VERSION ""

NS_ :

BS_:

BU_: CH DIPF DIPR ETH FC HVI HVS PARTY SDCV VEH VIRT

BO_ 832 VCFRONT_alertMatrix: 8 VEH
 SG_ VCFRONT_a120_DI_DRIVE_MIA m1 : 63|1@1+ (1,0) [0|1] ""  gtw
 SG_ VCFRONT_a180_12VNotSupported m2 : 63|1@1+ (1,0) [0|1] ""  gtw
 SG_ VCFRONT_a060_engineeringBuild m0 : 63|1@1+ (1,0) [0|1] ""  gtw
 SG_ VCFRONT_a119_SCCM_MIA m1 : 62|1@1+ (1,0) [0|1] ""  gtw
 SG_ VCFRONT_a179_highLVAmpsIntoPCS m2 : 62|1@1+ (1,0) [0|1] ""  gtw
 SG_ VCFRONT_a059_inputResistanceHigh m0 : 62|1@1+ (1,0) [0|1] ""  gtw
 SG_ VCFRONT_a239_thmlFanChipComms m3 : 62|1@1+ (1,0) [0|1] ""  gtw
 SG_ VCFRONT_a238_pumpPtChipComms m3 : 61|1@1+ (1,0) [0|1] ""  gtw
 SG_ VCFRONT_a118_VCFRONT_MIA m1 : 61|1@1+ (1,0) [0|1] ""  gtw
 SG_ VCFRONT_a117_VCLEFT_MIA m1 : 60|1@1+ (1,0) [0|1] ""  gtw
 SG_ VCFRONT_a177_mcuAudioEFuseFault m2 : 60|1@1+ (1,0) [0|1] ""  gtw
 SG_ VCFRONT_a237_pumpBatChipComms m3 : 60|1@1+ (1,0) [0|1] ""  gtw
 SG_ VCFRONT_a176_vehicleInSelfTest m2 : 59|1@1+ (1,0) [0|1] ""  gtw
 SG_ VCFRONT_a236_batTempSnsIrrationa m3 : 59|1@1+ (1,0) [0|1] ""  gtw
 SG_ VCFRONT_a116_VCRIGHT_MIA m1 : 59|1@1+ (1,0) [0|1] ""  gtw
 SG_ VCFRONT_a175_ambientTempSns m2 : 58|1@1+ (1,0) [0|1] ""  gtw
 SG_ VCFRONT_a235_ptTempSnsIrrational m3 : 58|1@1+ (1,0) [0|1] ""  gtw
 SG_ VCFRONT_a115_VCSEC_MIA m1 : 58|1@1+ (1,0) [0|1] ""  gtw
 SG_ VCFRONT_a114_ESP_MIA m1 : 57|1@1+ (1,0) [0|1] ""  gtw
 SG_ VCFRONT_a234_autopilot2EFuseFaul m3 : 57|1@1+ (1,0) [0|1] ""  gtw
 SG_ VCFRONT_a174_driveNotAuthed m2 : 57|1@1+ (1,0) [0|1] ""  gtw
 SG_ VCFRONT_a113_UI_MIA m1 : 56|1@1+ (1,0) [0|1] ""  gtw
 SG_ VCFRONT_a173_HVBlckdByMsmtch m2 : 56|1@1+ (1,0) [0|1] ""  gtw
 SG_ VCFRONT_a233_autopilot1EFuseFaul m3 : 56|1@1+ (1,0) [0|1] ""  gtw
 SG_ VCFRONT_a112_EPBL_MIA m1 : 55|1@1+ (1,0) [0|1] ""  gtw
 SG_ VCFRONT_a172_wsteHtBlckdByMsmtch m2 : 55|1@1+ (1,0) [0|1] ""  gtw
 SG_ VCFRONT_a111_EPBR_MIA m1 : 54|1@1+ (1,0) [0|1] ""  gtw
 SG_ VCFRONT_a171_driveBlckdByMsmtch m2 : 54|1@1+ (1,0) [0|1] ""  gtw
 SG_ VCFRONT_a231_12VTempSensShort m3 : 54|1@1+ (1,0) [0|1] ""  gtw
 SG_ VCFRONT_a170_hcmUnderVoltage m2 : 53|1@1+ (1,0) [0|1] ""  gtw
 SG_ VCFRONT_a110_GTW_MIA m1 : 53|1@1+ (1,0) [0|1] ""  gtw
 SG_ VCFRONT_a230_thmlFanFbkSanity m3 : 53|1@1+ (1,0) [0|1] ""  gtw
 SG_ VCFRONT_a169_hcmPhaseEnableFail m2 : 52|1@1+ (1,0) [0|1] ""  gtw
 SG_ VCFRONT_a349_vbatFusedFastTripSl m5 : 52|1@1+ (1,0) [0|1] ""  gtw
 SG_ VCFRONT_a229_pumpPtFbkSanity m3 : 52|1@1+ (1,0) [0|1] ""  gtw
 SG_ VCFRONT_a109_RCM_MIA m1 : 52|1@1+ (1,0) [0|1] ""  gtw
 SG_ VCFRONT_a108_DIS_MIA m1 : 51|1@1+ (1,0) [0|1] ""  gtw
 SG_ VCFRONT_a228_pumpBatFbkSanity m3 : 51|1@1+ (1,0) [0|1] ""  gtw
 SG_ VCFRONT_a348_espFastTripSlope m5 : 51|1@1+ (1,0) [0|1] ""  gtw
 SG_ VCFRONT_a168_hcmShortToVBAT m2 : 51|1@1+ (1,0) [0|1] ""  gtw
 SG_ VCFRONT_a107_BMS_MIA m1 : 50|1@1+ (1,0) [0|1] ""  gtw
 SG_ VCFRONT_a167_leftHCMMIA m2 : 50|1@1+ (1,0) [0|1] ""  gtw
 SG_ VCFRONT_a347_iboosterFastTripSlo m5 : 50|1@1+ (1,0) [0|1] ""  gtw
 SG_ VCFRONT_a346_epas3sFastTripSlope m5 : 49|1@1+ (1,0) [0|1] ""  gtw
 SG_ VCFRONT_a106_PCS_MIA m1 : 49|1@1+ (1,0) [0|1] ""  gtw
 SG_ VCFRONT_a046_Task1000msError m0 : 49|1@1+ (1,0) [0|1] ""  gtw
 SG_ VCFRONT_a226_railAPoweredForFrun m3 : 49|1@1+ (1,0) [0|1] ""  gtw
 SG_ VCFRONT_a166_rightHCMMIA m2 : 49|1@1+ (1,0) [0|1] ""  gtw
 SG_ VCFRONT_a045_Task100msError m0 : 48|1@1+ (1,0) [0|1] ""  gtw
 SG_ VCFRONT_a165_unxpctdEFuseLckout m2 : 48|1@1+ (1,0) [0|1] ""  gtw
 SG_ VCFRONT_a225_driveBlckdByShowroo m3 : 48|1@1+ (1,0) [0|1] ""  gtw
 SG_ VCFRONT_a345_epas3pFastTripSlope m5 : 48|1@1+ (1,0) [0|1] ""  gtw
 SG_ VCFRONT_a105_TAS_MIA m1 : 48|1@1+ (1,0) [0|1] ""  gtw
 SG_ VCFRONT_a224_revBatChrgPmpFault m3 : 47|1@1+ (1,0) [0|1] ""  gtw
 SG_ VCFRONT_a164_eFuseLckoutMissing m2 : 47|1@1+ (1,0) [0|1] ""  gtw
 SG_ VCFRONT_a344_pcsFastTripSlope m5 : 47|1@1+ (1,0) [0|1] ""  gtw
 SG_ VCFRONT_a044_Task10msError m0 : 47|1@1+ (1,0) [0|1] ""  gtw
 SG_ VCFRONT_a104_DAS_MIA m1 : 47|1@1+ (1,0) [0|1] ""  gtw
 SG_ VCFRONT_a283_thmlFanLimitedByCur m4 : 46|1@1+ (1,0) [0|1] ""  gtw
 SG_ VCFRONT_a103_CP_MIA m1 : 46|1@1+ (1,0) [0|1] ""  gtw
 SG_ VCFRONT_a343_vcrightFastTripSlop m5 : 46|1@1+ (1,0) [0|1] ""  gtw
 SG_ VCFRONT_a043_Task1msError m0 : 46|1@1+ (1,0) [0|1] ""  gtw
 SG_ VCFRONT_a223_12VTempSensDiscnect m3 : 46|1@1+ (1,0) [0|1] ""  gtw
 SG_ VCFRONT_a042_HighStackUsage m0 : 45|1@1+ (1,0) [0|1] ""  gtw
 SG_ VCFRONT_a102_PTC_MIA m1 : 45|1@1+ (1,0) [0|1] ""  gtw
 SG_ VCFRONT_a342_vcleftFastTripSlope m5 : 45|1@1+ (1,0) [0|1] ""  gtw
 SG_ VCFRONT_a222_rightTurnLightFault m3 : 45|1@1+ (1,0) [0|1] ""  gtw
 SG_ VCFRONT_a041_HighCPULoad m0 : 44|1@1+ (1,0) [0|1] ""  gtw
 SG_ VCFRONT_a101_PM_MIA m1 : 44|1@1+ (1,0) [0|1] ""  gtw
 SG_ VCFRONT_a161_compressorSelfFault m2 : 44|1@1+ (1,0) [0|1] ""  gtw
 SG_ VCFRONT_a221_leftTurnLightFault m3 : 44|1@1+ (1,0) [0|1] ""  gtw
 SG_ VCFRONT_a341_vbatFusedFastTripOC m5 : 44|1@1+ (1,0) [0|1] ""  gtw
 SG_ VCFRONT_a160_compressorInhibited m2 : 43|1@1+ (1,0) [0|1] ""  gtw
 SG_ VCFRONT_a100_CANbus_MIA m1 : 43|1@1+ (1,0) [0|1] ""  gtw
 SG_ VCFRONT_a340_espFastTripOCMax m5 : 43|1@1+ (1,0) [0|1] ""  gtw
 SG_ VCFRONT_a220_reverseBatteryFault m3 : 43|1@1+ (1,0) [0|1] ""  gtw
 SG_ VCFRONT_a099_PARK_MIA m1 : 42|1@1+ (1,0) [0|1] ""  gtw
 SG_ VCFRONT_a159_fiveWayValveFault m2 : 42|1@1+ (1,0) [0|1] ""  gtw
 SG_ VCFRONT_a219_12VVoltFloorRchd m3 : 42|1@1+ (1,0) [0|1] ""  gtw
 SG_ VCFRONT_a339_iboosterFastTripOCM m5 : 42|1@1+ (1,0) [0|1] ""  gtw
 SG_ VCFRONT_a338_epas3sFastTripOCMax m5 : 41|1@1+ (1,0) [0|1] ""  gtw
 SG_ VCFRONT_a158_louverDisconnected m2 : 41|1@1+ (1,0) [0|1] ""  gtw
 SG_ VCFRONT_a098_DI_THERMAL_MIA m1 : 41|1@1+ (1,0) [0|1] ""  gtw
 SG_ VCFRONT_a157_louverBreakage m2 : 40|1@1+ (1,0) [0|1] ""  gtw
 SG_ VCFRONT_a337_epas3pFastTripOCMax m5 : 40|1@1+ (1,0) [0|1] ""  gtw
 SG_ VCFRONT_a097_CMP_MIA m1 : 40|1@1+ (1,0) [0|1] ""  gtw
 SG_ VCFRONT_a156_louverBlockage m2 : 39|1@1+ (1,0) [0|1] ""  gtw
 SG_ VCFRONT_a336_pcsFastTripOCMax m5 : 39|1@1+ (1,0) [0|1] ""  gtw
 SG_ VCFRONT_a335_vcrightFastTripOCMa m5 : 38|1@1+ (1,0) [0|1] ""  gtw
 SG_ VCFRONT_a215_airCompDriverFault m3 : 38|1@1+ (1,0) [0|1] ""  gtw
 SG_ VCFRONT_a214_airCompUnderCurrent m3 : 37|1@1+ (1,0) [0|1] ""  gtw
 SG_ VCFRONT_a334_vcleftFastTripOCMax m5 : 37|1@1+ (1,0) [0|1] ""  gtw
 SG_ VCFRONT_a333_vbatFusedSlowTripOC m5 : 36|1@1+ (1,0) [0|1] ""  gtw
 SG_ VCFRONT_a213_12VOvercharge m3 : 36|1@1+ (1,0) [0|1] ""  gtw
 SG_ VCFRONT_a212_IBSOverTemp m3 : 35|1@1+ (1,0) [0|1] ""  gtw
 SG_ VCFRONT_a152_thmlFanLowRPMCBang m2 : 35|1@1+ (1,0) [0|1] ""  gtw
 SG_ VCFRONT_a332_espSlowTripOC m5 : 35|1@1+ (1,0) [0|1] ""  gtw
 SG_ VCFRONT_a151_pumpPtLowRPMCBang m2 : 34|1@1+ (1,0) [0|1] ""  gtw
 SG_ VCFRONT_a211_I2CFault m3 : 34|1@1+ (1,0) [0|1] ""  gtw
 SG_ VCFRONT_a031_UDSActive m0 : 34|1@1+ (1,0) [0|1] ""  gtw
 SG_ VCFRONT_a331_iboosterSlowTripOC m5 : 34|1@1+ (1,0) [0|1] ""  gtw
 SG_ VCFRONT_a330_epas3sSlowTripOC m5 : 33|1@1+ (1,0) [0|1] ""  gtw
 SG_ VCFRONT_a030_ECULogUploadRequest m0 : 33|1@1+ (1,0) [0|1] ""  gtw
 SG_ VCFRONT_a210_fiveWayValveCalib m3 : 33|1@1+ (1,0) [0|1] ""  gtw
 SG_ VCFRONT_a150_pumpBatLowRPMCBang m2 : 33|1@1+ (1,0) [0|1] ""  gtw
 SG_ VCFRONT_a329_epas3pSlowTripOC m5 : 32|1@1+ (1,0) [0|1] ""  gtw
 SG_ VCFRONT_a149_BLEFrontPowerCycled m2 : 32|1@1+ (1,0) [0|1] ""  gtw
 SG_ VCFRONT_a269_partialLoadShed m4 : 32|1@1+ (1,0) [0|1] ""  gtw
 SG_ VCFRONT_a209_brakeFluidSNA m3 : 32|1@1+ (1,0) [0|1] ""  gtw
 SG_ VCFRONT_a208_brakeFluidLow m3 : 31|1@1+ (1,0) [0|1] ""  gtw
 SG_ VCFRONT_a328_pcsSlowTripOC m5 : 31|1@1+ (1,0) [0|1] ""  gtw
 SG_ VCFRONT_a268_vbatFusedVoltageMis m4 : 31|1@1+ (1,0) [0|1] ""  gtw
 SG_ VCFRONT_a148_thmlFanSoftStall m2 : 31|1@1+ (1,0) [0|1] ""  gtw
 SG_ VCFRONT_a267_EPAS3sVoltageMismat m4 : 30|1@1+ (1,0) [0|1] ""  gtw
 SG_ VCFRONT_a147_pumpPtSoftStall m2 : 30|1@1+ (1,0) [0|1] ""  gtw
 SG_ VCFRONT_a207_vbatFusdSelfTestFai m3 : 30|1@1+ (1,0) [0|1] ""  gtw
 SG_ VCFRONT_a327_vcrightSlowTripOC m5 : 30|1@1+ (1,0) [0|1] ""  gtw
 SG_ VCFRONT_a146_pumpBatSoftStall m2 : 29|1@1+ (1,0) [0|1] ""  gtw
 SG_ VCFRONT_a266_EPAS3pVoltageMismat m4 : 29|1@1+ (1,0) [0|1] ""  gtw
 SG_ VCFRONT_a326_vcleftSlowTripOC m5 : 29|1@1+ (1,0) [0|1] ""  gtw
 SG_ VCFRONT_a206_espSelfTestFail m3 : 29|1@1+ (1,0) [0|1] ""  gtw
 SG_ VCFRONT_a265_ESPVoltageMismatch m4 : 28|1@1+ (1,0) [0|1] ""  gtw
 SG_ VCFRONT_a205_iBoosterSelfTestFai m3 : 28|1@1+ (1,0) [0|1] ""  gtw
 SG_ VCFRONT_a145_thmlFanICTransFault m2 : 28|1@1+ (1,0) [0|1] ""  gtw
 SG_ VCFRONT_a325_vbatFusedOvertempMa m5 : 28|1@1+ (1,0) [0|1] ""  gtw
 SG_ VCFRONT_a264_iBoosterVoltageMism m4 : 27|1@1+ (1,0) [0|1] ""  gtw
 SG_ VCFRONT_a144_pumpPtICTransFault m2 : 27|1@1+ (1,0) [0|1] ""  gtw
 SG_ VCFRONT_a324_espOvertempMax m5 : 27|1@1+ (1,0) [0|1] ""  gtw
 SG_ VCFRONT_a204_epas3sSelfTestFail m3 : 27|1@1+ (1,0) [0|1] ""  gtw
 SG_ VCFRONT_a263_pcsVoltageMismatch m4 : 26|1@1+ (1,0) [0|1] ""  gtw
 SG_ VCFRONT_a143_pumpBatICTransFault m2 : 26|1@1+ (1,0) [0|1] ""  gtw
 SG_ VCFRONT_a203_epas3pSelfTestFail m3 : 26|1@1+ (1,0) [0|1] ""  gtw
 SG_ VCFRONT_a323_iboosterOvertempMax m5 : 26|1@1+ (1,0) [0|1] ""  gtw
 SG_ VCFRONT_a262_vcrightVoltageMisma m4 : 25|1@1+ (1,0) [0|1] ""  gtw
 SG_ VCFRONT_a202_pcsSelfTestFail m3 : 25|1@1+ (1,0) [0|1] ""  gtw
 SG_ VCFRONT_a322_epas3sOvertempMax m5 : 25|1@1+ (1,0) [0|1] ""  gtw
 SG_ VCFRONT_a142_exvMotorFault m2 : 25|1@1+ (1,0) [0|1] ""  gtw
 SG_ VCFRONT_a022_TaskInitError m0 : 25|1@1+ (1,0) [0|1] ""  gtw
 SG_ VCFRONT_a141_coolantTempBatSns m2 : 24|1@1+ (1,0) [0|1] ""  gtw
 SG_ VCFRONT_a021_TaskSchedulerError m0 : 24|1@1+ (1,0) [0|1] ""  gtw
 SG_ VCFRONT_a201_vcrightSelfTestFail m3 : 24|1@1+ (1,0) [0|1] ""  gtw
 SG_ VCFRONT_a261_vcleftVoltageMismat m4 : 24|1@1+ (1,0) [0|1] ""  gtw
 SG_ VCFRONT_a321_epas3pOvertempMax m5 : 24|1@1+ (1,0) [0|1] ""  gtw
 SG_ VCFRONT_a200_vcleftSelfTestFail m3 : 23|1@1+ (1,0) [0|1] ""  gtw
 SG_ VCFRONT_a260_dead12VBattery m4 : 23|1@1+ (1,0) [0|1] ""  gtw
 SG_ VCFRONT_a320_pcsOvertempMax m5 : 23|1@1+ (1,0) [0|1] ""  gtw
 SG_ VCFRONT_a140_coolantTempPtSns m2 : 23|1@1+ (1,0) [0|1] ""  gtw
 SG_ VCFRONT_a139_refrigSuctPresSns m2 : 22|1@1+ (1,0) [0|1] ""  gtw
 SG_ VCFRONT_a319_vcrightOvertempMax m5 : 22|1@1+ (1,0) [0|1] ""  gtw
 SG_ VCFRONT_a199_PRVCANUndertrminate m3 : 22|1@1+ (1,0) [0|1] ""  gtw
 SG_ VCFRONT_a259_12vVoltageDropOnHig m4 : 22|1@1+ (1,0) [0|1] ""  gtw
 SG_ VCFRONT_a198_PRVCANOverterminate m3 : 21|1@1+ (1,0) [0|1] ""  gtw
 SG_ VCFRONT_a138_refrigSuctTempSns m2 : 21|1@1+ (1,0) [0|1] ""  gtw
 SG_ VCFRONT_a258_resistanceEstimatio m4 : 21|1@1+ (1,0) [0|1] ""  gtw
 SG_ VCFRONT_a318_vcleftOvertempMax m5 : 21|1@1+ (1,0) [0|1] ""  gtw
 SG_ VCFRONT_a317_vbatFusedOvertempSl m5 : 20|1@1+ (1,0) [0|1] ""  gtw
 SG_ VCFRONT_a257_portExpanderVOR m4 : 20|1@1+ (1,0) [0|1] ""  gtw
 SG_ VCFRONT_a137_refrigDischPresSns m2 : 20|1@1+ (1,0) [0|1] ""  gtw
 SG_ VCFRONT_a196_discnctd12VBattery m3 : 19|1@1+ (1,0) [0|1] ""  gtw
 SG_ VCFRONT_a316_espOvertempSlope m5 : 19|1@1+ (1,0) [0|1] ""  gtw
 SG_ VCFRONT_a256_compTornShaftSeal m4 : 19|1@1+ (1,0) [0|1] ""  gtw
 SG_ VCFRONT_a136_refrigDischTempSns m2 : 19|1@1+ (1,0) [0|1] ""  gtw
 SG_ VCFRONT_a255_pumpPtStopped m4 : 18|1@1+ (1,0) [0|1] ""  gtw
 SG_ VCFRONT_a015_NVMMAlert m0 : 18|1@1+ (1,0) [0|1] ""  gtw
 SG_ VCFRONT_a135_coolantLevelLow m2 : 18|1@1+ (1,0) [0|1] ""  gtw
 SG_ VCFRONT_a315_iboosterOvertempSlo m5 : 18|1@1+ (1,0) [0|1] ""  gtw
 SG_ VCFRONT_a195_drveBlckdVltgeTooHg m3 : 18|1@1+ (1,0) [0|1] ""  gtw
 SG_ VCFRONT_a314_epas3sOvertempSlope m5 : 17|1@1+ (1,0) [0|1] ""  gtw
 SG_ VCFRONT_a134_fusedHighEFuseTrip m2 : 17|1@1+ (1,0) [0|1] ""  gtw
 SG_ VCFRONT_a254_pumpBatStopped m4 : 17|1@1+ (1,0) [0|1] ""  gtw
 SG_ VCFRONT_a194_iBoosterRetry m3 : 17|1@1+ (1,0) [0|1] ""  gtw
 SG_ VCFRONT_a013_AlertManagerFault m0 : 16|1@1+ (1,0) [0|1] ""  gtw
 SG_ VCFRONT_a133_espEFuseTrip m2 : 16|1@1+ (1,0) [0|1] ""  gtw
 SG_ VCFRONT_a193_mcuAudioRetry m3 : 16|1@1+ (1,0) [0|1] ""  gtw
 SG_ VCFRONT_a253_maxChrgeSssionTmeou m4 : 16|1@1+ (1,0) [0|1] ""  gtw
 SG_ VCFRONT_a313_epas3pOvertempSlope m5 : 16|1@1+ (1,0) [0|1] ""  gtw
 SG_ VCFRONT_a132_iBoosterEFuseTrip m2 : 15|1@1+ (1,0) [0|1] ""  gtw
 SG_ VCFRONT_a252_frontControllerWake m4 : 15|1@1+ (1,0) [0|1] ""  gtw
 SG_ VCFRONT_a192_criticalLoadShed m3 : 15|1@1+ (1,0) [0|1] ""  gtw
 SG_ VCFRONT_a012_CPUReset m0 : 15|1@1+ (1,0) [0|1] ""  gtw
 SG_ VCFRONT_a312_pcsOvertempSlope m5 : 15|1@1+ (1,0) [0|1] ""  gtw
 SG_ VCFRONT_a191_exitDriveLow12V m3 : 14|1@1+ (1,0) [0|1] ""  gtw
 SG_ VCFRONT_a251_UIWakeupTrigger m4 : 14|1@1+ (1,0) [0|1] ""  gtw
 SG_ VCFRONT_a311_vcrightOvertempSlop m5 : 14|1@1+ (1,0) [0|1] ""  gtw
 SG_ VCFRONT_a131_epas3sEFuseTrip m2 : 14|1@1+ (1,0) [0|1] ""  gtw
 SG_ VCFRONT_a310_vcleftOvertempSlope m5 : 13|1@1+ (1,0) [0|1] ""  gtw
 SG_ VCFRONT_a250_headlampsNotAimed m4 : 13|1@1+ (1,0) [0|1] ""  gtw
 SG_ VCFRONT_a010_ExtSupplyVoltError m0 : 13|1@1+ (1,0) [0|1] ""  gtw
 SG_ VCFRONT_a130_epas3pEFuseTrip m2 : 13|1@1+ (1,0) [0|1] ""  gtw
 SG_ VCFRONT_a129_pcsEFuseTrip m2 : 12|1@1+ (1,0) [0|1] ""  gtw
 SG_ VCFRONT_a189_IBSMIA m3 : 12|1@1+ (1,0) [0|1] ""  gtw
 SG_ VCFRONT_a249_fiveWayValveBadMode m4 : 12|1@1+ (1,0) [0|1] ""  gtw
 SG_ VCFRONT_a188_sleepFailed m3 : 11|1@1+ (1,0) [0|1] ""  gtw
 SG_ VCFRONT_a128_vcrightEFuseTrip m2 : 11|1@1+ (1,0) [0|1] ""  gtw
 SG_ VCFRONT_a248_voltageOutOfSpec m4 : 11|1@1+ (1,0) [0|1] ""  gtw
 SG_ VCFRONT_a127_vcleftEFuseTrip m2 : 10|1@1+ (1,0) [0|1] ""  gtw
 SG_ VCFRONT_a187_busesNotSleeping m3 : 10|1@1+ (1,0) [0|1] ""  gtw
 SG_ VCFRONT_a247_evapSolenoidFault m4 : 10|1@1+ (1,0) [0|1] ""  gtw
 SG_ VCFRONT_a246_pump2EFuseFault m4 : 9|1@1+ (1,0) [0|1] ""  gtw
 SG_ VCFRONT_a126_thmlFanICWarning m2 : 9|1@1+ (1,0) [0|1] ""  gtw
 SG_ VCFRONT_a186_noDriveChgCableCon m3 : 9|1@1+ (1,0) [0|1] ""  gtw
 SG_ VCFRONT_a125_thmlFanICLatchFault m2 : 8|1@1+ (1,0) [0|1] ""  gtw
 SG_ VCFRONT_a245_pump1EFuseFault m4 : 8|1@1+ (1,0) [0|1] ""  gtw
 SG_ VCFRONT_a185_washerFluidLow m3 : 8|1@1+ (1,0) [0|1] ""  gtw
 SG_ VCFRONT_a244_sleepBypassFault m4 : 7|1@1+ (1,0) [0|1] ""  gtw
 SG_ VCFRONT_a064_busSleepReqTimeout m1 : 7|1@1+ (1,0) [0|1] ""  gtw
 SG_ VCFRONT_a124_pumpPtICWarning m2 : 7|1@1+ (1,0) [0|1] ""  gtw
 SG_ VCFRONT_a123_pumpPtICLatchFault m2 : 6|1@1+ (1,0) [0|1] ""  gtw
 SG_ VCFRONT_a183_low12VCapacity m3 : 6|1@1+ (1,0) [0|1] ""  gtw
 SG_ VCFRONT_a063_SwitchFault m1 : 6|1@1+ (1,0) [0|1] ""  gtw
 SG_ VCFRONT_a003_SWAssertion m0 : 6|1@1+ (1,0) [0|1] ""  gtw
 SG_ VCFRONT_a243_12VOverchargeInstc m4 : 6|1@1+ (1,0) [0|1] ""  gtw
 SG_ VCFRONT_a002_PowerLossReset m0 : 5|1@1+ (1,0) [0|1] ""  gtw
 SG_ VCFRONT_a062_XCPWasConnected m1 : 5|1@1+ (1,0) [0|1] ""  gtw
 SG_ VCFRONT_a182_replace12VBattery m3 : 5|1@1+ (1,0) [0|1] ""  gtw
 SG_ VCFRONT_a302_wiperCommError m5 : 5|1@1+ (1,0) [0|1] ""  gtw
 SG_ VCFRONT_a122_pumpBatICWarning m2 : 5|1@1+ (1,0) [0|1] ""  gtw
 SG_ VCFRONT_a061_XCPConnected m1 : 4|1@1+ (1,0) [0|1] ""  gtw
 SG_ VCFRONT_a121_pumpBatICLatchFault m2 : 4|1@1+ (1,0) [0|1] ""  gtw
 SG_ VCFRONT_a001_WatchdogReset m0 : 4|1@1+ (1,0) [0|1] ""  gtw
 SG_ VCFRONT_a301_wipersFactoryDisabl m5 : 4|1@1+ (1,0) [0|1] ""  gtw
 SG_ VCFRONT_matrixIndex M : 0|4@1+ (1,0) [0|15] ""  gtw

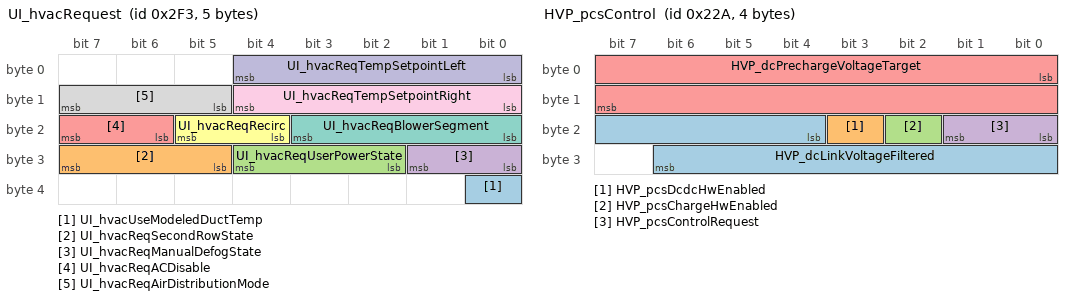
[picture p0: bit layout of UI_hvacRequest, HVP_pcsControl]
BO_ 755 UI_hvacRequest: 5 VEH
 SG_ UI_hvacUseModeledDuctTemp : 32|1@1+ (1,0) [0|1] ""  X
 SG_ UI_hvacReqSecondRowState : 29|3@1+ (1,0) [0|4] ""  vcright
 SG_ UI_hvacReqUserPowerState : 26|3@1+ (1,0) [0|4] ""  vcfront
 SG_ UI_hvacReqManualDefogState : 24|2@1+ (1,0) [0|2] ""  aps
 SG_ UI_hvacReqACDisable : 22|2@1+ (1,0) [0|2] ""  vcright
 SG_ UI_hvacReqRecirc : 20|2@1+ (1,0) [0|2] ""  vcright
 SG_ UI_hvacReqBlowerSegment : 16|4@1+ (1,0) [0|11] ""  vcright
 SG_ UI_hvacReqAirDistributionMode : 13|3@1+ (1,0) [0|7] ""  vcright
 SG_ UI_hvacReqTempSetpointRight : 8|5@1+ (0.5,15) [15|28] "degC"  vcright
 SG_ UI_hvacReqTempSetpointLeft : 0|5@1+ (0.5,15) [15|28] "degC"  vcright

BO_ 554 HVP_pcsControl: 4 VEH
 SG_ HVP_dcLinkVoltageFiltered : 20|11@1- (1,0) [-550|550] "V"  X
 SG_ HVP_pcsDcdcHwEnabled : 19|1@1+ (1,0) [0|1] ""  gtw
 SG_ HVP_pcsChargeHwEnabled : 18|1@1+ (1,0) [0|1] ""  gtw
 SG_ HVP_pcsControlRequest : 16|2@1+ (1,0) [0|3] ""  dbg
 SG_ HVP_dcPrechargeVoltageTarget : 0|16@1- (0.1,0) [-550|550] "V"  gtw

BO_ 815 SCM_alertMatrix1: 8 VEH
 SG_ SCM_a064_vehicleCommandTimeout : 63|1@1+ (1,0) [0|1] ""  gtw
 SG_ SCM_a063_canRationality : 62|1@1+ (1,0) [0|1] ""  gtw
 SG_ SCM_a062_unused : 61|1@1+ (1,0) [0|1] ""  gtw
 SG_ SCM_a061_postOutOfService : 60|1@1+ (1,0) [0|1] ""  gtw
 SG_ SCM_a060_swHVIL : 59|1@1+ (1,0) [0|1] ""  gtw
 SG_ SCM_a059_memoryError : 58|1@1+ (1,0) [0|1] ""  gtw
 SG_ SCM_a058_adcRef : 57|1@1+ (1,0) [0|1] ""  gtw
 SG_ SCM_a057_watchdogReset : 56|1@1+ (1,0) [0|1] ""  gtw
 SG_ SCM_a056_stateTransitionDenied : 55|1@1+ (1,0) [0|1] ""  gtw
 SG_ SCM_a055_coolantLevelLow : 54|1@1+ (1,0) [0|1] ""  gtw
 SG_ SCM_a054_pumpRegulation : 53|1@1+ (1,0) [0|1] ""  gtw
 SG_ SCM_a053_unexpectedThermalBehavi : 52|1@1+ (1,0) [0|1] ""  gtw
 SG_ SCM_a052_ambientTempRationality : 51|1@1+ (1,0) [0|1] ""  gtw
 SG_ SCM_a051_cordTempRationality : 50|1@1+ (1,0) [0|1] ""  gtw
 SG_ SCM_a050_coolantTempRationality : 49|1@1+ (1,0) [0|1] ""  gtw
 SG_ SCM_a049_pcbaTempRationality : 48|1@1+ (1,0) [0|1] ""  gtw
 SG_ SCM_a048_ambientOT : 47|1@1+ (1,0) [0|1] ""  gtw
 SG_ SCM_a047_cordOT : 46|1@1+ (1,0) [0|1] ""  gtw
 SG_ SCM_a046_coolantOT : 45|1@1+ (1,0) [0|1] ""  gtw
 SG_ SCM_a045_pcbaOT : 44|1@1+ (1,0) [0|1] ""  gtw
 SG_ SCM_a044_proximityRationality : 43|1@1+ (1,0) [0|1] ""  gtw
 SG_ SCM_a043_pilotRationality : 42|1@1+ (1,0) [0|1] ""  gtw
 SG_ SCM_a042_pilotOutOfRange : 41|1@1+ (1,0) [0|1] ""  gtw
 SG_ SCM_a041_minus12VOutOfRange : 40|1@1+ (1,0) [0|1] ""  gtw
 SG_ SCM_a040_plus12VOutOfRange : 39|1@1+ (1,0) [0|1] ""  gtw
 SG_ SCM_a039_ibatRegulation : 38|1@1+ (1,0) [0|1] ""  gtw
 SG_ SCM_a038_contactorFailedOpen : 37|1@1+ (1,0) [0|1] ""  gtw
 SG_ SCM_a037_outputContactorWelded : 36|1@1+ (1,0) [0|1] ""  gtw
 SG_ SCM_a036_internalContactorWelded : 35|1@1+ (1,0) [0|1] ""  gtw
 SG_ SCM_a035_unexpectedVbusBehavior : 34|1@1+ (1,0) [0|1] ""  gtw
 SG_ SCM_a034_IBatRationality : 33|1@1+ (1,0) [0|1] ""  gtw
 SG_ SCM_a033_VBusRationality : 32|1@1+ (1,0) [0|1] ""  gtw
 SG_ SCM_a032_VBatRationality : 31|1@1+ (1,0) [0|1] ""  gtw
 SG_ SCM_a031_IbatOC : 30|1@1+ (1,0) [0|1] ""  gtw
 SG_ SCM_a030_VbusOV : 29|1@1+ (1,0) [0|1] ""  gtw
 SG_ SCM_a029_VbatOV : 28|1@1+ (1,0) [0|1] ""  gtw
 SG_ SCM_a028_isolationRationality : 27|1@1+ (1,0) [0|1] ""  gtw
 SG_ SCM_a027_externalIsolationLow : 26|1@1+ (1,0) [0|1] ""  gtw
 SG_ SCM_a026_internalIsolationLow : 25|1@1+ (1,0) [0|1] ""  gtw
 SG_ SCM_a025_internalIsolationFault : 24|1@1+ (1,0) [0|1] ""  gtw
 SG_ SCM_a024_emergencyShutdown : 23|1@1+ (1,0) [0|1] ""  gtw
 SG_ SCM_a021_unusedHW21 : 20|1@1+ (1,0) [0|1] ""  gtw
 SG_ SCM_a020_unusedHW20 : 19|1@1+ (1,0) [0|1] ""  gtw
 SG_ SCM_a019_unusedHW19 : 18|1@1+ (1,0) [0|1] ""  gtw
 SG_ SCM_a018_unusedHW18 : 17|1@1+ (1,0) [0|1] ""  gtw
 SG_ SCM_a017_unusedHW17 : 16|1@1+ (1,0) [0|1] ""  gtw
 SG_ SCM_a016_unusedHW16 : 15|1@1+ (1,0) [0|1] ""  gtw
 SG_ SCM_a015_unusedHW15 : 14|1@1+ (1,0) [0|1] ""  gtw
 SG_ SCM_a014_coolantTempHiFoldBk : 13|1@1+ (1,0) [0|1] ""  gtw
 SG_ SCM_a013_cordTempHiFoldBk : 12|1@1+ (1,0) [0|1] ""  gtw
 SG_ SCM_a012_hwIllegalCntrCmdV2 : 11|1@1+ (1,0) [0|1] ""  gtw
 SG_ SCM_a011_hwIllegalCntrCmdInt : 10|1@1+ (1,0) [0|1] ""  gtw
 SG_ SCM_a010_hwIllegalCntrCmdV1 : 9|1@1+ (1,0) [0|1] ""  gtw
 SG_ SCM_a009_hwOpen_V2 : 8|1@1+ (1,0) [0|1] ""  gtw
 SG_ SCM_a008_hwOpen_V1 : 7|1@1+ (1,0) [0|1] ""  gtw
 SG_ SCM_a007_hwWeld_V2 : 6|1@1+ (1,0) [0|1] ""  gtw
 SG_ SCM_a006_hwWeld_V1 : 5|1@1+ (1,0) [0|1] ""  gtw
 SG_ SCM_a005_hwHVIL : 4|1@1+ (1,0) [0|1] ""  gtw
 SG_ SCM_a004_hwVbusOV : 3|1@1+ (1,0) [0|1] ""  gtw
 SG_ SCM_a003_hwCordOT : 2|1@1+ (1,0) [0|1] ""  gtw
 SG_ SCM_a002_hwIbatOC : 1|1@1+ (1,0) [0|1] ""  gtw
 SG_ SCM_a001_hwDSPfault : 0|1@1+ (1,0) [0|1] ""  gtw

BO_ 805 FC_alertMatrix1: 8 VEH
 SG_ FC_a002_scPowerShared : 1|1@1+ (1,0) [0|1] ""  gtw
 SG_ FC_a001_scPostOutOfService : 0|1@1+ (1,0) [0|1] ""  gtw

BO_ 1354 SCS_alertLog: 8 VEH
 SG_ SCS_a069_vStage4 m69 : 52|12@1+ (0.14652014653,0) [0|600] "V"  gtw
 SG_ SCS_a070_vStage4 m70 : 52|12@1+ (0.14652014653,0) [0|600] "V"  gtw
 SG_ SCS_a058_alertData3 m58 : 48|16@1- (1,0) [-32767|32767] "-"  gtw
 SG_ SCS_a013_Ui m13 : 48|16@1- (0.0009765625,0) [-31|31] "-"  gtw
 SG_ SCS_a065_vBat3 m65 : 40|12@1+ (0.14652014653,0) [0|600] "V"  gtw
 SG_ SCS_a066_vBat6 m66 : 40|12@1+ (0.14652014653,0) [0|600] "V"  gtw
 SG_ SCS_a075_avgDecayTime m75 : 40|16@1+ (1,0) [0|65535] "mS"  gtw
 SG_ SCS_a069_vStage3 m69 : 40|12@1+ (0.14652014653,0) [0|600] "V"  gtw
 SG_ SCS_a070_vStage3 m70 : 40|12@1+ (0.14652014653,0) [0|600] "V"  gtw
 SG_ SCS_a068_vBat12 m68 : 40|12@1+ (0.14652014653,0) [0|600] "V"  gtw
 SG_ SCS_a067_vBat9 m67 : 40|12@1+ (0.14652014653,0) [0|600] "V"  gtw
 SG_ SCS_a060_rawHvilStatus m60 : 34|30@1+ (1,0) [0|1073741823] ""  gtw
 SG_ SCS_a060_rawHvilChainNum m60 : 32|2@1+ (1,0) [0|3] ""  gtw
 SG_ SCS_a013_Up m13 : 32|16@1- (0.0009765625,0) [-31|31] "-"  gtw
 SG_ SCS_a075_chargerConfig m75 : 32|8@1+ (1,0) [0|255] ""  gtw
 SG_ SCS_a058_refVoltageLowAvg m58 : 32|16@1+ (4.574e-05,-0.006861) [-0.00686|2.99071] "V"  gtw
 SG_ SCS_a066_vBat5 m66 : 28|12@1+ (0.14652014653,0) [0|600] "V"  gtw
 SG_ SCS_a070_vStage2 m70 : 28|12@1+ (0.14652014653,0) [0|600] "V"  gtw
 SG_ SCS_a069_vStage2 m69 : 28|12@1+ (0.14652014653,0) [0|600] "V"  gtw
 SG_ SCS_a060_hvil2faultCode m60 : 28|4@1+ (1,0) [0|15] ""  gtw
 SG_ SCS_a065_vBat2 m65 : 28|12@1+ (0.14652014653,0) [0|600] "V"  gtw
 SG_ SCS_a074_voltageWithoutRo m74 : 28|12@1+ (0.14652014653,0) [0|600] "V"  gtw
 SG_ SCS_a068_vBat11 m68 : 28|12@1+ (0.14652014653,0) [0|600] "V"  gtw
 SG_ SCS_a067_vBat8 m67 : 28|12@1+ (0.14652014653,0) [0|600] "V"  gtw
 SG_ SCS_a060_hvil2chargerNum m60 : 24|4@1+ (1,0) [0|15] ""  gtw
 SG_ SCS_a060_hvil1faultCode m60 : 20|4@1+ (1,0) [0|15] ""  gtw
 SG_ SCS_a083_currentLimit m83 : 20|16@1+ (0.02,0) [0|1310.7] "A"  gtw
 SG_ SCS_a069_vStage1 m69 : 16|12@1+ (0.14652014653,0) [0|600] "V"  gtw
 SG_ SCS_a070_vStage1 m70 : 16|12@1+ (0.14652014653,0) [0|600] "V"  gtw
 SG_ SCS_a035_vBus m35 : 16|12@1+ (0.14652014653,0) [0|600] "V"  gtw
 SG_ SCS_a081_vLine m81 : 16|12@1+ (0.14652014653,0) [0|600] "V"  gtw
 SG_ SCS_a077_vBat m77 : 16|12@1+ (0.14652014653,0) [0|600] "V"  gtw
 SG_ SCS_a071_chargerMiaMask m71 : 16|16@1+ (1,0) [0|65535] ""  gtw
 SG_ SCS_a067_vBat7 m67 : 16|12@1+ (0.14652014653,0) [0|600] "V"  gtw
 SG_ SCS_a075_decayTime m75 : 16|16@1+ (1,0) [0|65535] "mS"  gtw
 SG_ SCS_a083_chargerNum m83 : 16|4@1+ (1,0) [0|15] ""  gtw
 SG_ SCS_a044_proximityV m44 : 16|16@1+ (0.0001,0) [0|6.5535] "V"  gtw
 SG_ SCS_a065_vBat1 m65 : 16|12@1+ (0.14652014653,0) [0|600] "V"  gtw
 SG_ SCS_a082_vBat m82 : 16|12@1+ (0.14652014653,0) [0|600] "V"  gtw
 SG_ SCS_a013_chgIreq m13 : 16|16@1- (0.02,0) [-655|655] "A"  gtw
 SG_ SCS_a060_hvil1chargerNum m60 : 16|4@1+ (1,0) [0|15] ""  gtw
 SG_ SCS_a079_vBat m79 : 16|12@1+ (0.14652014653,0) [0|600] "V"  gtw
 SG_ SCS_a061_ServiceCode m61 : 16|3@1+ (1,0) [0|7] ""  gtw
 SG_ SCS_a058_refVoltageHighAvg m58 : 16|16@1+ (4.574e-05,-0.006861) [-0.00686|2.99071] "V"  gtw
 SG_ SCS_a066_vBat4 m66 : 16|12@1+ (0.14652014653,0) [0|600] "V"  gtw
 SG_ SCS_a068_vBat10 m68 : 16|12@1+ (0.14652014653,0) [0|600] "V"  gtw
 SG_ SCS_a074_voltageWithRo m74 : 16|12@1+ (0.14652014653,0) [0|600] "V"  gtw
 SG_ SCS_alertType : 15|1@1+ (1,0) [0|1] ""  gtw
 SG_ SCS_alertID M : 0|15@1+ (1,0) [0|128] ""  gtw

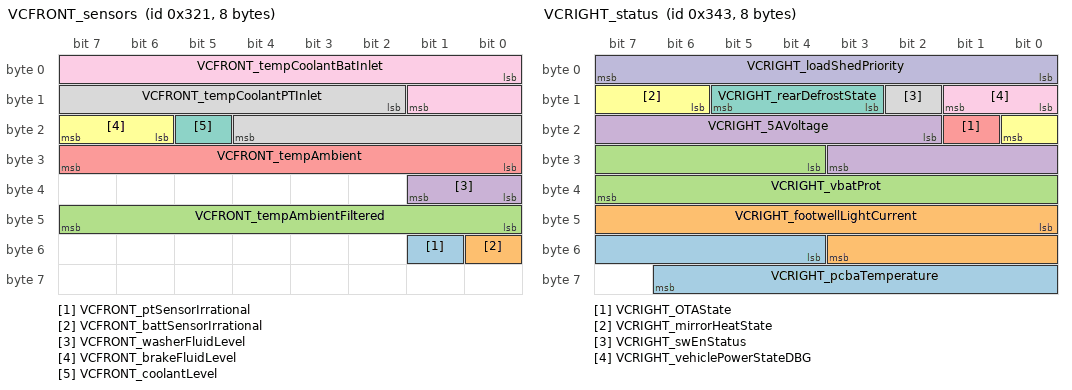
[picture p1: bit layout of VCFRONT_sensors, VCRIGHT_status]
BO_ 801 VCFRONT_sensors: 8 VEH
 SG_ VCFRONT_ptSensorIrrational : 49|1@1+ (1,0) [0|1] ""  X
 SG_ VCFRONT_battSensorIrrational : 48|1@1+ (1,0) [0|1] ""  X
 SG_ VCFRONT_tempAmbientFiltered : 40|8@1+ (0.5,-40) [-40|80] "degC"  bms
 SG_ VCFRONT_washerFluidLevel : 32|2@1+ (1,0) [0|2] ""  X
 SG_ VCFRONT_tempAmbient : 24|8@1+ (0.5,-40) [-40|80] "degC"  das
 SG_ VCFRONT_brakeFluidLevel : 22|2@1+ (1,0) [0|2] ""  gtw
 SG_ VCFRONT_coolantLevel : 21|1@1+ (1,0) [0|1] ""  aps
 SG_ VCFRONT_tempCoolantPTInlet : 10|11@1+ (0.125,-40) [-40|200] "degC"  bms
 SG_ VCFRONT_tempCoolantBatInlet : 0|10@1+ (0.125,-40) [-40|85] "degC"  bms

BO_ 835 VCRIGHT_status: 8 VEH
 SG_ VCRIGHT_pcbaTemperature : 52|11@1+ (0.125,-40) [-40|150] "degC"  gtw
 SG_ VCRIGHT_footwellLightCurrent : 40|12@1- (0.1,0) [-204.8|204.7] "mA"  X
 SG_ VCRIGHT_vbatProt : 28|12@1+ (0.005443676098,0) [0|22.29185] "V"  gtw
 SG_ VCRIGHT_5AVoltage : 18|10@1+ (0.005443676098,0) [0|5.56888] "V"  gtw
 SG_ VCRIGHT_OTAState : 17|1@1+ (1,0) [0|1] ""  gtw
 SG_ VCRIGHT_mirrorHeatState : 14|3@1+ (1,0) [0|4] ""  X
 SG_ VCRIGHT_rearDefrostState : 11|3@1+ (1,0) [0|4] ""  gtw
 SG_ VCRIGHT_swEnStatus : 10|1@1+ (1,0) [0|1] ""  gtw
 SG_ VCRIGHT_vehiclePowerStateDBG : 8|2@1+ (1,0) [0|3] ""  gtw
 SG_ VCRIGHT_loadShedPriority : 0|8@1+ (1,0) [0|255] ""  X

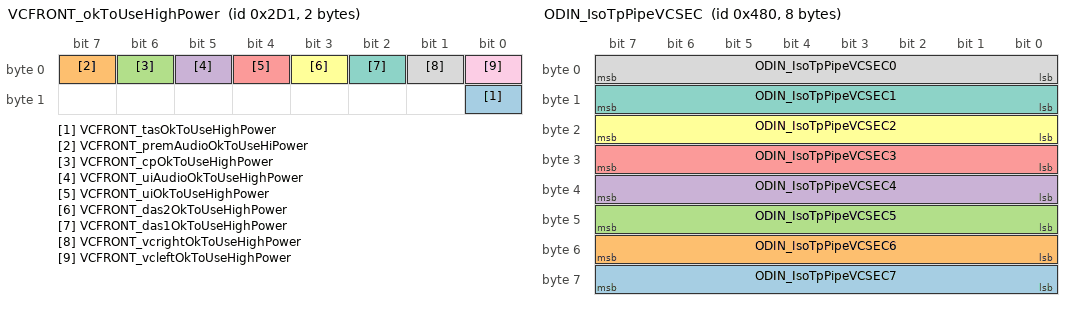
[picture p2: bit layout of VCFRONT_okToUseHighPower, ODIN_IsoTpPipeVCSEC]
BO_ 721 VCFRONT_okToUseHighPower: 2 VEH
 SG_ VCFRONT_tasOkToUseHighPower : 8|1@1+ (1,0) [0|1] ""  gtw
 SG_ VCFRONT_premAudioOkToUseHiPower : 7|1@1+ (1,0) [0|1] ""  gtw
 SG_ VCFRONT_cpOkToUseHighPower : 6|1@1+ (1,0) [0|1] ""  bms
 SG_ VCFRONT_uiAudioOkToUseHighPower : 5|1@1+ (1,0) [0|1] ""  gtw
 SG_ VCFRONT_uiOkToUseHighPower : 4|1@1+ (1,0) [0|1] ""  gtw
 SG_ VCFRONT_das2OkToUseHighPower : 3|1@1+ (1,0) [0|1] ""  aps
 SG_ VCFRONT_das1OkToUseHighPower : 2|1@1+ (1,0) [0|1] ""  aps
 SG_ VCFRONT_vcrightOkToUseHighPower : 1|1@1+ (1,0) [0|1] ""  epbl
 SG_ VCFRONT_vcleftOkToUseHighPower : 0|1@1+ (1,0) [0|1] ""  epbl

BO_ 1152 ODIN_IsoTpPipeVCSEC: 8 VEH
 SG_ ODIN_IsoTpPipeVCSEC7 : 63|8@0+ (1,0) [0|255] ""  vcsec
 SG_ ODIN_IsoTpPipeVCSEC6 : 55|8@0+ (1,0) [0|255] ""  vcsec
 SG_ ODIN_IsoTpPipeVCSEC5 : 47|8@0+ (1,0) [0|255] ""  vcsec
 SG_ ODIN_IsoTpPipeVCSEC4 : 39|8@0+ (1,0) [0|255] ""  vcsec
 SG_ ODIN_IsoTpPipeVCSEC3 : 31|8@0+ (1,0) [0|255] ""  vcsec
 SG_ ODIN_IsoTpPipeVCSEC2 : 23|8@0+ (1,0) [0|255] ""  vcsec
 SG_ ODIN_IsoTpPipeVCSEC1 : 15|8@0+ (1,0) [0|255] ""  vcsec
 SG_ ODIN_IsoTpPipeVCSEC0 : 7|8@0+ (1,0) [0|255] ""  vcsec

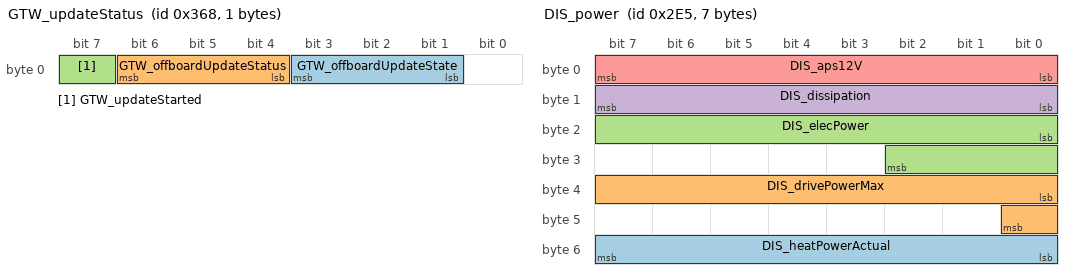
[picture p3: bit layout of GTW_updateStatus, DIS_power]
BO_ 872 GTW_updateStatus: 1 VEH
 SG_ GTW_offboardUpdateState : 3|3@0+ (1,0) [0|5] ""  X
 SG_ GTW_offboardUpdateStatus : 6|3@0+ (1,0) [0|7] ""  X
 SG_ GTW_updateStarted : 7|1@0+ (1,0) [0|1] ""  di

BO_ 1294 CP_alertLog: 8 VEH
 SG_ CP_a071_inductiveErrorUnderRange m71 : 62|1@1+ (1,0) [0|1] ""  gtw
 SG_ CP_a071_inductiveErrorOverRange m71 : 61|1@1+ (1,0) [0|1] ""  gtw
 SG_ CP_a065_pilotState m65 : 61|3@1+ (1,0) [0|7] ""  gtw
 SG_ CP_a071_inductiveErrorWatchdog m71 : 60|1@1+ (1,0) [0|1] ""  gtw
 SG_ CP_a068_doorPresentInductive m68 : 60|1@1+ (1,0) [0|1] ""  gtw
 SG_ CP_a071_inductiveErrorAmplitude m71 : 59|1@1+ (1,0) [0|1] ""  gtw
 SG_ CP_a071_inductiveDoorState m71 : 56|3@1+ (1,0) [0|7] ""  gtw
 SG_ CP_a008_stackUsed m8 : 56|7@1+ (1,0) [0|127] "%"  gtw
 SG_ CP_a065_proximityV m65 : 53|8@1+ (0.023529411764705882,0) [0|6] "V"  gtw
 SG_ CP_a008_StackAlert m8 : 52|1@1+ (1,0) [0|1] ""  gtw
 SG_ CP_a065_uhfReceiverMIA m65 : 52|1@1+ (1,0) [0|1] ""  gtw
 SG_ CP_a008_AllMemory_warnings m8 : 51|1@1+ (1,0) [0|1] ""  gtw
 SG_ CP_a008_RAMconst_Fault m8 : 50|1@1+ (1,0) [0|1] ""  gtw
 SG_ CP_a054_inletID m54 : 50|2@1+ (1,0) [0|3] ""  gtw
 SG_ CP_a008_RAMconst_Warning m8 : 49|1@1+ (1,0) [0|1] ""  gtw
 SG_ CP_a037_inletID m37 : 48|2@1+ (1,0) [0|3] ""  gtw
 SG_ CP_a038_inletID m38 : 48|2@1+ (1,0) [0|3] ""  gtw
 SG_ CP_a036_inletID m36 : 48|2@1+ (1,0) [0|3] ""  gtw
 SG_ CP_a054_CP_proximity m54 : 48|2@1+ (1,0) [0|3] ""  gtw
 SG_ CP_a000_alertDataW2 m0 : 48|16@1+ (1,0) [0|65535] ""  X
 SG_ CP_a003_canErrorWord2 m3 : 48|16@1+ (1,0) [0|65535] ""  gtw
 SG_ CP_a008_FlashWarning m8 : 48|1@1+ (1,0) [0|1] ""  gtw
 SG_ CP_a069_inductiveErrorUnderRange m69 : 47|1@1+ (1,0) [0|1] ""  gtw
 SG_ CP_a069_inductiveErrorOverRange m69 : 46|1@1+ (1,0) [0|1] ""  gtw
 SG_ CP_a010_pilotPWMdetected m10 : 45|1@1+ (1,0) [0|1] ""  gtw
 SG_ CP_a069_inductiveErrorWatchdog m69 : 45|1@1+ (1,0) [0|1] ""  gtw
 SG_ CP_a010_evseAccept m10 : 44|1@1+ (1,0) [0|1] ""  gtw
 SG_ CP_a071_doorCountsFiltered m71 : 44|12@1+ (0.025,0) [0|100] "%"  gtw
 SG_ CP_a065_pinTemperature2 m65 : 44|8@1+ (0.8039215686,-55) [-55|150] "C"  gtw
 SG_ CP_a069_inductiveErrorAmplitude m69 : 44|1@1+ (1,0) [0|1] ""  gtw
 SG_ CP_a043_idleDoorPot m43 : 44|12@1+ (0.025,0) [0|100] "%"  gtw
 SG_ CP_a036_CP_apsVoltage m36 : 40|8@1+ (0.071568627,0) [0|18.249999885] "V"  gtw
 SG_ CP_a037_CP_apsVoltage m37 : 40|8@1+ (0.071568627,0) [0|18.249999885] "V"  gtw
 SG_ CP_a066_proximity m66 : 40|2@1+ (1,0) [0|3] ""  gtw
 SG_ CP_a035_inletID m35 : 40|2@1+ (1,0) [0|3] ""  gtw
 SG_ CP_a038_CP_apsVoltage m38 : 40|8@1+ (0.071568627,0) [0|18.249999885] "V"  gtw
 SG_ CP_a054_CP_apsVoltage m54 : 40|8@1+ (0.071568627,0) [0|18.249999885] "V"  gtw
 SG_ CP_a032_inductiveSensorFiltered m32 : 36|28@1+ (0.08083879947662354,0) [0|21700000] "Hz"  gtw
 SG_ CP_a065_pinTemperature1 m65 : 36|8@1+ (0.8039215686,-55) [-55|150] "C"  gtw
 SG_ CP_a031_inductiveSensorFiltered m31 : 36|28@1+ (0.08083879947662354,0) [0|21700000] "Hz"  gtw
 SG_ CP_a065_leds_failedBlue m65 : 35|1@1+ (1,0) [0|1] ""  gtw
 SG_ CP_a038_CP_latchEnableCmd m38 : 35|1@1+ (1,0) [0|1] ""  gtw
 SG_ CP_a054_CP_latchEnableCmd m54 : 35|1@1+ (1,0) [0|1] ""  gtw
 SG_ CP_a037_CP_latchEnableCmd m37 : 35|1@1+ (1,0) [0|1] ""  gtw
 SG_ CP_a036_CP_latchEnableCmd m36 : 35|1@1+ (1,0) [0|1] ""  gtw
 SG_ CP_a054_CHG_InsertEnable m54 : 34|1@1+ (1,0) [0|1] ""  gtw
 SG_ CP_a065_leds_failedGreen m65 : 34|1@1+ (1,0) [0|1] ""  gtw
 SG_ CP_a036_CHG_InsertEnable m36 : 34|1@1+ (1,0) [0|1] ""  gtw
 SG_ CP_a037_CHG_InsertEnable m37 : 34|1@1+ (1,0) [0|1] ""  gtw
 SG_ CP_a038_CHG_InsertEnable m38 : 34|1@1+ (1,0) [0|1] ""  gtw
 SG_ CP_a065_leds_failedRed m65 : 33|1@1+ (1,0) [0|1] ""  gtw
 SG_ CP_a072_pinTemperature2 m72 : 32|8@1+ (0.8039215686,-55) [-55|150] "C"  gtw
 SG_ CP_a054_latchState m54 : 32|2@1+ (1,0) [0|3] ""  gtw
 SG_ CP_a041_inductiveSensorFiltered m41 : 32|28@1+ (0.08083879947662354,0) [0|21700000] "Hz"  gtw
 SG_ CP_a067_cc2Voltage m67 : 32|14@1+ (0.001,0) [0|13.3] "V"  gtw
 SG_ CP_a068_inductiveSensorFiltered m68 : 32|28@1+ (0.08083879947662354,0) [0|21700000] "Hz"  gtw
 SG_ CP_a008_data2 m8 : 32|16@1+ (1,0) [0|65535] ""  gtw
 SG_ CP_a036_latchState m36 : 32|2@1+ (1,0) [0|3] ""  gtw
 SG_ CP_a000_alertDataW1 m0 : 32|16@1+ (1,0) [0|65535] ""  X
 SG_ CP_a003_canErrorWord1 m3 : 32|16@1+ (1,0) [0|65535] ""  gtw
 SG_ CP_a010_pilotLow m10 : 32|12@1- (0.008,0.0) [-16.384|16.376] "V"  gtw
 SG_ CP_a037_latchState m37 : 32|2@1+ (1,0) [0|3] ""  gtw
 SG_ CP_a042_inductiveSensorFiltered m42 : 32|28@1+ (0.08083879947662354,0) [0|21700000] "Hz"  gtw
 SG_ CP_a065_latch_failedEngage m65 : 32|1@1+ (1,0) [0|1] ""  gtw
 SG_ CP_a073_pinTemperature2 m73 : 32|8@1+ (0.8039215686,-55) [-55|150] "C"  gtw
 SG_ CP_a005_cc2Voltage m5 : 32|14@1+ (0.001,0) [0|13.3] "V"  gtw
 SG_ CP_a043_doorVelocity m43 : 32|12@1- (0.5,0.0) [-1024|1023.5] "%/s"  gtw
 SG_ CP_a038_latchState m38 : 32|2@1+ (1,0) [0|3] ""  gtw
 SG_ CP_a065_latch_failedDisengage m65 : 31|1@1+ (1,0) [0|1] ""  gtw
 SG_ CP_a057_CP_proximity m57 : 30|2@1+ (1,0) [0|3] ""  gtw
 SG_ CP_a058_CP_proximity m58 : 30|2@1+ (1,0) [0|3] ""  gtw
 SG_ CP_a003_canErrorType m3 : 28|4@1+ (1,0) [0|9] ""  gtw
 SG_ CP_a068_doorPresent m68 : 28|1@1+ (1,0) [0|1] ""  gtw
 SG_ CP_a066_pilotLow m66 : 28|12@1- (0.008,0.0) [-16.384|16.376] "V"  gtw
 SG_ CP_a057_latchState m57 : 28|2@1+ (1,0) [0|3] ""  gtw
 SG_ CP_a058_latchState m58 : 28|2@1+ (1,0) [0|3] ""  gtw
 SG_ CP_a058_FC_status m58 : 24|4@1+ (1,0) [0|15] ""  gtw
 SG_ CP_a057_FC_status m57 : 24|4@1+ (1,0) [0|15] ""  gtw
 SG_ CP_a007_SRR0 m7 : 24|32@1+ (1,0) [0|4294967295] ""  gtw
 SG_ CP_a035_latchOffset m35 : 24|16@1- (0.00305185095,0.0) [-100.0030519296|100.00000007865] "%"  gtw
 SG_ CP_a072_pinTemperature1 m72 : 24|8@1+ (0.8039215686,-55) [-55|150] "C"  gtw
 SG_ CP_a070_i2cIBSR m70 : 24|8@1+ (1,0) [0|255] ""  gtw
 SG_ CP_a073_pinTemperature1 m73 : 24|8@1+ (0.8039215686,-55) [-55|150] "C"  gtw
 SG_ CP_a031_doorCountsFiltered m31 : 24|12@1+ (0.025,0) [0|100] "%"  gtw
 SG_ CP_a032_doorCountsFiltered m32 : 24|12@1+ (0.025,0) [0|100] "%"  gtw
 SG_ CP_a065_doorPotFiltered m65 : 23|8@1+ (0.39215686274509803,0) [0|100] "%"  gtw
 SG_ CP_a065_door_inductiveFailClose m65 : 22|1@1+ (1,0) [0|1] ""  gtw
 SG_ CP_a006_BMS_kwhCounter_flag m6 : 21|1@1+ (1,0) [0|1] ""  gtw
 SG_ CP_a029_CP_chargeDoorOpen m29 : 21|1@1+ (1,0) [0|1] ""  gtw
 SG_ CP_a065_door_inductiveFailOpen m65 : 21|1@1+ (1,0) [0|1] ""  gtw
 SG_ CP_a065_door_failedClose m65 : 20|1@1+ (1,0) [0|1] ""  gtw
 SG_ CP_a007_task1000HzStarved m7 : 20|1@1+ (1,0) [0|1] ""  gtw
 SG_ CP_a056_CP_proximity m56 : 20|2@1+ (1,0) [0|3] ""  gtw
 SG_ CP_a006_BMS_hvPackStatus_flag m6 : 20|1@1+ (1,0) [0|1] ""  gtw
 SG_ CP_a057_CC_pilot m57 : 19|2@1+ (1,0) [0|3] ""  gtw
 SG_ CP_a043_doorPotFiltered m43 : 19|12@1+ (0.025,0) [0|100] "%"  gtw
 SG_ CP_a010_pilotHigh m10 : 19|12@1- (0.008,0.0) [-16.384|16.376] "V"  gtw
 SG_ CP_a007_task100HzStarved m7 : 19|1@1+ (1,0) [0|1] ""  gtw
 SG_ CP_a058_CC_pilot m58 : 19|2@1+ (1,0) [0|3] ""  gtw
 SG_ CP_a029_CP_proximity m29 : 19|2@1+ (1,0) [0|3] ""  gtw
 SG_ CP_a006_BMS_chargerRequest_flag m6 : 19|1@1+ (1,0) [0|1] ""  gtw
 SG_ CP_a065_door_failedOpen m65 : 19|1@1+ (1,0) [0|1] ""  gtw
 SG_ CP_a056_CP_latchEnableCmd m56 : 19|1@1+ (1,0) [0|1] ""  gtw
 SG_ CP_a043_outOfRangeFlag m43 : 18|1@1+ (1,0) [0|1] ""  gtw
 SG_ CP_a035_stateLeverMovedFrom m35 : 18|2@1+ (1,0) [0|3] ""  gtw
 SG_ CP_a006_BMS_chargeStatus_flag m6 : 18|1@1+ (1,0) [0|1] ""  gtw
 SG_ CP_a047_sensors m47 : 18|1@1+ (1,0) [0|1] ""  gtw
 SG_ CP_a065_door_failedCinch m65 : 18|1@1+ (1,0) [0|1] ""  gtw
 SG_ CP_a056_CHG_InsertEnable m56 : 18|1@1+ (1,0) [0|1] ""  gtw
 SG_ CP_a014_CHG_FCStatus_flag m14 : 18|1@1+ (1,0) [0|1] ""  gtw
 SG_ CP_a007_task10HzStarved m7 : 18|1@1+ (1,0) [0|1] ""  gtw
 SG_ CP_a013_GTW_carConfig_flag m13 : 18|1@1+ (1,0) [0|1] ""  gtw
 SG_ CP_a010_voltageValid m10 : 18|1@1+ (1,0) [0|1] ""  gtw
 SG_ CP_a046_CC_chgStatus_flag m46 : 18|1@1+ (1,0) [0|1] ""  gtw
 SG_ CP_a013_GTW_vin_flag m13 : 17|1@1+ (1,0) [0|1] ""  gtw
 SG_ CP_a047_vehiclePowerState m47 : 17|1@1+ (1,0) [0|1] ""  gtw
 SG_ CP_a045_VCSEC_requests m45 : 17|1@1+ (1,0) [0|1] ""  gtw
 SG_ CP_a007_task1HzStarved m7 : 17|1@1+ (1,0) [0|1] ""  gtw
 SG_ CP_a028_hardlineEnable m28 : 17|1@1+ (1,0) [0|1] ""  gtw
 SG_ CP_a006_BMS_FC_request_flag m6 : 17|1@1+ (1,0) [0|1] ""  gtw
 SG_ CP_a043_wrongDirectionFlag m43 : 17|1@1+ (1,0) [0|1] ""  gtw
 SG_ CP_a010_widthValid m10 : 17|1@1+ (1,0) [0|1] ""  gtw
 SG_ CP_a014_CHG_lineStatus_flag m14 : 17|1@1+ (1,0) [0|1] ""  gtw
 SG_ CP_a065_proxOut_failedDisable m65 : 17|1@1+ (1,0) [0|1] ""  gtw
 SG_ CP_a048_UI_status_flag m48 : 17|1@1+ (1,0) [0|1] ""  gtw
 SG_ CP_a046_FC_limits_flag m46 : 17|1@1+ (1,0) [0|1] ""  gtw
 SG_ CP_a063_FC_status m63 : 16|4@1+ (1,0) [0|15] ""  gtw
 SG_ CP_a035_latchState m35 : 16|2@1+ (1,0) [0|3] ""  gtw
 SG_ CP_a064_GTW_superchargingAccess m64 : 16|2@1+ (1,0) [0|2] ""  gtw
 SG_ CP_a072_VCFRONT_tempAmbientFilte m72 : 16|8@1+ (0.5,-40) [-40|80] "degC"  gtw
 SG_ CP_a000_alertDataW0 m0 : 16|16@1+ (1,0) [0|65535] ""  X
 SG_ CP_a017_5V_VoltageOV m17 : 16|8@1+ (0.02352539,0) [0|5.99897] "V"  gtw
 SG_ CP_a068_doorCountsFiltered m68 : 16|12@1+ (0.025,0) [0|100] "%"  gtw
 SG_ CP_a014_CHG_status_flag m14 : 16|1@1+ (1,0) [0|1] ""  gtw
 SG_ CP_a003_canAddress m3 : 16|12@1+ (1,0) [0|4095] ""  gtw
 SG_ CP_a029_CP_pilot m29 : 16|3@1+ (1,0) [0|7] ""  gtw
 SG_ CP_a032_apsVoltage m32 : 16|8@1+ (0.071568627,0) [0|18.249999885] "V"  gtw
 SG_ CP_a069_inductiveSensor_raw m69 : 16|28@1+ (1,0) [0|268435455] ""  gtw
 SG_ CP_a052_fcType m52 : 16|3@1+ (1,0) [0|7] ""  gtw
 SG_ CP_a054_latchCountsFiltered m54 : 16|16@1+ (0.00152590219,0) [0|100.00000002165] "%"  gtw
 SG_ CP_a006_BMS_FC_limits_flag m6 : 16|1@1+ (1,0) [0|1] ""  gtw
 SG_ CP_a010_periodValid m10 : 16|1@1+ (1,0) [0|1] ""  gtw
 SG_ CP_a073_VCFRONT_tempAmbientFilte m73 : 16|8@1+ (0.5,-40) [-40|80] "degC"  gtw
 SG_ CP_a060_PCS_chgStatus_flag m60 : 16|1@1+ (1,0) [0|1] ""  gtw
 SG_ CP_a062_FC_status m62 : 16|4@1+ (1,0) [0|15] ""  gtw
 SG_ CP_a067_cc1Voltage m67 : 16|14@1+ (0.001,0) [0|13.3] "V"  gtw
 SG_ CP_a031_apsVoltage m31 : 16|8@1+ (0.071568627,0) [0|18.249999885] "V"  gtw
 SG_ CP_a050_inletID m50 : 16|2@1+ (1,0) [0|3] ""  gtw
 SG_ CP_a040_CP_doorCountsFiltered m40 : 16|16@1+ (0.00152590219,0) [0|100.00000002165] "%"  gtw
 SG_ CP_a007_sentOnReset m7 : 16|1@1+ (1,0) [0|1] ""  gtw
 SG_ CP_a046_FC_status_flag m46 : 16|1@1+ (1,0) [0|1] ""  gtw
 SG_ CP_a004_proximityV m4 : 16|16@1+ (0.0001,0) [0|6] "V"  gtw
 SG_ CP_a011_eepromErrorType m11 : 16|16@1+ (1,0) [0|65535] ""  gtw
 SG_ CP_a030_busOffData m30 : 16|1@1+ (1,0) [0|1] ""  gtw
 SG_ CP_a049_proximity m49 : 16|1@1+ (1,0) [0|1] ""  gtw
 SG_ CP_a071_inductiveSensor_raw m71 : 16|28@1+ (1,0) [0|268435455] ""  gtw
 SG_ CP_a038_latchCountsFiltered m38 : 16|16@1+ (0.00152590219,0) [0|100.00000002165] "%"  gtw
 SG_ CP_a019_3_3V_VoltageOV m19 : 16|8@1+ (0.02352539,0) [0|5.99897] "V"  gtw
 SG_ CP_a015_apsVoltageOV m15 : 16|8@1+ (0.071285156,0) [0|18.17771] "V"  gtw
 SG_ CP_a070_i2cIBCR m70 : 16|8@1+ (1,0) [0|255] ""  gtw
 SG_ CP_a065_proxOut_failedEnable m65 : 16|1@1+ (1,0) [0|1] ""  gtw
 SG_ CP_a056_latchState m56 : 16|2@1+ (1,0) [0|3] ""  gtw
 SG_ CP_a045_VCSEC_authentication m45 : 16|1@1+ (1,0) [0|1] ""  gtw
 SG_ CP_a047_okToUseHighPower m47 : 16|1@1+ (1,0) [0|1] ""  gtw
 SG_ CP_a041_doorCounts m41 : 16|16@1+ (0.002,0) [0|100] "%"  gtw
 SG_ CP_a051_doorCountsFiltered m51 : 16|12@1+ (0.025,0) [0|100] "%"  gtw
 SG_ CP_a018_5V_VoltageUV m18 : 16|8@1+ (0.02352539,0) [0|5.99897] "V"  gtw
 SG_ CP_a016_apsVoltageUV m16 : 16|8@1+ (0.071285156,0) [0|18.17771] "V"  gtw
 SG_ CP_a008_data1 m8 : 16|16@1+ (1,0) [0|65535] ""  gtw
 SG_ CP_a021_0V_VoltageOV m21 : 16|8@1+ (0.012890625,0) [0|3.28711] "V"  gtw
 SG_ CP_a028_canEnable m28 : 16|1@1+ (1,0) [0|1] ""  gtw
 SG_ CP_a058_CP_pilot m58 : 16|3@1+ (1,0) [0|7] ""  gtw
 SG_ CP_a037_latchCountsFiltered m37 : 16|16@1+ (0.00152590219,0) [0|100.00000002165] "%"  gtw
 SG_ CP_a048_UI_chargeRequest_flag m48 : 16|1@1+ (1,0) [0|1] ""  gtw
 SG_ CP_a057_CP_pilot m57 : 16|3@1+ (1,0) [0|7] ""  gtw
 SG_ CP_a042_doorCounts m42 : 16|16@1+ (0.002,0) [0|100] "%"  gtw
 SG_ CP_a066_pilotHigh m66 : 16|12@1- (0.008,0.0) [-16.384|16.376] "V"  gtw
 SG_ CP_a022_0V_VoltageUV m22 : 16|8@1+ (0.012890625,0) [0|3.28711] "V"  gtw
 SG_ CP_a020_3_3V_VoltageUV m20 : 16|8@1+ (0.02352539,0) [0|5.99897] "V"  gtw
 SG_ CP_a013_GTW_bodyStatus_flag m13 : 16|1@1+ (1,0) [0|1] ""  gtw
 SG_ CP_a036_latchCountsFiltered m36 : 16|16@1+ (0.00152590219,0) [0|100.00000002165] "%"  gtw
 SG_ CP_a005_cc1Voltage m5 : 16|14@1+ (0.001,0) [0|13.3] "V"  gtw
 SG_ CP_a043_driftFlag m43 : 16|1@1+ (1,0) [0|1] ""  gtw
 SG_ CP_a044_HVP_cpControl_flag m44 : 16|1@1+ (1,0) [0|1] ""  gtw
 SG_ CP_alertType : 15|1@1+ (1,0) [0|1] ""  gtw
 SG_ CP_alertID M : 0|9@1+ (1,0) [0|256] ""  dbg

BO_ 294 DI_motorControl: 8 VEH
 SG_ DI_limitObstacleDetection : 62|1@1+ (1,0) [0|1] ""  gtw
 SG_ DI_limitClutch : 61|1@1+ (1,0) [0|1] ""  gtw
 SG_ DI_limitStatorFrequency : 60|1@1+ (1,0) [0|1] ""  gtw
 SG_ DI_limitOilPumpFluidTemp : 59|1@1+ (1,0) [0|1] ""  gtw
 SG_ DI_limitShockTorque : 57|1@1+ (1,0) [0|1] ""  gtw
 SG_ DI_limitIGBTJunctTemp : 56|1@1+ (1,0) [0|1] ""  gtw
 SG_ DI_limitGracefulPowerOff : 55|1@1+ (1,0) [0|1] ""  gtw
 SG_ DI_limitDiff : 54|1@1+ (1,0) [0|1] ""  gtw
 SG_ DI_limitVehicleSpeed : 53|1@1+ (1,0) [0|1] ""  gtw
 SG_ DI_limitMotorSpeed : 52|1@1+ (1,0) [0|1] ""  gtw
 SG_ DI_limitVBatHigh : 51|1@1+ (1,0) [0|1] ""  gtw
 SG_ DI_limitVBatLow : 50|1@1+ (1,0) [0|1] ""  gtw
 SG_ DI_limitDcCapTemp : 49|1@1+ (1,0) [0|1] ""  gtw
 SG_ DI_limitIBat : 48|1@1+ (1,0) [0|1] ""  gtw
 SG_ DI_limitBaseSpeed : 47|1@1+ (1,0) [0|1] ""  X
 SG_ DI_limitShift : 46|1@1+ (1,0) [0|1] ""  gtw
 SG_ DI_limitTCRegen : 45|1@1+ (1,0) [0|1] ""  gtw
 SG_ DI_limitTCDrive : 44|1@1+ (1,0) [0|1] ""  gtw
 SG_ DI_limitRegenTorque : 43|1@1+ (1,0) [0|1] ""  gtw
 SG_ DI_limitDriveTorque : 42|1@1+ (1,0) [0|1] ""  gtw
 SG_ DI_limitMotorVoltage : 41|1@1+ (1,0) [0|1] ""  gtw
 SG_ DI_limitMotorCurrent : 40|1@1+ (1,0) [0|1] ""  gtw
 SG_ DI_limitRegenPower : 39|1@1+ (1,0) [0|1] ""  gtw
 SG_ DI_limitDischargePower : 38|1@1+ (1,0) [0|1] ""  gtw
 SG_ DI_limitDeltaFluidTemp : 37|1@1+ (1,0) [0|1] ""  X
 SG_ DI_limitLimpMode : 36|1@1+ (1,0) [0|1] ""  gtw
 SG_ DI_limitPoleTemp : 35|1@1+ (1,0) [0|1] ""  gtw
 SG_ DI_limitStatorTemp : 34|1@1+ (1,0) [0|1] ""  gtw
 SG_ DI_limitInverterTemp : 33|1@1+ (1,0) [0|1] ""  gtw
 SG_ DI_limitPCBTemp : 32|1@1+ (1,0) [0|1] ""  gtw
 SG_ DI_motorCurrent : 16|11@1+ (1,0) [0|2047] "A"  gtw
 SG_ DI_vBat : 0|10@1+ (0.5,0) [0|500] "V"  gtw

BO_ 1547 VCSEC_udsResponse: 8 VEH
 SG_ VCSEC_udsResponseData : 7|64@0+ (1,0) [0|18446744073709551615] ""  gtw

BO_ 1250 VCLEFT_seatStatus: 8 VEH
 SG_ VCLEFT_lumbarDevMaxPumpPressB m4 : 55|1@1+ (1,0) [0|1] ""  gtw
 SG_ VCLEFT_lumbarDevMaxPumpPressA m4 : 54|1@1+ (1,0) [0|1] ""  gtw
 SG_ VCLEFT_lumbarGeneralErr m4 : 53|1@1+ (1,0) [0|1] ""  gtw
 SG_ VCLEFT_lumbarMinPErr m4 : 52|1@1+ (1,0) [0|1] ""  gtw
 SG_ VCLEFT_frontSeatTrackLog m0 : 52|1@1+ (1,0) [0|1] ""  gtw
 SG_ VCLEFT_frontSeatTiltLog m3 : 52|1@1+ (1,0) [0|1] ""  gtw
 SG_ VCLEFT_frontSeatBackLog m1 : 52|1@1+ (1,0) [0|1] ""  gtw
 SG_ VCLEFT_frontSeatLiftLog m2 : 52|1@1+ (1,0) [0|1] ""  gtw
 SG_ VCLEFT_frontSeatBackCalibrated m1 : 51|1@1+ (1,0) [0|1] ""  gtw
 SG_ VCLEFT_frontSeatTiltCalibrated m3 : 51|1@1+ (1,0) [0|1] ""  gtw
 SG_ VCLEFT_frontSeatTrackCalibrated m0 : 51|1@1+ (1,0) [0|1] ""  gtw
 SG_ VCLEFT_lumbarMaxOperatingPErr m4 : 51|1@1+ (1,0) [0|1] ""  gtw
 SG_ VCLEFT_frontSeatLiftCalibrated m2 : 51|1@1+ (1,0) [0|1] ""  gtw
 SG_ VCLEFT_lumbarOvercurrentErr m4 : 50|1@1+ (1,0) [0|1] ""  gtw
 SG_ VCLEFT_lumbarMaxPErr m4 : 49|1@1+ (1,0) [0|1] ""  gtw
 SG_ VCLEFT_frontSeatTiltState m3 : 48|3@1+ (1,0) [0|5] ""  gtw
 SG_ VCLEFT_lumbarActiveTooLongErr m4 : 48|1@1+ (1,0) [0|1] ""  gtw
 SG_ VCLEFT_frontSeatTrackState m0 : 48|3@1+ (1,0) [0|5] ""  gtw
 SG_ VCLEFT_frontSeatBackState m1 : 48|3@1+ (1,0) [0|5] ""  gtw
 SG_ VCLEFT_frontSeatLiftState m2 : 48|3@1+ (1,0) [0|5] ""  gtw
 SG_ VCLEFT_frontSeatTiltPosReal m5 : 40|12@1- (0.1,0) [-204.8|204.7] "deg"  gtw
 SG_ VCLEFT_frontSeatTrackDuty m0 : 36|12@1- (0.1,0) [-204.8|204.7] "%"  gtw
 SG_ VCLEFT_frontSeatTiltDuty m3 : 36|12@1- (0.1,0) [-204.8|204.7] "%"  gtw
 SG_ VCLEFT_frontSeatBackDuty m1 : 36|12@1- (0.1,0) [-204.8|204.7] "%"  gtw
 SG_ VCLEFT_frontSeatLiftDuty m2 : 36|12@1- (0.1,0) [-204.8|204.7] "%"  gtw
 SG_ VCLEFT_lumbarBPressureHpa m4 : 32|16@1+ (1,0) [0|65535] ""  gtw
 SG_ VCLEFT_frontSeatLiftPosReal m5 : 28|12@1- (1,0) [-2048|2047] "mm"  gtw
 SG_ VCLEFT_frontSeatBackCurrent m1 : 24|12@1- (0.01,0) [-20.48|20.47] "A"  gtw
 SG_ VCLEFT_frontSeatTrackCurrent m0 : 24|12@1- (0.01,0) [-20.48|20.47] "A"  gtw
 SG_ VCLEFT_frontSeatTiltCurrent m3 : 24|12@1- (0.01,0) [-20.48|20.47] "A"  gtw
 SG_ VCLEFT_frontSeatLiftCurrent m2 : 24|12@1- (0.01,0) [-20.48|20.47] "A"  gtw
 SG_ VCLEFT_lumbarAPressureHpa m4 : 16|16@1+ (1,0) [0|65535] ""  gtw
 SG_ VCLEFT_frontSeatBackPosReal m5 : 16|12@1- (0.1,0) [-204.8|204.7] "deg"  gtw
 SG_ VCLEFT_frontSeatLiftPos m2 : 8|16@1- (1,0) [-32768|32767] ""  gtw
 SG_ VCLEFT_lumbarBState m4 : 8|3@1+ (1,0) [0|5] ""  gtw
 SG_ VCLEFT_frontSeatTrackPos m0 : 8|16@1- (1,0) [-32768|32767] ""  gtw
 SG_ VCLEFT_frontSeatTiltPos m3 : 8|16@1- (1,0) [-32768|32767] ""  gtw
 SG_ VCLEFT_frontSeatBackPos m1 : 8|16@1- (1,0) [-32768|32767] ""  gtw
 SG_ VCLEFT_frontSeatTrackPosReal m5 : 3|12@1- (1,0) [-2048|2047] "mm"  gtw
 SG_ VCLEFT_lumbarAState m4 : 3|3@1+ (1,0) [0|5] ""  gtw
 SG_ VCLEFT_seatStatusIndex M : 0|3@1+ (1,0) [0|5] ""  X

BO_ 741 DIS_power: 7 VEH
 SG_ DIS_heatPowerActual : 48|8@1+ (0.08,0) [0|20] "kW"  di
 SG_ DIS_drivePowerMax : 32|9@1+ (1,0) [0|400] "kW"  di
 SG_ DIS_elecPower : 16|11@1- (0.5,0.0) [-500|500] "kW"  bms
 SG_ DIS_dissipation : 8|8@1+ (125,0) [0|31000] "W"  X
 SG_ DIS_aps12V : 0|8@1+ (0.1,0) [0|25.5] "V"  X

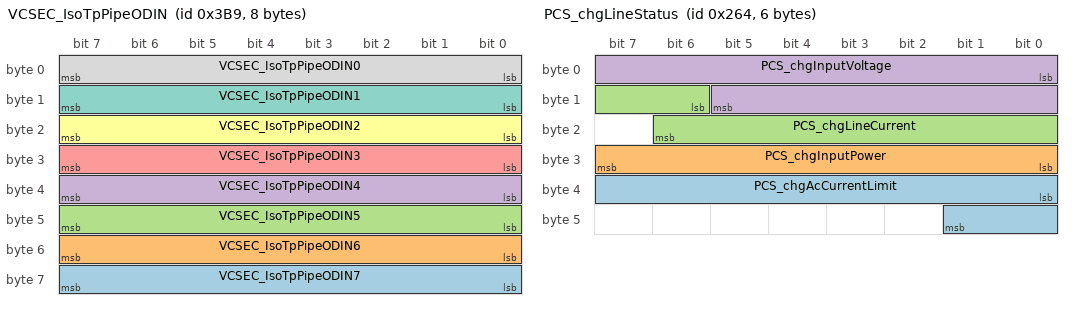
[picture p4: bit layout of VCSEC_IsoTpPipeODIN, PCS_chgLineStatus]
BO_ 953 VCSEC_IsoTpPipeODIN: 8 VEH
 SG_ VCSEC_IsoTpPipeODIN7 : 56|8@1+ (1,0) [0|255] ""  gtw
 SG_ VCSEC_IsoTpPipeODIN6 : 48|8@1+ (1,0) [0|255] ""  gtw
 SG_ VCSEC_IsoTpPipeODIN5 : 40|8@1+ (1,0) [0|255] ""  gtw
 SG_ VCSEC_IsoTpPipeODIN4 : 32|8@1+ (1,0) [0|255] ""  gtw
 SG_ VCSEC_IsoTpPipeODIN3 : 24|8@1+ (1,0) [0|255] ""  gtw
 SG_ VCSEC_IsoTpPipeODIN2 : 16|8@1+ (1,0) [0|255] ""  gtw
 SG_ VCSEC_IsoTpPipeODIN1 : 8|8@1+ (1,0) [0|255] ""  gtw
 SG_ VCSEC_IsoTpPipeODIN0 : 0|8@1+ (1,0) [0|255] ""  gtw

BO_ 612 PCS_chgLineStatus: 6 VEH
 SG_ PCS_chgAcCurrentLimit : 32|10@1+ (0.1,0) [0|102.3] "A"  gtw
 SG_ PCS_chgInputPower : 24|8@1+ (0.1,0) [0|20] "kW"  dbg
 SG_ PCS_chgLineCurrent : 14|9@1+ (0.1,0) [0|50] "A"  dbg
 SG_ PCS_chgInputVoltage : 0|14@1+ (0.033,0) [0|540.639] "V"  gtw

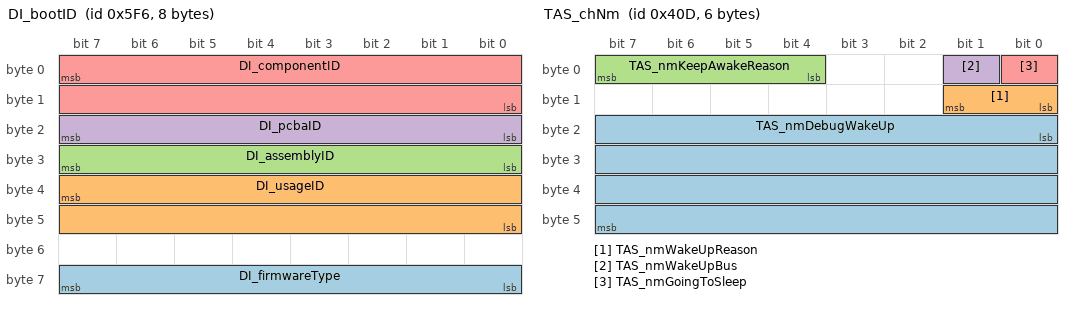
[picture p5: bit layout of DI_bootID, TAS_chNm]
BO_ 1526 DI_bootID: 8 VEH
 SG_ DI_firmwareType : 63|8@0+ (1,0) [0|255] ""  gtwu
 SG_ DI_usageID : 39|16@0+ (1,0) [0|65535] ""  gtwu
 SG_ DI_assemblyID : 31|8@0+ (1,0) [0|255] ""  gtwu
 SG_ DI_pcbaID : 23|8@0+ (1,0) [0|255] ""  gtwu
 SG_ DI_componentID : 7|16@0+ (1,0) [0|65535] ""  gtwu

BO_ 1037 TAS_chNm: 6 VEH
 SG_ TAS_nmDebugWakeUp : 16|32@1+ (1,0) [0|4294967295] ""  X
 SG_ TAS_nmWakeUpReason : 8|2@1+ (1,0) [0|3] ""  X
 SG_ TAS_nmKeepAwakeReason : 4|4@1+ (1,0) [0|15] ""  vcfront
 SG_ TAS_nmWakeUpBus : 1|1@1+ (1,0) [0|1] ""  X
 SG_ TAS_nmGoingToSleep : 0|1@1+ (1,0) [0|1] ""  X

BO_ 968 EPBL_alertMatrix: 8 VEH
 SG_ EPBL_a060_engineeringBuild m0 : 63|1@1+ (1,0) [0|1] ""  gtw
 SG_ EPBL_a300_leftRightConfusion m4 : 63|1@1+ (1,0) [0|1] ""  gtw
 SG_ EPBL_a120_DI_DRIVE_MIA m1 : 63|1@1+ (1,0) [0|1] ""  gtw
 SG_ EPBL_a180_dynamicActive m2 : 63|1@1+ (1,0) [0|1] ""  gtw
 SG_ EPBL_a179_epbProblem m2 : 62|1@1+ (1,0) [0|1] ""  gtw
 SG_ EPBL_a059_inputResistanceHigh m0 : 62|1@1+ (1,0) [0|1] ""  gtw
 SG_ EPBL_a119_SCCM_MIA m1 : 62|1@1+ (1,0) [0|1] ""  gtw
 SG_ EPBL_a178_caliperStateUnknown m2 : 61|1@1+ (1,0) [0|1] ""  gtw
 SG_ EPBL_a118_VCFRONT_MIA m1 : 61|1@1+ (1,0) [0|1] ""  gtw
 SG_ EPBL_a117_VCLEFT_MIA m1 : 60|1@1+ (1,0) [0|1] ""  gtw
 SG_ EPBL_a177_csmApplyRetry m2 : 60|1@1+ (1,0) [0|1] ""  gtw
 SG_ EPBL_a176_csmApplyFailed m2 : 59|1@1+ (1,0) [0|1] ""  gtw
 SG_ EPBL_a116_VCRIGHT_MIA m1 : 59|1@1+ (1,0) [0|1] ""  gtw
 SG_ EPBL_a175_csmReleaseRetry m2 : 58|1@1+ (1,0) [0|1] ""  gtw
 SG_ EPBL_a115_VCSEC_MIA m1 : 58|1@1+ (1,0) [0|1] ""  gtw
 SG_ EPBL_a114_ESP_MIA m1 : 57|1@1+ (1,0) [0|1] ""  gtw
 SG_ EPBL_a174_csmReleaseFailed m2 : 57|1@1+ (1,0) [0|1] ""  gtw
 SG_ EPBL_a173_hiCurrentMissing m2 : 56|1@1+ (1,0) [0|1] ""  gtw
 SG_ EPBL_a113_UI_MIA m1 : 56|1@1+ (1,0) [0|1] ""  gtw
 SG_ EPBL_a112_EPBL_MIA m1 : 55|1@1+ (1,0) [0|1] ""  gtw
 SG_ EPBL_a172_SPI_MIA m2 : 55|1@1+ (1,0) [0|1] ""  gtw
 SG_ EPBL_a171_12vUv m2 : 54|1@1+ (1,0) [0|1] ""  gtw
 SG_ EPBL_a111_EPBR_MIA m1 : 54|1@1+ (1,0) [0|1] ""  gtw
 SG_ EPBL_a170_12vOv m2 : 53|1@1+ (1,0) [0|1] ""  gtw
 SG_ EPBL_a110_GTW_MIA m1 : 53|1@1+ (1,0) [0|1] ""  gtw
 SG_ EPBL_a109_RCM_MIA m1 : 52|1@1+ (1,0) [0|1] ""  gtw
 SG_ EPBL_a108_DIS_MIA m1 : 51|1@1+ (1,0) [0|1] ""  gtw
 SG_ EPBL_a107_BMS_MIA m1 : 50|1@1+ (1,0) [0|1] ""  gtw
 SG_ EPBL_a046_Task1000msError m0 : 49|1@1+ (1,0) [0|1] ""  gtw
 SG_ EPBL_a106_PCS_MIA m1 : 49|1@1+ (1,0) [0|1] ""  gtw
 SG_ EPBL_a045_Task100msError m0 : 48|1@1+ (1,0) [0|1] ""  gtw
 SG_ EPBL_a105_TAS_MIA m1 : 48|1@1+ (1,0) [0|1] ""  gtw
 SG_ EPBL_a104_DAS_MIA m1 : 47|1@1+ (1,0) [0|1] ""  gtw
 SG_ EPBL_a044_Task10msError m0 : 47|1@1+ (1,0) [0|1] ""  gtw
 SG_ EPBL_a103_CP_MIA m1 : 46|1@1+ (1,0) [0|1] ""  gtw
 SG_ EPBL_a043_Task1msError m0 : 46|1@1+ (1,0) [0|1] ""  gtw
 SG_ EPBL_a042_HighStackUsage m0 : 45|1@1+ (1,0) [0|1] ""  gtw
 SG_ EPBL_a102_PTC_MIA m1 : 45|1@1+ (1,0) [0|1] ""  gtw
 SG_ EPBL_a041_HighCPULoad m0 : 44|1@1+ (1,0) [0|1] ""  gtw
 SG_ EPBL_a101_PM_MIA m1 : 44|1@1+ (1,0) [0|1] ""  gtw
 SG_ EPBL_a100_CANbus_MIA m1 : 43|1@1+ (1,0) [0|1] ""  gtw
 SG_ EPBL_a099_PARK_MIA m1 : 42|1@1+ (1,0) [0|1] ""  gtw
 SG_ EPBL_a098_DI_THERMAL_MIA m1 : 41|1@1+ (1,0) [0|1] ""  gtw
 SG_ EPBL_a217_SPI_MIA_debugData2 m3 : 40|1@1+ (1,0) [0|1] ""  gtw
 SG_ EPBL_a097_CMP_MIA m1 : 40|1@1+ (1,0) [0|1] ""  gtw
 SG_ EPBL_a216_SPI_MIA_debugData1 m3 : 39|1@1+ (1,0) [0|1] ""  gtw
 SG_ EPBL_a031_UDSActive m0 : 34|1@1+ (1,0) [0|1] ""  gtw
 SG_ EPBL_a030_ECULogUploadRequest m0 : 33|1@1+ (1,0) [0|1] ""  gtw
 SG_ EPBL_a022_TaskInitError m0 : 25|1@1+ (1,0) [0|1] ""  gtw
 SG_ EPBL_a201_hwBrakeTypeMismatch m3 : 24|1@1+ (1,0) [0|1] ""  gtw
 SG_ EPBL_a021_TaskSchedulerError m0 : 24|1@1+ (1,0) [0|1] ""  gtw
 SG_ EPBL_a141_invalidState m2 : 24|1@1+ (1,0) [0|1] ""  gtw
 SG_ EPBL_a200_PmUnparkNotAllowed m3 : 23|1@1+ (1,0) [0|1] ""  gtw
 SG_ EPBL_a138_NVMWriteTime m2 : 21|1@1+ (1,0) [0|1] ""  gtw
 SG_ EPBL_a137_PvUv m2 : 20|1@1+ (1,0) [0|1] ""  gtw
 SG_ EPBL_a136_PvOv m2 : 19|1@1+ (1,0) [0|1] ""  gtw
 SG_ EPBL_a015_NVMMAlert m0 : 18|1@1+ (1,0) [0|1] ""  gtw
 SG_ EPBL_a195_parkForDriverIsLeaving m3 : 18|1@1+ (1,0) [0|1] ""  gtw
 SG_ EPBL_a135_NvUv m2 : 18|1@1+ (1,0) [0|1] ""  gtw
 SG_ EPBL_a134_NvOv m2 : 17|1@1+ (1,0) [0|1] ""  gtw
 SG_ EPBL_a013_AlertManagerFault m0 : 16|1@1+ (1,0) [0|1] ""  gtw
 SG_ EPBL_a012_CPUReset m0 : 15|1@1+ (1,0) [0|1] ""  gtw
 SG_ EPBL_a251_currentVarianceHigh m4 : 14|1@1+ (1,0) [0|1] ""  gtw
 SG_ EPBL_a191_csmReleaseDegraded m3 : 14|1@1+ (1,0) [0|1] ""  gtw
 SG_ EPBL_a190_csmApplyDegraded m3 : 13|1@1+ (1,0) [0|1] ""  gtw
 SG_ EPBL_a010_ExtSupplyVoltError m0 : 13|1@1+ (1,0) [0|1] ""  gtw
 SG_ EPBL_a250_WinchModeCanceled m4 : 13|1@1+ (1,0) [0|1] ""  gtw
 SG_ EPBL_a249_idleFaultRelease m4 : 12|1@1+ (1,0) [0|1] ""  gtw
 SG_ EPBL_a189_epbDynamicParkCanceled m3 : 12|1@1+ (1,0) [0|1] ""  gtw
 SG_ EPBL_a248_csmDynamicApplyFailed m4 : 11|1@1+ (1,0) [0|1] ""  gtw
 SG_ EPBL_a188_epbDynamic m3 : 11|1@1+ (1,0) [0|1] ""  gtw
 SG_ EPBL_a128_MotorPVoltHigh m2 : 11|1@1+ (1,0) [0|1] ""  gtw
 SG_ EPBL_a187_cdpDynamic m3 : 10|1@1+ (1,0) [0|1] ""  gtw
 SG_ EPBL_a127_MotorNVoltHigh m2 : 10|1@1+ (1,0) [0|1] ""  gtw
 SG_ EPBL_a247_csmDynamicApplyRetry m4 : 10|1@1+ (1,0) [0|1] ""  gtw
 SG_ EPBL_a186_externalParkAbort m3 : 9|1@1+ (1,0) [0|1] ""  gtw
 SG_ EPBL_a126_MotorNVoltLow m2 : 9|1@1+ (1,0) [0|1] ""  gtw
 SG_ EPBL_a246_idleFaultApply m4 : 9|1@1+ (1,0) [0|1] ""  gtw
 SG_ EPBL_a125_IdleVMismatch m2 : 8|1@1+ (1,0) [0|1] ""  gtw
 SG_ EPBL_a185_summonAborted m3 : 8|1@1+ (1,0) [0|1] ""  gtw
 SG_ EPBL_a245_serviceModeActive m4 : 8|1@1+ (1,0) [0|1] ""  gtw
 SG_ EPBL_a184_dynamicParkAbort m3 : 7|1@1+ (1,0) [0|1] ""  gtw
 SG_ EPBL_a064_busSleepReqTimeout m1 : 7|1@1+ (1,0) [0|1] ""  gtw
 SG_ EPBL_a124_calOutOfBounds m2 : 7|1@1+ (1,0) [0|1] ""  gtw
 SG_ EPBL_a244_WinchModeActive m4 : 7|1@1+ (1,0) [0|1] ""  gtw
 SG_ EPBL_a123_Uc m2 : 6|1@1+ (1,0) [0|1] ""  gtw
 SG_ EPBL_a183_cdpNotAvailable m3 : 6|1@1+ (1,0) [0|1] ""  gtw
 SG_ EPBL_a003_SWAssertion m0 : 6|1@1+ (1,0) [0|1] ""  gtw
 SG_ EPBL_a063_SwitchFault m1 : 6|1@1+ (1,0) [0|1] ""  gtw
 SG_ EPBL_a243_bdwUnavailable m4 : 6|1@1+ (1,0) [0|1] ""  gtw
 SG_ EPBL_a002_PowerLossReset m0 : 5|1@1+ (1,0) [0|1] ""  gtw
 SG_ EPBL_a242_hvOutputLocked m4 : 5|1@1+ (1,0) [0|1] ""  gtw
 SG_ EPBL_a062_XCPWasConnected m1 : 5|1@1+ (1,0) [0|1] ""  gtw
 SG_ EPBL_a122_Oc m2 : 5|1@1+ (1,0) [0|1] ""  gtw
 SG_ EPBL_a182_OneEPBAppliedUnsecEnv m3 : 5|1@1+ (1,0) [0|1] ""  gtw
 SG_ EPBL_a061_XCPConnected m1 : 4|1@1+ (1,0) [0|1] ""  gtw
 SG_ EPBL_a001_WatchdogReset m0 : 4|1@1+ (1,0) [0|1] ""  gtw
 SG_ EPBL_a121_nDriveFault m2 : 4|1@1+ (1,0) [0|1] ""  gtw
 SG_ EPBL_a181_TooSteepGradeToPark m3 : 4|1@1+ (1,0) [0|1] ""  gtw
 SG_ EPBL_a241_diOutputLocked m4 : 4|1@1+ (1,0) [0|1] ""  gtw
 SG_ EPBL_matrixIndex M : 0|4@1+ (1,0) [0|15] ""  gtw

BO_ 964 PCS_info: 8 VEH
 SG_ PCS_serialNumChar14 m30 : 56|8@1+ (1,0) [0|255] ""  gtw
 SG_ PCS_partNumChar07 m25 : 56|8@1+ (1,0) [0|255] ""  gtw
 SG_ PCS_serialNumChar07 m29 : 56|8@1+ (1,0) [0|255] ""  gtw
 SG_ PCS_partNumChar14 m26 : 56|8@1+ (1,0) [0|255] ""  gtw
 SG_ PCS_serialNumChar13 m30 : 48|8@1+ (1,0) [0|255] ""  gtw
 SG_ PCS_serialNumChar06 m29 : 48|8@1+ (1,0) [0|255] ""  gtw
 SG_ PCS_partNumChar20 m27 : 48|8@1+ (1,0) [0|255] ""  gtw
 SG_ PCS_subUsageId m11 : 48|16@1+ (1,0) [0|65535] ""  gtw
 SG_ PCS_partNumChar06 m25 : 48|8@1+ (1,0) [0|255] ""  gtw
 SG_ PCS_componentId m10 : 48|16@1+ (1,0) [0|65535] ""  gtw
 SG_ PCS_partNumChar13 m26 : 48|8@1+ (1,0) [0|255] ""  gtw
 SG_ PCS_partNumChar19 m27 : 40|8@1+ (1,0) [0|255] ""  gtw
 SG_ PCS_partNumChar05 m25 : 40|8@1+ (1,0) [0|255] ""  gtw
 SG_ PCS_serialNumChar12 m30 : 40|8@1+ (1,0) [0|255] ""  gtw
 SG_ PCS_partNumChar12 m26 : 40|8@1+ (1,0) [0|255] ""  gtw
 SG_ PCS_serialNumChar05 m29 : 40|8@1+ (1,0) [0|255] ""  gtw
 SG_ PCS_bootCrc m20 : 32|32@1+ (1,0) [0|4294967295] ""  gtw
 SG_ PCS_cpu2AppCrc m16 : 32|32@1+ (1,0) [0|4294967295] ""  dbg
 SG_ PCS_partNumChar04 m25 : 32|8@1+ (1,0) [0|255] ""  gtw
 SG_ PCS_usageId m11 : 32|16@1+ (1,0) [0|65535] ""  gtw
 SG_ PCS_hardwareId m10 : 32|16@1+ (1,0) [0|65535] ""  X
 SG_ PCS_serialNumChar11 m30 : 32|8@1+ (1,0) [0|255] ""  gtw
 SG_ PCS_partNumChar11 m26 : 32|8@1+ (1,0) [0|255] ""  gtw
 SG_ PCS_serialNumChar04 m29 : 32|8@1+ (1,0) [0|255] ""  gtw
 SG_ PCS_partNumChar18 m27 : 32|8@1+ (1,0) [0|255] ""  gtw
 SG_ PCS_appCrc m13 : 32|32@1+ (1,0) [0|4294967295] ""  gtw
 SG_ PCS_partNumChar17 m27 : 24|8@1+ (1,0) [0|255] ""  gtw
 SG_ PCS_partNumChar03 m25 : 24|8@1+ (1,0) [0|255] ""  gtw
 SG_ PCS_partNumChar10 m26 : 24|8@1+ (1,0) [0|255] ""  gtw
 SG_ PCS_assemblyId m11 : 24|8@1+ (1,0) [0|255] ""  gtw
 SG_ PCS_serialNumChar10 m30 : 24|8@1+ (1,0) [0|255] ""  gtw
 SG_ PCS_serialNumChar03 m29 : 24|8@1+ (1,0) [0|255] ""  gtw
 SG_ PCS_partNumChar16 m27 : 16|8@1+ (1,0) [0|255] ""  gtw
 SG_ PCS_pcbaId m11 : 16|8@1+ (1,0) [0|255] ""  gtw
 SG_ PCS_partNumChar09 m26 : 16|8@1+ (1,0) [0|255] ""  gtw
 SG_ PCS_partNumChar02 m25 : 16|8@1+ (1,0) [0|255] ""  gtw
 SG_ PCS_buildConfigId m10 : 16|16@1+ (1,0) [0|65535] ""  gtw
 SG_ PCS_serialNumChar02 m29 : 16|8@1+ (1,0) [0|255] ""  gtw
 SG_ PCS_serialNumChar09 m30 : 16|8@1+ (1,0) [0|255] ""  gtw
 SG_ PCS_buildType m10 : 8|8@1+ (1,0) [0|4] ""  gtw
 SG_ PCS_bootGitHash m18 : 8|56@1+ (1,0) [0|72057594037927935] ""  gtw
 SG_ PCS_appGitHash m17 : 8|56@1+ (1,0) [0|72057594037927935] ""  gtw
 SG_ PCS_platformType m13 : 8|8@1+ (1,0) [0|255] ""  gtw
 SG_ PCS_serialNumChar01 m29 : 8|8@1+ (1,0) [0|255] ""  gtw
 SG_ PCS_serialNumChar08 m30 : 8|8@1+ (1,0) [0|255] ""  gtw
 SG_ PCS_partNumChar08 m26 : 8|8@1+ (1,0) [0|255] ""  gtw
 SG_ PCS_partNumChar15 m27 : 8|8@1+ (1,0) [0|255] ""  gtw
 SG_ PCS_partNumChar01 m25 : 8|8@1+ (1,0) [0|255] ""  gtw
 SG_ PCS_bootUdsProtoVersion m20 : 8|8@1+ (1,0) [0|255] ""  gtw
 SG_ PCS_infoIndex M : 0|8@1+ (1,0) [0|255] ""  gtw

BO_ 889 VCSEC_BLERadioStatus: 8 VEH
 SG_ VCSEC_BLEAdvCounterRi m1 : 48|16@1+ (1,0) [0|65535] ""  gtw
 SG_ VCSEC_BLEAdvCounterC m3 : 48|16@1+ (1,0) [0|65535] ""  gtw
 SG_ VCSEC_BLEAdvCounterRe m2 : 48|16@1+ (1,0) [0|65535] ""  gtw
 SG_ VCSEC_BLEAdvCounterL m0 : 48|16@1+ (1,0) [0|65535] ""  gtw
 SG_ VCSEC_BLEHeapMaxUsageRe m2 : 40|7@1+ (1,0) [0|127] ""  gtw
 SG_ VCSEC_BLEHeapMaxUsageL m0 : 40|7@1+ (1,0) [0|127] ""  gtw
 SG_ VCSEC_BLEHeapMaxUsageRi m1 : 40|7@1+ (1,0) [0|127] ""  gtw
 SG_ VCSEC_BLEHeapMaxUsageC m3 : 40|7@1+ (1,0) [0|127] ""  gtw
 SG_ VCSEC_BLEHeapUsageL m0 : 32|7@1+ (1,0) [0|127] ""  gtw
 SG_ VCSEC_BLEHeapUsageRi m1 : 32|7@1+ (1,0) [0|127] ""  gtw
 SG_ VCSEC_BLEHeapUsageC m3 : 32|7@1+ (1,0) [0|127] ""  gtw
 SG_ VCSEC_BLEHeapUsageRe m2 : 32|7@1+ (1,0) [0|127] ""  gtw
 SG_ VCSEC_BLEHeapSizeRe m2 : 16|14@1+ (1,0) [0|16383] ""  gtw
 SG_ VCSEC_BLEHeapSizeL m0 : 16|14@1+ (1,0) [0|16383] ""  gtw
 SG_ VCSEC_BLEHeapSizeRi m1 : 16|14@1+ (1,0) [0|16383] ""  gtw
 SG_ VCSEC_BLEHeapSizeC m3 : 16|14@1+ (1,0) [0|16383] ""  gtw
 SG_ VCSEC_BLECPULoadRe m2 : 8|7@1+ (1,0) [0|127] ""  gtw
 SG_ VCSEC_BLECPULoadL m0 : 8|7@1+ (1,0) [0|127] ""  gtw
 SG_ VCSEC_BLECPULoadRi m1 : 8|7@1+ (1,0) [0|127] ""  gtw
 SG_ VCSEC_BLECPULoadC m3 : 8|7@1+ (1,0) [0|127] ""  gtw
 SG_ VCSEC_BLEAdvStatusRi m1 : 5|3@1+ (1,0) [0|6] ""  gtw
 SG_ VCSEC_BLEAdvStatusC m3 : 5|3@1+ (1,0) [0|6] ""  gtw
 SG_ VCSEC_BLEAdvStatusRe m2 : 5|3@1+ (1,0) [0|6] ""  gtw
 SG_ VCSEC_BLEAdvStatusL m0 : 5|3@1+ (1,0) [0|6] ""  gtw
 SG_ VCSEC_BLEConnectionCounterC m3 : 2|3@1+ (1,0) [0|7] ""  gtw
 SG_ VCSEC_BLEConnectionCounterRe m2 : 2|3@1+ (1,0) [0|7] ""  gtw
 SG_ VCSEC_BLEConnectionCounterRi m1 : 2|3@1+ (1,0) [0|7] ""  gtw
 SG_ VCSEC_BLEConnectionCounterL m0 : 2|3@1+ (1,0) [0|7] ""  gtw
 SG_ VCSEC_BLEDeviceIndex M : 0|2@1+ (1,0) [0|3] ""  X

BO_ 1876 XCP_vcfrontRequest: 8 VEH
 SG_ XCP_vcfrontRequestData : 7|64@0+ (1,0) [0|18446744073709551615] ""  vcfront

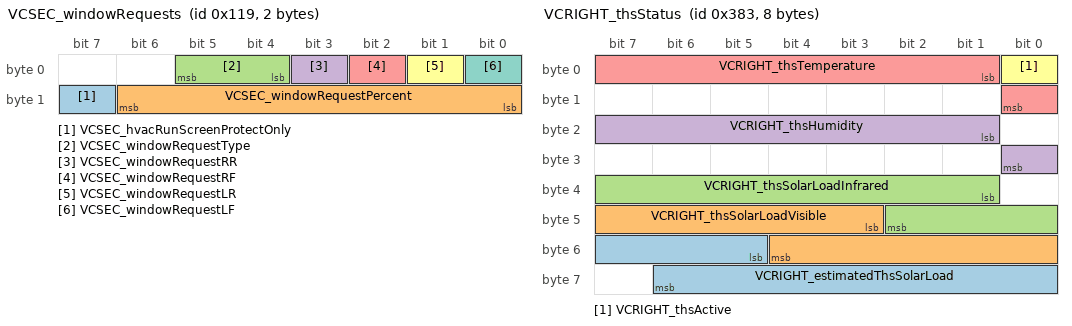
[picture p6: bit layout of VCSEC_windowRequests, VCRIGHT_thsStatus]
BO_ 281 VCSEC_windowRequests: 2 VEH
 SG_ VCSEC_hvacRunScreenProtectOnly : 15|1@1+ (1,0) [0|1] ""  gtw
 SG_ VCSEC_windowRequestPercent : 8|7@1+ (1,0) [0|127] ""  vcleft
 SG_ VCSEC_windowRequestType : 4|2@1+ (1,0) [0|3] ""  gtw
 SG_ VCSEC_windowRequestRR : 3|1@1+ (1,0) [0|1] ""  gtw
 SG_ VCSEC_windowRequestRF : 2|1@1+ (1,0) [0|1] ""  gtw
 SG_ VCSEC_windowRequestLR : 1|1@1+ (1,0) [0|1] ""  gtw
 SG_ VCSEC_windowRequestLF : 0|1@1+ (1,0) [0|1] ""  gtw

BO_ 899 VCRIGHT_thsStatus: 8 VEH
 SG_ VCRIGHT_estimatedThsSolarLoad : 53|10@1+ (1,0) [0|1022] "W/m2"  gtw
 SG_ VCRIGHT_thsSolarLoadVisible : 43|10@1+ (1,0) [0|1022] "W/m2"  gtw
 SG_ VCRIGHT_thsSolarLoadInfrared : 33|10@1+ (1,0) [0|1022] "W/m2"  gtw
 SG_ VCRIGHT_thsHumidity : 17|8@1+ (1,0) [0|100] "%"  das
 SG_ VCRIGHT_thsTemperature : 1|8@1- (1,-40) [-40|150] "degC"  das
 SG_ VCRIGHT_thsActive : 0|1@1+ (1,0) [0|1] ""  das

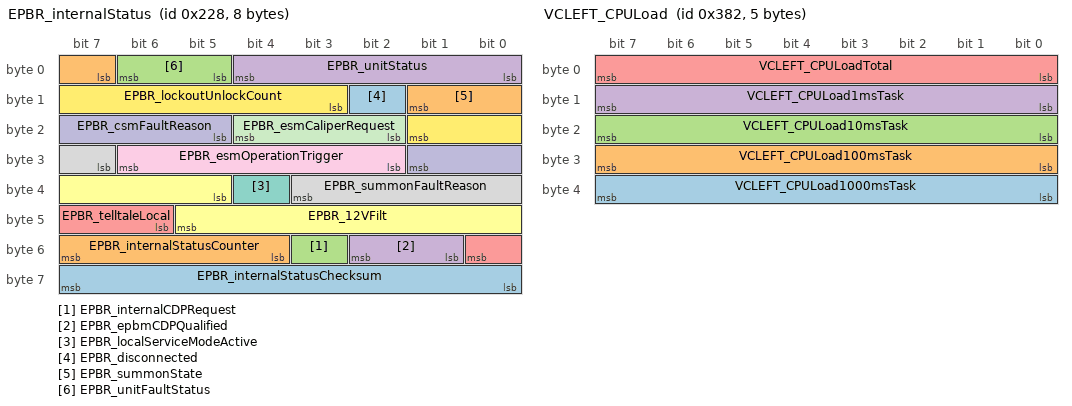
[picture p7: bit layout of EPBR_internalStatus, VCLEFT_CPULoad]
BO_ 552 EPBR_internalStatus: 8 VEH
 SG_ EPBR_internalStatusChecksum : 56|8@1+ (1,0) [0|255] ""  X
 SG_ EPBR_internalStatusCounter : 52|4@1+ (1,0) [0|15] ""  X
 SG_ EPBR_internalCDPRequest : 51|1@1+ (1,0) [0|1] ""  epbl
 SG_ EPBR_epbmCDPQualified : 49|2@1+ (1,0) [0|2] ""  X
 SG_ EPBR_telltaleLocal : 46|3@1+ (1,0) [0|7] ""  epbl
 SG_ EPBR_12VFilt : 37|9@1+ (0.043549408784,0) [0|22.25375] "V"  gtw
 SG_ EPBR_localServiceModeActive : 36|1@1+ (1,0) [0|1] ""  epbl
 SG_ EPBR_summonFaultReason : 31|5@1+ (1,0) [0|28] ""  gtw
 SG_ EPBR_esmOperationTrigger : 26|5@1+ (1,0) [0|30] ""  gtw
 SG_ EPBR_csmFaultReason : 21|5@1+ (1,0) [0|21] ""  gtw
 SG_ EPBR_esmCaliperRequest : 18|3@1+ (1,0) [0|4] ""  gtw
 SG_ EPBR_lockoutUnlockCount : 11|7@1+ (1,0) [0|127] ""  gtw
 SG_ EPBR_disconnected : 10|1@1+ (1,0) [0|1] ""  epbl
 SG_ EPBR_summonState : 7|3@1+ (1,0) [0|6] ""  epbl
 SG_ EPBR_unitFaultStatus : 5|2@1+ (1,0) [0|3] ""  epbl
 SG_ EPBR_unitStatus : 0|5@1+ (1,0) [0|21] ""  epbl

BO_ 915 VCRIGHT_epbmDebug: 8 VEH
 SG_ VCRIGHT_epbFaultStatus m0 : 61|2@1+ (1,0) [0|3] ""  gtw
 SG_ VCRIGHT_epbmFaultStatus m0 : 59|2@1+ (1,0) [0|3] ""  gtw
 SG_ VCRIGHT_epbUnitStatus m0 : 54|5@1+ (1,0) [0|21] ""  gtw
 SG_ VCRIGHT_epbmUnitStatus m0 : 49|5@1+ (1,0) [0|21] ""  gtw
 SG_ VCRIGHT_epbmSummonState m0 : 46|3@1+ (1,0) [0|6] ""  gtw
 SG_ VCRIGHT_epbSummonState m0 : 43|3@1+ (1,0) [0|6] ""  gtw
 SG_ VCRIGHT_summonFaultReason m0 : 38|5@1+ (1,0) [0|28] ""  gtw
 SG_ VCRIGHT_epbmReleaseVoltage m0 : 27|11@1+ (0.01,0) [0|20.47] "A"  X
 SG_ VCRIGHT_cdpEnumDummy m1 : 24|2@1+ (1,0) [0|2] ""  X
 SG_ VCRIGHT_summonUnavailableAllowed m1 : 22|1@1+ (1,0) [0|1] ""  X
 SG_ VCRIGHT_summonFaultAllowed m1 : 21|1@1+ (1,0) [0|1] ""  X
 SG_ VCRIGHT_summonCompleteAllowed m1 : 20|1@1+ (1,0) [0|1] ""  X
 SG_ VCRIGHT_summonActiveAllowed m1 : 19|1@1+ (1,0) [0|1] ""  X
 SG_ VCRIGHT_summonArmedAllowed m1 : 18|1@1+ (1,0) [0|1] ""  X
 SG_ VCRIGHT_summonIdleAllowed m1 : 17|1@1+ (1,0) [0|1] ""  X
 SG_ VCRIGHT_epbmApplyVoltage m0 : 16|11@1+ (0.01,0) [0|20.47] "A"  X
 SG_ VCRIGHT_epbmUnknownAllowed m1 : 16|1@1+ (1,0) [0|1] ""  X
 SG_ VCRIGHT_summonInitAllowed m1 : 15|1@1+ (1,0) [0|1] ""  X
 SG_ VCRIGHT_epbmSummonReleaseAllowed m1 : 14|1@1+ (1,0) [0|1] ""  X
 SG_ VCRIGHT_epbmSummonParkAllowed m1 : 13|1@1+ (1,0) [0|1] ""  X
 SG_ VCRIGHT_epbmSummonAllowed m1 : 12|1@1+ (1,0) [0|1] ""  X
 SG_ VCRIGHT_epbmFaultAllowed m1 : 11|1@1+ (1,0) [0|1] ""  X
 SG_ VCRIGHT_epbmReleasingAllowed m1 : 10|1@1+ (1,0) [0|1] ""  X
 SG_ VCRIGHT_epbmDynApplyingAllowed m1 : 9|1@1+ (1,0) [0|1] ""  X
 SG_ VCRIGHT_epbmParkingAllowed m1 : 8|1@1+ (1,0) [0|1] ""  X
 SG_ VCRIGHT_epbmWinchReleaseAllowed m1 : 7|1@1+ (1,0) [0|1] ""  X
 SG_ VCRIGHT_epbmWinchAllowed m1 : 6|1@1+ (1,0) [0|1] ""  X
 SG_ VCRIGHT_epbmServiceAllowed m1 : 5|1@1+ (1,0) [0|1] ""  X
 SG_ VCRIGHT_epbMotorCurrent m0 : 5|11@1+ (0.01,0) [0|20.47] "A"  X
 SG_ VCRIGHT_epbmStartAllowed m1 : 4|1@1+ (1,0) [0|1] ""  X
 SG_ VCRIGHT_epbmMotorEnabled m0 : 4|1@1+ (1,0) [0|1] ""  X
 SG_ VCRIGHT_epbmParkAllowed m1 : 3|1@1+ (1,0) [0|1] ""  X
 SG_ VCRIGHT_epbmDynamicAllowed m1 : 2|1@1+ (1,0) [0|1] ""  X
 SG_ VCRIGHT_epbmCaliperState m0 : 1|3@1+ (1,0) [0|5] ""  X
 SG_ VCRIGHT_epbmOpenAllowed m1 : 1|1@1+ (1,0) [0|1] ""  X
 SG_ VCRIGHT_epbmDebugIndex M : 0|1@1+ (1,0) [0|1] ""  X

BO_ 1890 VCLEFT_xcpResponse: 8 VEH
 SG_ VCLEFT_xcpResponseData : 0|64@1+ (1,0) [0|18446744073709551615] ""  X

BO_ 898 VCLEFT_CPULoad: 5 VEH
 SG_ VCLEFT_CPULoad1000msTask : 32|8@1+ (1,0) [0|255] ""  X
 SG_ VCLEFT_CPULoad100msTask : 24|8@1+ (1,0) [0|255] ""  X
 SG_ VCLEFT_CPULoad10msTask : 16|8@1+ (1,0) [0|255] ""  X
 SG_ VCLEFT_CPULoad1msTask : 8|8@1+ (1,0) [0|255] ""  X
 SG_ VCLEFT_CPULoadTotal : 0|8@1+ (1,0) [0|255] ""  X

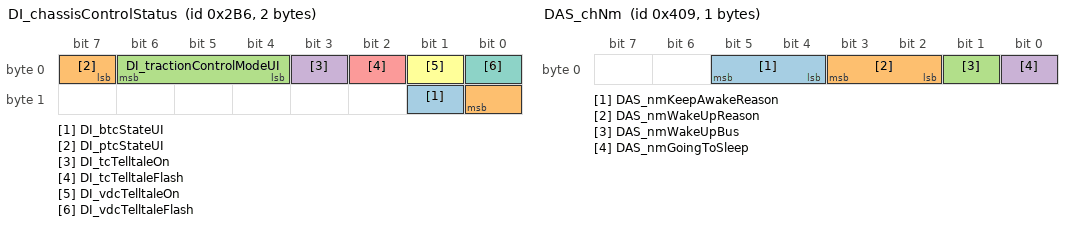
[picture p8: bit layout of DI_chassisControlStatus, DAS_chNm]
BO_ 694 DI_chassisControlStatus: 2 VEH
 SG_ DI_btcStateUI : 9|1@1+ (1,0) [0|1] ""  gtw
 SG_ DI_ptcStateUI : 7|2@1+ (1,0) [0|3] ""  X
 SG_ DI_tractionControlModeUI : 4|3@1+ (1,0) [0|5] ""  gtw
 SG_ DI_tcTelltaleOn : 3|1@1+ (1,0) [0|1] ""  gtw
 SG_ DI_tcTelltaleFlash : 2|1@1+ (1,0) [0|1] ""  gtw
 SG_ DI_vdcTelltaleOn : 1|1@1+ (1,0) [0|1] ""  gtw
 SG_ DI_vdcTelltaleFlash : 0|1@1+ (1,0) [0|1] ""  gtw

BO_ 1033 DAS_chNm: 1 VEH
 SG_ DAS_nmKeepAwakeReason : 4|2@1+ (1,0) [0|2] ""  vcfront
 SG_ DAS_nmWakeUpReason : 2|2@1+ (1,0) [0|3] ""  X
 SG_ DAS_nmWakeUpBus : 1|1@1+ (1,0) [0|1] ""  X
 SG_ DAS_nmGoingToSleep : 0|1@1+ (1,0) [0|1] ""  X

BO_ 706 VCLEFT_windowStatus: 8 VEH
 SG_ VCLEFT_windowCalibratedLR m0 : 62|1@1+ (1,0) [0|1] ""  gtw
 SG_ VCLEFT_positionLR m0 : 54|8@1+ (10,0) [0|2550] "ticks"  gtw
 SG_ VCLEFT_windowStopReqReasonLR m1 : 48|4@1+ (1,0) [0|8] ""  gtw
 SG_ VCLEFT_motorCurrentLR m0 : 48|6@1- (0.5,0.0) [-15|15] "A"  X
 SG_ VCLEFT_windowStopReasonLR m1 : 42|3@1+ (1,0) [0|6] ""  gtw
 SG_ VCLEFT_windowThermalModeLR m1 : 40|2@1+ (1,0) [0|3] ""  X
 SG_ VCLEFT_motorDutyLR m0 : 40|6@1- (5,0) [-100|100] "%"  X
 SG_ VCLEFT_windowStateLR m0 : 33|4@1+ (1,0) [0|8] ""  gtw
 SG_ VCLEFT_ThermalTCLR m1 : 32|8@1+ (1,0) [0|255] "s"  X
 SG_ VCLEFT_windowCalibratedLF m0 : 32|1@1+ (1,0) [0|1] ""  gtw
 SG_ VCLEFT_positionLF m0 : 24|8@1+ (10,0) [0|2550] "ticks"  gtw
 SG_ VCLEFT_windowStopReqReasonLF m1 : 24|4@1+ (1,0) [0|8] ""  gtw
 SG_ VCLEFT_windowStopReasonLF m1 : 18|3@1+ (1,0) [0|6] ""  gtw
 SG_ VCLEFT_motorCurrentLF m0 : 16|6@1- (0.5,0.0) [-15|15] "A"  X
 SG_ VCLEFT_windowThermalModeLF m1 : 16|2@1+ (1,0) [0|3] ""  X
 SG_ VCLEFT_motorDutyLF m0 : 8|6@1- (5,0) [-100|100] "%"  X
 SG_ VCLEFT_ThermalTCLF m1 : 8|8@1+ (1,0) [0|255] "s"  X
 SG_ VCLEFT_windowStateLF m0 : 1|4@1+ (1,0) [0|8] ""  gtw
 SG_ VCLEFT_windowStatusIndex M : 0|1@1+ (1,0) [0|1] ""  X

BO_ 1330 EPBR_bootID: 8 VEH
 SG_ EPBR_bootIdData : 0|64@1+ (1,0) [0|18446744073709551615] ""  gtwu

BO_ 1332 VCFRONT_alertLog: 8 VEH
 SG_ VCFRONT_a188_VCRIGHTKeepAwake m188 : 63|1@1+ (1,0) [0|1] ""  gtw
 SG_ VCFRONT_a188_VCLEFTKeepAwake m188 : 62|1@1+ (1,0) [0|1] ""  gtw
 SG_ VCFRONT_a188_VCSECKeepAwake m188 : 61|1@1+ (1,0) [0|1] ""  gtw
 SG_ VCFRONT_a258_completed m258 : 61|1@1+ (1,0) [0|1] ""  gtw
 SG_ VCFRONT_a188_DASKeepAwake m188 : 60|1@1+ (1,0) [0|1] ""  gtw
 SG_ VCFRONT_a258_lowCapacity m258 : 60|1@1+ (1,0) [0|1] ""  gtw
 SG_ VCFRONT_a188_UIKeepAwake m188 : 59|1@1+ (1,0) [0|1] ""  gtw
 SG_ VCFRONT_a188_CANAfterQuiet m188 : 58|1@1+ (1,0) [0|1] ""  gtw
 SG_ VCFRONT_a188_accessoryRequest m188 : 57|1@1+ (1,0) [0|1] ""  gtw
 SG_ VCFRONT_a041_CPULoadNVMMTask m41 : 56|8@1+ (1,0) [0|255] ""  gtw
 SG_ VCFRONT_a022_TaskInitError4 m22 : 56|8@1+ (1,0) [0|255] ""  gtw
 SG_ VCFRONT_a042_UsageNVMMTask m42 : 56|8@1+ (1,0) [0|255] ""  gtw
 SG_ VCFRONT_a188_ThermalSupport m188 : 56|1@1+ (1,0) [0|1] ""  gtw
 SG_ VCFRONT_a188_12VSupport m188 : 55|1@1+ (1,0) [0|1] ""  gtw
 SG_ VCFRONT_a260_notEnoughPowerForSu m260 : 54|1@1+ (1,0) [0|1] ""  gtw
 SG_ VCFRONT_a188_chargeRequest m188 : 54|1@1+ (1,0) [0|1] ""  gtw
 SG_ VCFRONT_a334_vehicleState m334 : 52|2@1+ (1,0) [0|3] ""  gtw
 SG_ VCFRONT_a346_vehicleState m346 : 52|2@1+ (1,0) [0|3] ""  gtw
 SG_ VCFRONT_a339_vehicleState m339 : 52|2@1+ (1,0) [0|3] ""  gtw
 SG_ VCFRONT_a345_vehicleState m345 : 52|2@1+ (1,0) [0|3] ""  gtw
 SG_ VCFRONT_a340_vehicleState m340 : 52|2@1+ (1,0) [0|3] ""  gtw
 SG_ VCFRONT_a187_chBusRetryCount m187 : 52|9@1+ (1,0) [0|511] ""  gtw
 SG_ VCFRONT_a335_vehicleState m335 : 52|2@1+ (1,0) [0|3] ""  gtw
 SG_ VCFRONT_a336_vehicleState m336 : 52|2@1+ (1,0) [0|3] ""  gtw
 SG_ VCFRONT_a349_vehicleState m349 : 52|2@1+ (1,0) [0|3] ""  gtw
 SG_ VCFRONT_a344_vehicleState m344 : 52|2@1+ (1,0) [0|3] ""  gtw
 SG_ VCFRONT_a343_vehicleState m343 : 52|2@1+ (1,0) [0|3] ""  gtw
 SG_ VCFRONT_a348_vehicleState m348 : 52|2@1+ (1,0) [0|3] ""  gtw
 SG_ VCFRONT_a337_vehicleState m337 : 52|2@1+ (1,0) [0|3] ""  gtw
 SG_ VCFRONT_a338_vehicleState m338 : 52|2@1+ (1,0) [0|3] ""  gtw
 SG_ VCFRONT_a347_vehicleState m347 : 52|2@1+ (1,0) [0|3] ""  gtw
 SG_ VCFRONT_a342_vehicleState m342 : 52|2@1+ (1,0) [0|3] ""  gtw
 SG_ VCFRONT_a341_vehicleState m341 : 52|2@1+ (1,0) [0|3] ""  gtw
 SG_ VCFRONT_a311_vehicleState m311 : 51|2@1+ (1,0) [0|3] ""  gtw
 SG_ VCFRONT_a316_vehicleState m316 : 51|2@1+ (1,0) [0|3] ""  gtw
 SG_ VCFRONT_a320_vehicleState m320 : 51|2@1+ (1,0) [0|3] ""  gtw
 SG_ VCFRONT_a323_vehicleState m323 : 51|2@1+ (1,0) [0|3] ""  gtw
 SG_ VCFRONT_a318_vehicleState m318 : 51|2@1+ (1,0) [0|3] ""  gtw
 SG_ VCFRONT_a312_vehicleState m312 : 51|2@1+ (1,0) [0|3] ""  gtw
 SG_ VCFRONT_a317_vehicleState m317 : 51|2@1+ (1,0) [0|3] ""  gtw
 SG_ VCFRONT_a314_vehicleState m314 : 51|2@1+ (1,0) [0|3] ""  gtw
 SG_ VCFRONT_a322_vehicleState m322 : 51|2@1+ (1,0) [0|3] ""  gtw
 SG_ VCFRONT_a319_vehicleState m319 : 51|2@1+ (1,0) [0|3] ""  gtw
 SG_ VCFRONT_a325_vehicleState m325 : 51|2@1+ (1,0) [0|3] ""  gtw
 SG_ VCFRONT_a313_vehicleState m313 : 51|2@1+ (1,0) [0|3] ""  gtw
 SG_ VCFRONT_a310_vehicleState m310 : 51|2@1+ (1,0) [0|3] ""  gtw
 SG_ VCFRONT_a260_hvState m260 : 51|3@1+ (1,0) [0|6] ""  gtw
 SG_ VCFRONT_a315_vehicleState m315 : 51|2@1+ (1,0) [0|3] ""  gtw
 SG_ VCFRONT_a321_vehicleState m321 : 51|2@1+ (1,0) [0|3] ""  gtw
 SG_ VCFRONT_a324_vehicleState m324 : 51|2@1+ (1,0) [0|3] ""  gtw
 SG_ VCFRONT_a252_IBSCurrent m252 : 48|16@1- (0.005,0) [-163.84|163.835] "A"  gtw
 SG_ VCFRONT_a333_vehicleState m333 : 48|2@1+ (1,0) [0|3] ""  gtw
 SG_ VCFRONT_a022_TaskInitError3 m22 : 48|8@1+ (1,0) [0|255] ""  gtw
 SG_ VCFRONT_a213_IBSTemp m213 : 48|16@1- (0.01,0) [-327.68|327.67] "degC"  gtw
 SG_ VCFRONT_a042_UsageUDSTask m42 : 48|8@1+ (1,0) [0|255] ""  gtw
 SG_ VCFRONT_a133_espEFuseTemp m133 : 48|11@1+ (0.125,-40) [-40|150] "degC"  gtw
 SG_ VCFRONT_a183_maxCurrentReached m183 : 48|16@1- (0.005,0) [-163.84|163.835] "A"  gtw
 SG_ VCFRONT_a326_vehicleState m326 : 48|2@1+ (1,0) [0|3] ""  gtw
 SG_ VCFRONT_a329_vehicleState m329 : 48|2@1+ (1,0) [0|3] ""  gtw
 SG_ VCFRONT_a330_vehicleState m330 : 48|2@1+ (1,0) [0|3] ""  gtw
 SG_ VCFRONT_a243_IBSTemp m243 : 48|16@1- (0.01,0) [-327.68|327.67] "degC"  gtw
 SG_ VCFRONT_a003_Data m3 : 48|16@1+ (1,0) [0|65535] ""  gtw
 SG_ VCFRONT_a000_alertDataW2 m0 : 48|16@1+ (1,0) [0|65535] ""  X
 SG_ VCFRONT_a219_IBSCurrent m219 : 48|16@1- (0.005,0) [-163.84|163.835] "A"  gtw
 SG_ VCFRONT_a328_vehicleState m328 : 48|2@1+ (1,0) [0|3] ""  gtw
 SG_ VCFRONT_a331_vehicleState m331 : 48|2@1+ (1,0) [0|3] ""  gtw
 SG_ VCFRONT_a129_pcsEFuseTemp m129 : 48|11@1+ (0.125,-40) [-40|150] "degC"  gtw
 SG_ VCFRONT_a127_vcleftEFuseTemp m127 : 48|11@1+ (0.125,-40) [-40|150] "degC"  gtw
 SG_ VCFRONT_a134_fusedHighTemp m134 : 48|11@1+ (0.125,-40) [-40|150] "degC"  gtw
 SG_ VCFRONT_a332_vehicleState m332 : 48|2@1+ (1,0) [0|3] ""  gtw
 SG_ VCFRONT_a131_epas3sEFuseTemp m131 : 48|11@1+ (0.125,-40) [-40|150] "degC"  gtw
 SG_ VCFRONT_a260_batterySMState m260 : 48|3@1+ (1,0) [0|7] ""  gtw
 SG_ VCFRONT_a253_IBSTemp m253 : 48|16@1- (0.01,0) [-327.68|327.67] "degC"  gtw
 SG_ VCFRONT_a041_CPULoad1000msTask m41 : 48|8@1+ (1,0) [0|255] ""  gtw
 SG_ VCFRONT_a132_iBoosterEFuseTemp m132 : 48|11@1+ (0.125,-40) [-40|150] "degC"  gtw
 SG_ VCFRONT_a259_maxCurrentReached m259 : 48|16@1- (0.005,0) [-163.84|163.835] "A"  gtw
 SG_ VCFRONT_a128_vcrightEFuseTemp m128 : 48|11@1+ (0.125,-40) [-40|150] "degC"  gtw
 SG_ VCFRONT_a130_epas3pEFuseTemp m130 : 48|11@1+ (0.125,-40) [-40|150] "degC"  gtw
 SG_ VCFRONT_a327_vehicleState m327 : 48|2@1+ (1,0) [0|3] ""  gtw
 SG_ VCFRONT_a260_vehiclePowerState m260 : 46|2@1+ (1,0) [0|3] ""  gtw
 SG_ VCFRONT_a188_timeNotSleeping m188 : 45|9@1+ (1,0) [0|511] "sec"  gtw
 SG_ VCFRONT_a258_maxCurrentReached m258 : 44|16@1- (0.005,0) [-163.84|163.835] "A"  gtw
 SG_ VCFRONT_a063_faulted m63 : 43|1@1+ (1,0) [0|1] ""  gtw
 SG_ VCFRONT_a257_vehicleState m257 : 43|5@1+ (1,0) [0|17] ""  gtw
 SG_ VCFRONT_a187_ethBusRetryCount m187 : 43|9@1+ (1,0) [0|511] ""  gtw
 SG_ VCFRONT_a257_revBattFault m257 : 42|1@1+ (1,0) [0|1] ""  gtw
 SG_ VCFRONT_a063_stuckActive m63 : 42|1@1+ (1,0) [0|1] ""  gtw
 SG_ VCFRONT_a063_indeterminate m63 : 41|1@1+ (1,0) [0|1] ""  gtw
 SG_ VCFRONT_a257_epas3sFault m257 : 41|1@1+ (1,0) [0|1] ""  gtw
 SG_ VCFRONT_a321_avgTemp m321 : 40|11@1+ (0.125,-40) [-40|150] "degC"  gtw
 SG_ VCFRONT_a063_disconnected m63 : 40|1@1+ (1,0) [0|1] ""  gtw
 SG_ VCFRONT_a315_avgTemp m315 : 40|11@1+ (0.125,-40) [-40|150] "degC"  gtw
 SG_ VCFRONT_a349_maxCurrent m349 : 40|12@1+ (0.1,0) [0|409.5] "A"  gtw
 SG_ VCFRONT_a336_maxCurrent m336 : 40|12@1+ (0.1,0) [0|409.5] "A"  gtw
 SG_ VCFRONT_a045_CallTrace1 m45 : 40|24@1+ (1,0) [0|16777215] ""  gtw
 SG_ VCFRONT_a310_avgTemp m310 : 40|11@1+ (0.125,-40) [-40|150] "degC"  gtw
 SG_ VCFRONT_a188_vehicleState m188 : 40|5@1+ (1,0) [0|17] ""  gtw
 SG_ VCFRONT_a344_maxCurrent m344 : 40|12@1+ (0.1,0) [0|409.5] "A"  gtw
 SG_ VCFRONT_a022_TaskInitError2 m22 : 40|8@1+ (1,0) [0|255] ""  gtw
 SG_ VCFRONT_a347_maxCurrent m347 : 40|12@1+ (0.1,0) [0|409.5] "A"  gtw
 SG_ VCFRONT_a338_maxCurrent m338 : 40|12@1+ (0.1,0) [0|409.5] "A"  gtw
 SG_ VCFRONT_a182_12VFloorCount m182 : 40|4@1+ (1,0) [0|15] ""  gtw
 SG_ VCFRONT_a059_current m59 : 40|12@1+ (0.05,0) [0|204.75] "A"  gtw
 SG_ VCFRONT_a320_avgTemp m320 : 40|11@1+ (0.125,-40) [-40|150] "degC"  gtw
 SG_ VCFRONT_a316_avgTemp m316 : 40|11@1+ (0.125,-40) [-40|150] "degC"  gtw
 SG_ VCFRONT_a342_maxCurrent m342 : 40|12@1+ (0.1,0) [0|409.5] "A"  gtw
 SG_ VCFRONT_a311_avgTemp m311 : 40|11@1+ (0.125,-40) [-40|150] "degC"  gtw
 SG_ VCFRONT_a041_CPULoad100msTask m41 : 40|8@1+ (1,0) [0|255] ""  gtw
 SG_ VCFRONT_a348_maxCurrent m348 : 40|12@1+ (0.1,0) [0|409.5] "A"  gtw
 SG_ VCFRONT_a337_maxCurrent m337 : 40|12@1+ (0.1,0) [0|409.5] "A"  gtw
 SG_ VCFRONT_a044_CallTrace1 m44 : 40|24@1+ (1,0) [0|16777215] ""  gtw
 SG_ VCFRONT_a334_maxCurrent m334 : 40|12@1+ (0.1,0) [0|409.5] "A"  gtw
 SG_ VCFRONT_a042_Usage1000msTask m42 : 40|8@1+ (1,0) [0|255] ""  gtw
 SG_ VCFRONT_a317_avgTemp m317 : 40|11@1+ (0.125,-40) [-40|150] "degC"  gtw
 SG_ VCFRONT_a346_maxCurrent m346 : 40|12@1+ (0.1,0) [0|409.5] "A"  gtw
 SG_ VCFRONT_a339_maxCurrent m339 : 40|12@1+ (0.1,0) [0|409.5] "A"  gtw
 SG_ VCFRONT_a312_avgTemp m312 : 40|11@1+ (0.125,-40) [-40|150] "degC"  gtw
 SG_ VCFRONT_a341_maxCurrent m341 : 40|12@1+ (0.1,0) [0|409.5] "A"  gtw
 SG_ VCFRONT_a318_avgTemp m318 : 40|11@1+ (0.125,-40) [-40|150] "degC"  gtw
 SG_ VCFRONT_a323_avgTemp m323 : 40|11@1+ (0.125,-40) [-40|150] "degC"  gtw
 SG_ VCFRONT_a283_thmlFanPhaseILimit m283 : 40|7@1+ (0.25,0) [5|35] "A"  gtw
 SG_ VCFRONT_a257_epas3pFault m257 : 40|1@1+ (1,0) [0|1] ""  gtw
 SG_ VCFRONT_a043_CallTrace1 m43 : 40|24@1+ (1,0) [0|16777215] ""  gtw
 SG_ VCFRONT_a313_avgTemp m313 : 40|11@1+ (0.125,-40) [-40|150] "degC"  gtw
 SG_ VCFRONT_a335_maxCurrent m335 : 40|12@1+ (0.1,0) [0|409.5] "A"  gtw
 SG_ VCFRONT_a046_CallTrace1 m46 : 40|24@1+ (1,0) [0|16777215] ""  gtw
 SG_ VCFRONT_a325_avgTemp m325 : 40|11@1+ (0.125,-40) [-40|150] "degC"  gtw
 SG_ VCFRONT_a319_avgTemp m319 : 40|11@1+ (0.125,-40) [-40|150] "degC"  gtw
 SG_ VCFRONT_a345_maxCurrent m345 : 40|12@1+ (0.1,0) [0|409.5] "A"  gtw
 SG_ VCFRONT_a322_avgTemp m322 : 40|11@1+ (0.125,-40) [-40|150] "degC"  gtw
 SG_ VCFRONT_a314_avgTemp m314 : 40|11@1+ (0.125,-40) [-40|150] "degC"  gtw
 SG_ VCFRONT_a340_maxCurrent m340 : 40|12@1+ (0.1,0) [0|409.5] "A"  gtw
 SG_ VCFRONT_a343_maxCurrent m343 : 40|12@1+ (0.1,0) [0|409.5] "A"  gtw
 SG_ VCFRONT_a324_avgTemp m324 : 40|11@1+ (0.125,-40) [-40|150] "degC"  gtw
 SG_ VCFRONT_a257_espFault m257 : 39|1@1+ (1,0) [0|1] ""  gtw
 SG_ VCFRONT_a257_iBoosterFault m257 : 38|1@1+ (1,0) [0|1] ""  gtw
 SG_ VCFRONT_a257_vbatFusedFault m257 : 37|1@1+ (1,0) [0|1] ""  gtw
 SG_ VCFRONT_a182_lowCapacityCount m182 : 36|4@1+ (1,0) [0|15] ""  gtw
 SG_ VCFRONT_a257_pcsFault m257 : 36|1@1+ (1,0) [0|1] ""  gtw
 SG_ VCFRONT_a257_vcrightFault m257 : 35|1@1+ (1,0) [0|1] ""  gtw
 SG_ VCFRONT_a257_vcleftFault m257 : 34|1@1+ (1,0) [0|1] ""  gtw
 SG_ VCFRONT_a187_hvsBusRetryCount m187 : 34|9@1+ (1,0) [0|511] ""  gtw
 SG_ VCFRONT_a328_maxCurrent m328 : 32|16@1+ (0.1,0) [0|6553.5] "A"  gtw
 SG_ VCFRONT_a331_maxCurrent m331 : 32|16@1+ (0.1,0) [0|6553.5] "A"  gtw
 SG_ VCFRONT_a130_epas3pEFuseVoltage m130 : 32|16@1+ (0.1,0) [0|6553.5] "V"  gtw
 SG_ VCFRONT_a128_vcrightEFuseVoltage m128 : 32|16@1+ (0.1,0) [0|6553.5] "V"  gtw
 SG_ VCFRONT_a265_vbatProtVoltage m265 : 32|16@1+ (0.1,0) [0|6553.5] "V"  gtw
 SG_ VCFRONT_a253_IBSAmpHours m253 : 32|14@1- (0.01,0) [-81.92|81.91] "Ah"  gtw
 SG_ VCFRONT_a219_IBSAh m219 : 32|14@1- (0.01,0) [-81.92|81.91] "Ah"  gtw
 SG_ VCFRONT_a134_fusedHighVoltage m134 : 32|16@1+ (0.1,0) [0|6553.5] "V"  gtw
 SG_ VCFRONT_a003_LineNumber m3 : 32|16@1+ (1,0) [0|65535] ""  gtw
 SG_ VCFRONT_a131_epas3sEFuseVoltage m131 : 32|16@1+ (0.1,0) [0|6553.5] "V"  gtw
 SG_ VCFRONT_a129_pcsEFuseVoltage m129 : 32|16@1+ (0.1,0) [0|6553.5] "V"  gtw
 SG_ VCFRONT_a266_vbatProtVoltage m266 : 32|16@1+ (0.1,0) [0|6553.5] "V"  gtw
 SG_ VCFRONT_a214_airCompDriverPWM m214 : 32|16@1+ (0.005,0) [0|327.675] "%"  gtw
 SG_ VCFRONT_a127_vcleftEFuseVoltage m127 : 32|16@1+ (0.1,0) [0|6553.5] "V"  gtw
 SG_ VCFRONT_a261_vbatProtVoltage m261 : 32|16@1+ (0.1,0) [0|6553.5] "V"  gtw
 SG_ VCFRONT_a332_maxCurrent m332 : 32|16@1+ (0.1,0) [0|6553.5] "A"  gtw
 SG_ VCFRONT_a246_voltage m246 : 32|16@1+ (0.1,0) [0|6553.5] "V"  gtw
 SG_ VCFRONT_a267_vbatProtVoltage m267 : 32|16@1+ (0.1,0) [0|6553.5] "V"  gtw
 SG_ VCFRONT_a132_iBoosterVoltage m132 : 32|16@1+ (0.1,0) [0|6553.5] "V"  gtw
 SG_ VCFRONT_a243_IBSCurrent m243 : 32|16@1- (0.005,0) [-163.84|163.835] "A"  gtw
 SG_ VCFRONT_a262_vbatProtVoltage m262 : 32|16@1+ (0.1,0) [0|6553.5] "V"  gtw
 SG_ VCFRONT_a182_overchargeCount m182 : 32|4@1+ (1,0) [0|15] ""  gtw
 SG_ VCFRONT_a257_vcrightLockoutStatu m257 : 32|2@1+ (1,0) [0|2] ""  gtw
 SG_ VCFRONT_a327_maxCurrent m327 : 32|16@1+ (0.1,0) [0|6553.5] "A"  gtw
 SG_ VCFRONT_a283_thmlFanPhaseI m283 : 32|7@1+ (0.25,0) [5|35] "A"  gtw
 SG_ VCFRONT_a268_vbatProtVoltage m268 : 32|16@1+ (0.1,0) [0|6553.5] "V"  gtw
 SG_ VCFRONT_a333_maxCurrent m333 : 32|16@1+ (0.1,0) [0|6553.5] "A"  gtw
 SG_ VCFRONT_a022_TaskInitError1 m22 : 32|8@1+ (1,0) [0|255] ""  gtw
 SG_ VCFRONT_a183_IBSTemp m183 : 32|16@1- (0.01,0) [-327.68|327.67] "degC"  gtw
 SG_ VCFRONT_a330_maxCurrent m330 : 32|16@1+ (0.1,0) [0|6553.5] "A"  gtw
 SG_ VCFRONT_a133_espEFuseVoltage m133 : 32|16@1+ (0.1,0) [0|6553.5] "V"  gtw
 SG_ VCFRONT_a329_maxCurrent m329 : 32|16@1+ (0.1,0) [0|6553.5] "A"  gtw
 SG_ VCFRONT_a260_IBSAh m260 : 32|14@1- (0.01,0) [-81.92|81.91] "Ah"  gtw
 SG_ VCFRONT_a263_vbatProtVoltage m263 : 32|16@1+ (0.1,0) [0|6553.5] "V"  gtw
 SG_ VCFRONT_a000_alertDataW1 m0 : 32|16@1+ (1,0) [0|65535] ""  X
 SG_ VCFRONT_a244_voltage m244 : 32|16@1+ (0.1,0) [0|6553.5] "V"  gtw
 SG_ VCFRONT_a041_CPULoad10msTask m41 : 32|8@1+ (1,0) [0|255] ""  gtw
 SG_ VCFRONT_a142_driverHasCommError m142 : 32|1@1+ (1,0) [0|1] ""  gtw
 SG_ VCFRONT_a252_IBSAmpHours m252 : 32|14@1- (0.01,0) [-81.92|81.91] "Ah"  gtw
 SG_ VCFRONT_a264_vbatProtVoltage m264 : 32|16@1+ (0.1,0) [0|6553.5] "V"  gtw
 SG_ VCFRONT_a259_IBSTemp m259 : 32|16@1- (0.01,0) [-327.68|327.67] "degC"  gtw
 SG_ VCFRONT_a326_maxCurrent m326 : 32|16@1+ (0.1,0) [0|6553.5] "A"  gtw
 SG_ VCFRONT_a213_IBSAh m213 : 32|14@1- (0.01,0) [-81.92|81.91] "Ah"  gtw
 SG_ VCFRONT_a042_Usage100msTask m42 : 32|8@1+ (1,0) [0|255] ""  gtw
 SG_ VCFRONT_a245_voltage m245 : 32|16@1+ (0.1,0) [0|6553.5] "V"  gtw
 SG_ VCFRONT_a063_ADCVoltage m63 : 32|8@1+ (0.025,0) [0|6.375] "V"  gtw
 SG_ VCFRONT_a142_isCoilShortYNVbb m142 : 31|1@1+ (1,0) [0|1] ""  gtw
 SG_ VCFRONT_a142_isCoilShortYNGnd m142 : 30|1@1+ (1,0) [0|1] ""  gtw
 SG_ VCFRONT_a142_isCoilShortYPVbb m142 : 29|1@1+ (1,0) [0|1] ""  gtw
 SG_ VCFRONT_a342_avgCurrent m342 : 28|12@1+ (0.1,0) [0|409.5] "A"  gtw
 SG_ VCFRONT_a248_vbatMonitor m248 : 28|12@1+ (0.005443676098,0) [0|22.29185] "V"  gtw
 SG_ VCFRONT_a345_avgCurrent m345 : 28|12@1+ (0.1,0) [0|409.5] "A"  gtw
 SG_ VCFRONT_a258_IBSTemp m258 : 28|16@1- (0.01,0) [-327.68|327.67] "degC"  gtw
 SG_ VCFRONT_a337_avgCurrent m337 : 28|12@1+ (0.1,0) [0|409.5] "A"  gtw
 SG_ VCFRONT_a348_avgCurrent m348 : 28|12@1+ (0.1,0) [0|409.5] "A"  gtw
 SG_ VCFRONT_a334_avgCurrent m334 : 28|12@1+ (0.1,0) [0|409.5] "A"  gtw
 SG_ VCFRONT_a341_avgCurrent m341 : 28|12@1+ (0.1,0) [0|409.5] "A"  gtw
 SG_ VCFRONT_a344_avgCurrent m344 : 28|12@1+ (0.1,0) [0|409.5] "A"  gtw
 SG_ VCFRONT_a059_resistanceEstimate m59 : 28|12@1+ (0.00244,0) [0|9.9918] "Ohms"  gtw
 SG_ VCFRONT_a347_avgCurrent m347 : 28|12@1+ (0.1,0) [0|409.5] "A"  gtw
 SG_ VCFRONT_a338_avgCurrent m338 : 28|12@1+ (0.1,0) [0|409.5] "A"  gtw
 SG_ VCFRONT_a335_avgCurrent m335 : 28|12@1+ (0.1,0) [0|409.5] "A"  gtw
 SG_ VCFRONT_a340_avgCurrent m340 : 28|12@1+ (0.1,0) [0|409.5] "A"  gtw
 SG_ VCFRONT_a343_avgCurrent m343 : 28|12@1+ (0.1,0) [0|409.5] "A"  gtw
 SG_ VCFRONT_a346_avgCurrent m346 : 28|12@1+ (0.1,0) [0|409.5] "A"  gtw
 SG_ VCFRONT_a339_avgCurrent m339 : 28|12@1+ (0.1,0) [0|409.5] "A"  gtw
 SG_ VCFRONT_a349_avgCurrent m349 : 28|12@1+ (0.1,0) [0|409.5] "A"  gtw
 SG_ VCFRONT_a336_avgCurrent m336 : 28|12@1+ (0.1,0) [0|409.5] "A"  gtw
 SG_ VCFRONT_a142_isCoilShortYPGnd m142 : 28|1@1+ (1,0) [0|1] ""  gtw
 SG_ VCFRONT_a021_Task1000msMissed m21 : 27|1@1+ (1,0) [0|1] ""  gtw
 SG_ VCFRONT_a316_maxTemp m316 : 27|11@1+ (0.125,-40) [-40|150] "degC"  gtw
 SG_ VCFRONT_a322_maxTemp m322 : 27|11@1+ (0.125,-40) [-40|150] "degC"  gtw
 SG_ VCFRONT_a319_maxTemp m319 : 27|11@1+ (0.125,-40) [-40|150] "degC"  gtw
 SG_ VCFRONT_a142_isCoilShortXNVbb m142 : 27|1@1+ (1,0) [0|1] ""  gtw
 SG_ VCFRONT_a317_maxTemp m317 : 27|11@1+ (0.125,-40) [-40|150] "degC"  gtw
 SG_ VCFRONT_a321_maxTemp m321 : 27|11@1+ (0.125,-40) [-40|150] "degC"  gtw
 SG_ VCFRONT_a310_maxTemp m310 : 27|11@1+ (0.125,-40) [-40|150] "degC"  gtw
 SG_ VCFRONT_a320_maxTemp m320 : 27|11@1+ (0.125,-40) [-40|150] "degC"  gtw
 SG_ VCFRONT_a325_maxTemp m325 : 27|11@1+ (0.125,-40) [-40|150] "degC"  gtw
 SG_ VCFRONT_a311_maxTemp m311 : 27|11@1+ (0.125,-40) [-40|150] "degC"  gtw
 SG_ VCFRONT_a314_maxTemp m314 : 27|11@1+ (0.125,-40) [-40|150] "degC"  gtw
 SG_ VCFRONT_a159_angleTarget m159 : 27|10@1+ (0.25,-10) [-10|180] "deg"  gtw
 SG_ VCFRONT_a324_maxTemp m324 : 27|11@1+ (0.125,-40) [-40|150] "degC"  gtw
 SG_ VCFRONT_a312_maxTemp m312 : 27|11@1+ (0.125,-40) [-40|150] "degC"  gtw
 SG_ VCFRONT_a315_maxTemp m315 : 27|11@1+ (0.125,-40) [-40|150] "degC"  gtw
 SG_ VCFRONT_a318_maxTemp m318 : 27|11@1+ (0.125,-40) [-40|150] "degC"  gtw
 SG_ VCFRONT_a116_VEH_logging1Hz m116 : 27|1@1+ (1,0) [0|1] ""  gtw
 SG_ VCFRONT_a323_maxTemp m323 : 27|11@1+ (0.125,-40) [-40|150] "degC"  gtw
 SG_ VCFRONT_a313_maxTemp m313 : 27|11@1+ (0.125,-40) [-40|150] "degC"  gtw
 SG_ VCFRONT_a147_RPMTarget m147 : 26|10@1+ (10,0) [0|10000] "RPM"  gtw
 SG_ VCFRONT_a116_VEH_switchStatus m116 : 26|1@1+ (1,0) [0|1] ""  gtw
 SG_ VCFRONT_a151_RPMTarget m151 : 26|10@1+ (10,0) [0|10000] "RPM"  gtw
 SG_ VCFRONT_a148_RPMTarget m148 : 26|10@1+ (10,0) [0|10000] "RPM"  gtw
 SG_ VCFRONT_a228_RPMTarget m228 : 26|10@1+ (10,0) [0|10000] "RPM"  gtw
 SG_ VCFRONT_a146_RPMTarget m146 : 26|10@1+ (10,0) [0|10000] "RPM"  gtw
 SG_ VCFRONT_a142_isCoilShortXNGnd m142 : 26|1@1+ (1,0) [0|1] ""  gtw
 SG_ VCFRONT_a188_IBSCurrent m188 : 26|14@1- (0.005,0) [-40.96|40.955] "A"  gtw
 SG_ VCFRONT_a152_RPMTarget m152 : 26|10@1+ (10,0) [0|10000] "RPM"  gtw
 SG_ VCFRONT_a230_RPMTarget m230 : 26|10@1+ (10,0) [0|10000] "RPM"  gtw
 SG_ VCFRONT_a229_RPMTarget m229 : 26|10@1+ (10,0) [0|10000] "RPM"  gtw
 SG_ VCFRONT_a160_faultValveEvapSol m160 : 26|1@1+ (1,0) [0|1] ""  gtw
 SG_ VCFRONT_a196_batterySMState m196 : 26|3@1+ (1,0) [0|7] ""  gtw
 SG_ VCFRONT_a021_Task1000msStarved m21 : 26|1@1+ (1,0) [0|1] ""  gtw
 SG_ VCFRONT_a255_RPMTarget m255 : 26|10@1+ (10,0) [0|10000] "RPM"  gtw
 SG_ VCFRONT_a254_RPMTarget m254 : 26|10@1+ (10,0) [0|10000] "RPM"  gtw
 SG_ VCFRONT_a150_RPMTarget m150 : 26|10@1+ (10,0) [0|10000] "RPM"  gtw
 SG_ VCFRONT_a249_tempCoolantPTInlet m249 : 26|11@1+ (0.125,-40) [-40|200] "degC"  gtw
 SG_ VCFRONT_a117_VEH_intrusionSensor m117 : 25|1@1+ (1,0) [0|1] ""  gtw
 SG_ VCFRONT_a160_faultValveEXV m160 : 25|1@1+ (1,0) [0|1] ""  gtw
 SG_ VCFRONT_a021_Task1000msLate m21 : 25|1@1+ (1,0) [0|1] ""  gtw
 SG_ VCFRONT_a116_VEH_restraintStatus m116 : 25|1@1+ (1,0) [0|1] ""  gtw
 SG_ VCFRONT_a142_isCoilShortXPVbb m142 : 25|1@1+ (1,0) [0|1] ""  gtw
 SG_ VCFRONT_a187_partyBusRetryCount m187 : 25|9@1+ (1,0) [0|511] ""  gtw
 SG_ VCFRONT_a021_Task100msMissed m21 : 24|1@1+ (1,0) [0|1] ""  gtw
 SG_ VCFRONT_a142_isCoilShortXPGnd m142 : 24|1@1+ (1,0) [0|1] ""  gtw
 SG_ VCFRONT_a196_vehiclePowerState m196 : 24|2@1+ (1,0) [0|3] ""  gtw
 SG_ VCFRONT_a120_VEH_speed m120 : 24|1@1+ (1,0) [0|1] ""  gtw
 SG_ VCFRONT_a113_VEH_powertrainContr m113 : 24|1@1+ (1,0) [0|1] ""  gtw
 SG_ VCFRONT_a041_CPULoad1msTask m41 : 24|8@1+ (1,0) [0|255] ""  gtw
 SG_ VCFRONT_a042_Usage10msTask m42 : 24|8@1+ (1,0) [0|255] ""  gtw
 SG_ VCFRONT_a116_VEH_seatHeatStatus m116 : 24|1@1+ (1,0) [0|1] ""  gtw
 SG_ VCFRONT_a117_VEH_switchStatus m117 : 24|1@1+ (1,0) [0|1] ""  gtw
 SG_ VCFRONT_a118_VEH_systemStatus m118 : 24|1@1+ (1,0) [0|1] ""  gtw
 SG_ VCFRONT_a022_TaskInitError0 m22 : 24|8@1+ (1,0) [0|255] ""  gtw
 SG_ VCFRONT_a063_switchType m63 : 24|8@1+ (1,0) [0|255] ""  gtw
 SG_ VCFRONT_a160_faultSnsAmbientTemp m160 : 24|1@1+ (1,0) [0|1] ""  gtw
 SG_ VCFRONT_a283_thmlFanDemandLimit m283 : 24|7@1+ (1,0) [0|100] "%"  gtw
 SG_ VCFRONT_a182_ambientTemp m182 : 24|8@1+ (0.5,-40) [-40|80] "degC"  gtw
 SG_ VCFRONT_a118_VEH_12VBattStatus m118 : 23|1@1+ (1,0) [0|1] ""  gtw
 SG_ VCFRONT_a160_faultSnsSuctTemp m160 : 23|1@1+ (1,0) [0|1] ""  gtw
 SG_ VCFRONT_a113_VEH_chassisControl m113 : 23|1@1+ (1,0) [0|1] ""  gtw
 SG_ VCFRONT_a021_Task100msStarved m21 : 23|1@1+ (1,0) [0|1] ""  gtw
 SG_ VCFRONT_a117_VEH_doorStatus m117 : 23|1@1+ (1,0) [0|1] ""  gtw
 SG_ VCFRONT_a142_isCoilOpenY m142 : 23|1@1+ (1,0) [0|1] ""  gtw
 SG_ VCFRONT_a120_PARTY_speed m120 : 23|1@1+ (1,0) [0|1] ""  gtw
 SG_ VCFRONT_a116_VEH_doorStatus m116 : 23|1@1+ (1,0) [0|1] ""  gtw
 SG_ VCFRONT_a117_VEH_seatStatus m117 : 22|1@1+ (1,0) [0|1] ""  gtw
 SG_ VCFRONT_a120_VEH_status m120 : 22|1@1+ (1,0) [0|1] ""  gtw
 SG_ VCFRONT_a021_Task100msLate m21 : 22|1@1+ (1,0) [0|1] ""  gtw
 SG_ VCFRONT_a113_VEH_ventCntlReq m113 : 22|1@1+ (1,0) [0|1] ""  gtw
 SG_ VCFRONT_a142_isCoilOpenX m142 : 22|1@1+ (1,0) [0|1] ""  gtw
 SG_ VCFRONT_a116_VEH_thsStatus m116 : 22|1@1+ (1,0) [0|1] ""  gtw
 SG_ VCFRONT_a182_transportMode m182 : 22|1@1+ (1,0) [0|1] ""  gtw
 SG_ VCFRONT_a160_faultSnsSuctPress m160 : 22|1@1+ (1,0) [0|1] ""  gtw
 SG_ VCFRONT_a118_VEH_vehicleStatus m118 : 22|1@1+ (1,0) [0|1] ""  gtw
 SG_ VCFRONT_a021_Task10msMissed m21 : 21|1@1+ (1,0) [0|1] ""  gtw
 SG_ VCFRONT_a012_ExternalReset m12 : 21|1@1+ (1,0) [0|1] ""  gtw
 SG_ VCFRONT_a142_driverThermShutdown m142 : 21|1@1+ (1,0) [0|1] ""  gtw
 SG_ VCFRONT_a015_NVMMWriteFailed m15 : 21|1@1+ (1,0) [0|1] ""  gtw
 SG_ VCFRONT_a113_VEH_solarData m113 : 21|1@1+ (1,0) [0|1] ""  gtw
 SG_ VCFRONT_a118_VEH_LVPowerState m118 : 21|1@1+ (1,0) [0|1] ""  gtw
 SG_ VCFRONT_a120_PARTY_locStatus m120 : 21|1@1+ (1,0) [0|1] ""  gtw
 SG_ VCFRONT_a182_serviceMode m182 : 21|1@1+ (1,0) [0|1] ""  gtw
 SG_ VCFRONT_a116_VEH_seatStatus m116 : 21|1@1+ (1,0) [0|1] ""  gtw
 SG_ VCFRONT_a161_underTemperature m161 : 21|1@1+ (1,0) [0|1] ""  gtw
 SG_ VCFRONT_a160_faultSnsDischTemp m160 : 21|1@1+ (1,0) [0|1] ""  gtw
 SG_ VCFRONT_a117_VEH_lightStatus m117 : 21|1@1+ (1,0) [0|1] ""  gtw
 SG_ VCFRONT_a124_vccUnderVoltage m124 : 20|1@1+ (1,0) [0|1] ""  gtw
 SG_ VCFRONT_a239_watchdogTimeout m239 : 20|1@1+ (1,0) [0|1] ""  gtw
 SG_ VCFRONT_a015_NVMMMemOverflow m15 : 20|1@1+ (1,0) [0|1] ""  gtw
 SG_ VCFRONT_a238_watchdogTimeout m238 : 20|1@1+ (1,0) [0|1] ""  gtw
 SG_ VCFRONT_a021_Task10msStarved m21 : 20|1@1+ (1,0) [0|1] ""  gtw
 SG_ VCFRONT_a107_VEH_bmbMinMax m107 : 20|1@1+ (1,0) [0|1] ""  gtw
 SG_ VCFRONT_a160_faultSnsDischPress m160 : 20|1@1+ (1,0) [0|1] ""  gtw
 SG_ VCFRONT_a126_vccUnderVoltage m126 : 20|1@1+ (1,0) [0|1] ""  gtw
 SG_ VCFRONT_a182_factoryMode m182 : 20|1@1+ (1,0) [0|1] ""  gtw
 SG_ VCFRONT_a118_VEH_okToUseHighPwr m118 : 20|1@1+ (1,0) [0|1] ""  gtw
 SG_ VCFRONT_a145_thOverTemperature m145 : 20|1@1+ (1,0) [0|1] ""  gtw
 SG_ VCFRONT_a142_driverThermWarn m142 : 20|1@1+ (1,0) [0|1] ""  gtw
 SG_ VCFRONT_a122_vccUnderVoltage m122 : 20|1@1+ (1,0) [0|1] ""  gtw
 SG_ VCFRONT_a237_watchdogTimeout m237 : 20|1@1+ (1,0) [0|1] ""  gtw
 SG_ VCFRONT_a143_thOverTemperature m143 : 20|1@1+ (1,0) [0|1] ""  gtw
 SG_ VCFRONT_a116_VEH_lightStatus m116 : 20|1@1+ (1,0) [0|1] ""  gtw
 SG_ VCFRONT_a161_shortCircuit m161 : 20|1@1+ (1,0) [0|1] ""  gtw
 SG_ VCFRONT_a012_DebugReset m12 : 20|1@1+ (1,0) [0|1] ""  gtw
 SG_ VCFRONT_a120_VEH_torque m120 : 20|1@1+ (1,0) [0|1] ""  gtw
 SG_ VCFRONT_a144_thOverTemperature m144 : 20|1@1+ (1,0) [0|1] ""  gtw
 SG_ VCFRONT_a117_VEH_restraintStatus m117 : 20|1@1+ (1,0) [0|1] ""  gtw
 SG_ VCFRONT_a113_VEH_vehicleControl2 m113 : 20|1@1+ (1,0) [0|1] ""  gtw
 SG_ VCFRONT_a196_frunkLatchStatus m196 : 19|4@1+ (1,0) [0|8] ""  gtw
 SG_ VCFRONT_a136_snsRateChangeDown m136 : 19|1@1+ (1,0) [0|1] ""  gtw
 SG_ VCFRONT_a139_snsRateChangeDown m139 : 19|1@1+ (1,0) [0|1] ""  gtw
 SG_ VCFRONT_a137_snsRateChangeDown m137 : 19|1@1+ (1,0) [0|1] ""  gtw
 SG_ VCFRONT_a015_NVMMRecordUpgraded m15 : 19|1@1+ (1,0) [0|1] ""  gtw
 SG_ VCFRONT_a021_Task10msLate m21 : 19|1@1+ (1,0) [0|1] ""  gtw
 SG_ VCFRONT_a012_CheckstopReset m12 : 19|1@1+ (1,0) [0|1] ""  gtw
 SG_ VCFRONT_a116_VEH_LVPowerState m116 : 19|1@1+ (1,0) [0|1] ""  gtw
 SG_ VCFRONT_a114_PARTY_party3 m114 : 19|1@1+ (1,0) [0|1] ""  gtw
 SG_ VCFRONT_a239_pwmOutputFault m239 : 19|1@1+ (1,0) [0|1] ""  gtw
 SG_ VCFRONT_a109_PARTY_collision m109 : 19|1@1+ (1,0) [0|1] ""  gtw
 SG_ VCFRONT_a161_overTemperature m161 : 19|1@1+ (1,0) [0|1] ""  gtw
 SG_ VCFRONT_a141_snsRateChangeDown m141 : 19|1@1+ (1,0) [0|1] ""  gtw
 SG_ VCFRONT_a126_lossOfSpeedLock m126 : 19|1@1+ (1,0) [0|1] ""  gtw
 SG_ VCFRONT_a175_snsRateChangeDown m175 : 19|1@1+ (1,0) [0|1] ""  gtw
 SG_ VCFRONT_a104_PARTY_control m104 : 19|1@1+ (1,0) [0|1] ""  gtw
 SG_ VCFRONT_a238_pwmOutputFault m238 : 19|1@1+ (1,0) [0|1] ""  gtw
 SG_ VCFRONT_a144_vglUnderVoltage m144 : 19|1@1+ (1,0) [0|1] ""  gtw
 SG_ VCFRONT_a140_snsRateChangeDown m140 : 19|1@1+ (1,0) [0|1] ""  gtw
 SG_ VCFRONT_a107_VEH_thermalStatus m107 : 19|1@1+ (1,0) [0|1] ""  gtw
 SG_ VCFRONT_a118_VEH_status m118 : 19|1@1+ (1,0) [0|1] ""  gtw
 SG_ VCFRONT_a108_PARTY_torque m108 : 19|1@1+ (1,0) [0|1] ""  gtw
 SG_ VCFRONT_a113_VEH_vehicleControl m113 : 19|1@1+ (1,0) [0|1] ""  gtw
 SG_ VCFRONT_a122_lossOfSpeedLock m122 : 19|1@1+ (1,0) [0|1] ""  gtw
 SG_ VCFRONT_a145_vglUnderVoltage m145 : 19|1@1+ (1,0) [0|1] ""  gtw
 SG_ VCFRONT_a160_lowSuctionPressure m160 : 19|1@1+ (1,0) [0|1] ""  gtw
 SG_ VCFRONT_a138_snsRateChangeDown m138 : 19|1@1+ (1,0) [0|1] ""  gtw
 SG_ VCFRONT_a182_12VFloorReached m182 : 19|1@1+ (1,0) [0|1] ""  gtw
 SG_ VCFRONT_a120_PARTY_torque m120 : 19|1@1+ (1,0) [0|1] ""  gtw
 SG_ VCFRONT_a124_lossOfSpeedLock m124 : 19|1@1+ (1,0) [0|1] ""  gtw
 SG_ VCFRONT_a237_pwmOutputFault m237 : 19|1@1+ (1,0) [0|1] ""  gtw
 SG_ VCFRONT_a143_vglUnderVoltage m143 : 19|1@1+ (1,0) [0|1] ""  gtw
 SG_ VCFRONT_a117_VEH_LVPowerState m117 : 19|1@1+ (1,0) [0|1] ""  gtw
 SG_ VCFRONT_a113_VEH_chargeRequest m113 : 18|1@1+ (1,0) [0|1] ""  gtw
 SG_ VCFRONT_a175_snsRateChangeUp m175 : 18|1@1+ (1,0) [0|1] ""  gtw
 SG_ VCFRONT_a021_Task1msMissed m21 : 18|1@1+ (1,0) [0|1] ""  gtw
 SG_ VCFRONT_a141_snsRateChangeUp m141 : 18|1@1+ (1,0) [0|1] ""  gtw
 SG_ VCFRONT_a120_PARTY_systemStatus m120 : 18|1@1+ (1,0) [0|1] ""  gtw
 SG_ VCFRONT_a199_lockoutState m199 : 18|1@1+ (1,0) [0|1] ""  gtw
 SG_ VCFRONT_a196_transportMode m196 : 18|1@1+ (1,0) [0|1] ""  gtw
 SG_ VCFRONT_a123_lockedRotor m123 : 18|1@1+ (1,0) [0|1] ""  gtw
 SG_ VCFRONT_a104_VEH_thermalStatus m104 : 18|1@1+ (1,0) [0|1] ""  gtw
 SG_ VCFRONT_a125_lockedRotor m125 : 18|1@1+ (1,0) [0|1] ""  gtw
 SG_ VCFRONT_a144_chpUnderVoltage m144 : 18|1@1+ (1,0) [0|1] ""  gtw
 SG_ VCFRONT_a124_startUpOperation m124 : 18|1@1+ (1,0) [0|1] ""  gtw
 SG_ VCFRONT_a143_chpUnderVoltage m143 : 18|1@1+ (1,0) [0|1] ""  gtw
 SG_ VCFRONT_a198_lockoutState m198 : 18|1@1+ (1,0) [0|1] ""  gtw
 SG_ VCFRONT_a210_valveNoTravel m210 : 18|1@1+ (1,0) [0|1] ""  gtw
 SG_ VCFRONT_a137_snsRateChangeUp m137 : 18|1@1+ (1,0) [0|1] ""  gtw
 SG_ VCFRONT_a103_VEH_status m103 : 18|1@1+ (1,0) [0|1] ""  gtw
 SG_ VCFRONT_a012_SoftwareReset m12 : 18|1@1+ (1,0) [0|1] ""  gtw
 SG_ VCFRONT_a122_startUpOperation m122 : 18|1@1+ (1,0) [0|1] ""  gtw
 SG_ VCFRONT_a145_chpUnderVoltage m145 : 18|1@1+ (1,0) [0|1] ""  gtw
 SG_ VCFRONT_a161_overCurrent m161 : 18|1@1+ (1,0) [0|1] ""  gtw
 SG_ VCFRONT_a239_spiDiagError m239 : 18|1@1+ (1,0) [0|1] ""  gtw
 SG_ VCFRONT_a110_VEH_time m110 : 18|1@1+ (1,0) [0|1] ""  gtw
 SG_ VCFRONT_a139_snsRateChangeUp m139 : 18|1@1+ (1,0) [0|1] ""  gtw
 SG_ VCFRONT_a106_VEH_thermalStatus m106 : 18|1@1+ (1,0) [0|1] ""  gtw
 SG_ VCFRONT_a119_VEH_rightStalk m119 : 18|1@1+ (1,0) [0|1] ""  gtw
 SG_ VCFRONT_a121_lockedRotor m121 : 18|1@1+ (1,0) [0|1] ""  gtw
 SG_ VCFRONT_a136_snsRateChangeUp m136 : 18|1@1+ (1,0) [0|1] ""  gtw
 SG_ VCFRONT_a117_VEH_hvacBlowerFdb m117 : 18|1@1+ (1,0) [0|1] ""  gtw
 SG_ VCFRONT_a107_VEH_status m107 : 18|1@1+ (1,0) [0|1] ""  gtw
 SG_ VCFRONT_a102_VEH_sensorStatus m102 : 18|1@1+ (1,0) [0|1] ""  gtw
 SG_ VCFRONT_a108_VEH_torque m108 : 18|1@1+ (1,0) [0|1] ""  gtw
 SG_ VCFRONT_a126_startUpOperation m126 : 18|1@1+ (1,0) [0|1] ""  gtw
 SG_ VCFRONT_a138_snsRateChangeUp m138 : 18|1@1+ (1,0) [0|1] ""  gtw
 SG_ VCFRONT_a238_spiDiagError m238 : 18|1@1+ (1,0) [0|1] ""  gtw
 SG_ VCFRONT_a114_VEH_wheelSpeeds m114 : 18|1@1+ (1,0) [0|1] ""  gtw
 SG_ VCFRONT_a237_spiDiagError m237 : 18|1@1+ (1,0) [0|1] ""  gtw
 SG_ VCFRONT_a182_overcharge m182 : 18|1@1+ (1,0) [0|1] ""  gtw
 SG_ VCFRONT_a116_VEH_hvacRequest m116 : 18|1@1+ (1,0) [0|1] ""  gtw
 SG_ VCFRONT_a140_snsRateChangeUp m140 : 18|1@1+ (1,0) [0|1] ""  gtw
 SG_ VCFRONT_a015_NVMMVersionMismatch m15 : 18|1@1+ (1,0) [0|1] ""  gtw
 SG_ VCFRONT_a109_PARTY_nearDeploy m109 : 18|1@1+ (1,0) [0|1] ""  gtw
 SG_ VCFRONT_a160_highDischPressure m160 : 18|1@1+ (1,0) [0|1] ""  gtw
 SG_ VCFRONT_a118_VEH_sensors m118 : 18|1@1+ (1,0) [0|1] ""  gtw
 SG_ VCFRONT_a121_fetShortCircuit m121 : 17|1@1+ (1,0) [0|1] ""  gtw
 SG_ VCFRONT_a138_snsDisconnect m138 : 17|1@1+ (1,0) [0|1] ""  gtw
 SG_ VCFRONT_a161_HVOverVoltage m161 : 17|1@1+ (1,0) [0|1] ""  gtw
 SG_ VCFRONT_a160_lowDischPressure m160 : 17|1@1+ (1,0) [0|1] ""  gtw
 SG_ VCFRONT_a117_VEH_vehNm m117 : 17|1@1+ (1,0) [0|1] ""  gtw
 SG_ VCFRONT_a137_snsDisconnect m137 : 17|1@1+ (1,0) [0|1] ""  gtw
 SG_ VCFRONT_a124_junctionOverTemp m124 : 17|1@1+ (1,0) [0|1] ""  gtw
 SG_ VCFRONT_a110_VEH_carConfig m110 : 17|1@1+ (1,0) [0|1] ""  gtw
 SG_ VCFRONT_a238_spiRegisterMismatch m238 : 17|1@1+ (1,0) [0|1] ""  gtw
 SG_ VCFRONT_a170_rightECU m170 : 17|1@1+ (1,0) [0|1] ""  gtw
 SG_ VCFRONT_a139_snsDisconnect m139 : 17|1@1+ (1,0) [0|1] ""  gtw
 SG_ VCFRONT_a169_rightECU m169 : 17|1@1+ (1,0) [0|1] ""  gtw
 SG_ VCFRONT_a097_VEH_state m97 : 17|1@1+ (1,0) [0|1] ""  gtw
 SG_ VCFRONT_a105_VEH_chNm m105 : 17|1@1+ (1,0) [0|1] ""  gtw
 SG_ VCFRONT_a010_UnderVoltageTimeout m10 : 17|1@1+ (1,0) [0|1] ""  gtw
 SG_ VCFRONT_a106_VEH_thermalControl m106 : 17|1@1+ (1,0) [0|1] ""  gtw
 SG_ VCFRONT_a239_spiRegisterMismatch m239 : 17|1@1+ (1,0) [0|1] ""  gtw
 SG_ VCFRONT_a021_Task1msStarved m21 : 17|1@1+ (1,0) [0|1] ""  gtw
 SG_ VCFRONT_a102_VEH_feedbackStatus m102 : 17|1@1+ (1,0) [0|1] ""  gtw
 SG_ VCFRONT_a107_VEH_vehNm m107 : 17|1@1+ (1,0) [0|1] ""  gtw
 SG_ VCFRONT_a114_PARTY_wheelSpeeds m114 : 17|1@1+ (1,0) [0|1] ""  gtw
 SG_ VCFRONT_a113_VEH_hvacRequest m113 : 17|1@1+ (1,0) [0|1] ""  gtw
 SG_ VCFRONT_a141_snsDisconnect m141 : 17|1@1+ (1,0) [0|1] ""  gtw
 SG_ VCFRONT_a098_VEH_temperature m98 : 17|1@1+ (1,0) [0|1] ""  gtw
 SG_ VCFRONT_a198_NVRAMState m198 : 17|1@1+ (1,0) [0|1] ""  gtw
 SG_ VCFRONT_a013_ClearQueueFull m13 : 17|1@1+ (1,0) [0|1] ""  gtw
 SG_ VCFRONT_a115_VEH_authentication m115 : 17|1@1+ (1,0) [0|1] ""  gtw
 SG_ VCFRONT_a126_junctionOverTemp m126 : 17|1@1+ (1,0) [0|1] ""  gtw
 SG_ VCFRONT_a002_PowerOnReset m2 : 17|1@1+ (1,0) [0|1] ""  gtw
 SG_ VCFRONT_a168_rightECU m168 : 17|1@1+ (1,0) [0|1] ""  gtw
 SG_ VCFRONT_a182_lowCapacity m182 : 17|1@1+ (1,0) [0|1] ""  gtw
 SG_ VCFRONT_a109_PARTY_inertial2 m109 : 17|1@1+ (1,0) [0|1] ""  gtw
 SG_ VCFRONT_a140_snsDisconnect m140 : 17|1@1+ (1,0) [0|1] ""  gtw
 SG_ VCFRONT_a012_FlashError m12 : 17|1@1+ (1,0) [0|1] ""  gtw
 SG_ VCFRONT_a103_VEH_vehNm m103 : 17|1@1+ (1,0) [0|1] ""  gtw
 SG_ VCFRONT_a120_VEH_systemStatus m120 : 17|1@1+ (1,0) [0|1] ""  gtw
 SG_ VCFRONT_a123_fetShortCircuit m123 : 17|1@1+ (1,0) [0|1] ""  gtw
 SG_ VCFRONT_a122_junctionOverTemp m122 : 17|1@1+ (1,0) [0|1] ""  gtw
 SG_ VCFRONT_a104_VEH_bodyControls m104 : 17|1@1+ (1,0) [0|1] ""  gtw
 SG_ VCFRONT_a210_valveOverTravel m210 : 17|1@1+ (1,0) [0|1] ""  gtw
 SG_ VCFRONT_a175_snsDisconnect m175 : 17|1@1+ (1,0) [0|1] ""  gtw
 SG_ VCFRONT_a144_vsOverVoltage m144 : 17|1@1+ (1,0) [0|1] ""  gtw
 SG_ VCFRONT_a125_fetShortCircuit m125 : 17|1@1+ (1,0) [0|1] ""  gtw
 SG_ VCFRONT_a196_serviceMode m196 : 17|1@1+ (1,0) [0|1] ""  gtw
 SG_ VCFRONT_a199_NVRAMState m199 : 17|1@1+ (1,0) [0|1] ""  gtw
 SG_ VCFRONT_a100_PARTY m100 : 17|1@1+ (1,0) [0|1] ""  gtw
 SG_ VCFRONT_a119_VEH_leftStalk m119 : 17|1@1+ (1,0) [0|1] ""  gtw
 SG_ VCFRONT_a143_vsOverVoltage m143 : 17|1@1+ (1,0) [0|1] ""  gtw
 SG_ VCFRONT_a118_VEH_lighting m118 : 17|1@1+ (1,0) [0|1] ""  gtw
 SG_ VCFRONT_a112_VEH_status m112 : 17|1@1+ (1,0) [0|1] ""  gtw
 SG_ VCFRONT_a060_resetUnlocked m60 : 17|1@1+ (1,0) [0|1] ""  gtw
 SG_ VCFRONT_a136_snsDisconnect m136 : 17|1@1+ (1,0) [0|1] ""  gtw
 SG_ VCFRONT_a015_NVMMCRCMismatch m15 : 17|1@1+ (1,0) [0|1] ""  gtw
 SG_ VCFRONT_a159_angleActual m159 : 17|10@1+ (0.25,-70) [-70|180] "deg"  gtw
 SG_ VCFRONT_a116_VEH_vehNm m116 : 17|1@1+ (1,0) [0|1] ""  gtw
 SG_ VCFRONT_a111_VEH_status m111 : 17|1@1+ (1,0) [0|1] ""  gtw
 SG_ VCFRONT_a108_VEH_thermalControl m108 : 17|1@1+ (1,0) [0|1] ""  gtw
 SG_ VCFRONT_a237_spiRegisterMismatch m237 : 17|1@1+ (1,0) [0|1] ""  gtw
 SG_ VCFRONT_a145_vsOverVoltage m145 : 17|1@1+ (1,0) [0|1] ""  gtw
 SG_ VCFRONT_a139_snsShortCircuit m139 : 16|1@1+ (1,0) [0|1] ""  gtw
 SG_ VCFRONT_a063_switchChannel m63 : 16|8@1+ (1,0) [0|255] ""  gtw
 SG_ VCFRONT_a262_eFuseVoltage m262 : 16|16@1+ (0.1,0) [0|6553.5] "V"  gtw
 SG_ VCFRONT_a317_maxSlope m317 : 16|11@1+ (0.125,-40) [-40|150] "C/s"  gtw
 SG_ VCFRONT_a003_AssertID m3 : 16|16@1+ (1,0) [0|65535] ""  gtw
 SG_ VCFRONT_a105_VEH_states m105 : 16|1@1+ (1,0) [0|1] ""  gtw
 SG_ VCFRONT_a335_maxSlope m335 : 16|12@1+ (0.1,0) [0|409.5] "A/ms"  gtw
 SG_ VCFRONT_a164_lockoutVoltage m164 : 16|16@1+ (0.1,0) [0|6553.5] "V"  gtw
 SG_ VCFRONT_a118_VEH_vehNm m118 : 16|1@1+ (1,0) [0|1] ""  gtw
 SG_ VCFRONT_a233_current m233 : 16|10@1+ (0.1,0) [0|102.3] "A"  gtw
 SG_ VCFRONT_a204_epas3sSelfTest m204 : 16|4@1+ (1,0) [0|11] ""  gtw
 SG_ VCFRONT_a265_eFuseVoltage m265 : 16|16@1+ (0.1,0) [0|6553.5] "V"  gtw
 SG_ VCFRONT_a099_VEH_oocStatus m99 : 16|1@1+ (1,0) [0|1] ""  gtw
 SG_ VCFRONT_a127_vcleftEFuseCurrent m127 : 16|16@1+ (0.1,0) [0|6553.5] "A"  gtw
 SG_ VCFRONT_a060_lockoutDisabled m60 : 16|1@1+ (1,0) [0|1] ""  gtw
 SG_ VCFRONT_a064_busBitField m64 : 16|8@1+ (1,0) [0|255] ""  gtw
 SG_ VCFRONT_a310_maxSlope m310 : 16|11@1+ (0.125,-40) [-40|150] "C/s"  gtw
 SG_ VCFRONT_a136_snsShortCircuit m136 : 16|1@1+ (1,0) [0|1] ""  gtw
 SG_ VCFRONT_a255_RPMActual m255 : 16|10@1+ (10,0) [0|10000] "RPM"  gtw
 SG_ VCFRONT_a110_VEH_carState m110 : 16|1@1+ (1,0) [0|1] ""  gtw
 SG_ VCFRONT_a129_pcsEFuseCurrent m129 : 16|16@1+ (0.1,0) [0|6553.5] "A"  gtw
 SG_ VCFRONT_a211_DeviceIDBits m211 : 16|8@1+ (1,0) [0|255] ""  gtw
 SG_ VCFRONT_a012_ClockError m12 : 16|1@1+ (1,0) [0|1] ""  gtw
 SG_ VCFRONT_a142_driverState m142 : 16|4@1+ (1,0) [0|11] ""  gtw
 SG_ VCFRONT_a200_vcleftSelfTest m200 : 16|4@1+ (1,0) [0|11] ""  gtw
 SG_ VCFRONT_a183_minVoltageReached m183 : 16|12@1+ (0.005443676098,0) [0|22.29185] "V"  gtw
 SG_ VCFRONT_a268_eFuseVoltage m268 : 16|16@1+ (0.1,0) [0|6553.5] "V"  gtw
 SG_ VCFRONT_a260_IBSVolts m260 : 16|12@1+ (0.005443676098,0) [0|22.29185] "V"  gtw
 SG_ VCFRONT_a340_maxSlope m340 : 16|12@1+ (0.1,0) [0|409.5] "A/ms"  gtw
 SG_ VCFRONT_a133_espEFuseCurrent m133 : 16|16@1+ (0.1,0) [0|6553.5] "A"  gtw
 SG_ VCFRONT_a214_airCompCurrent m214 : 16|16@1+ (0.005,0) [0|327.675] "A"  gtw
 SG_ VCFRONT_a325_maxSlope m325 : 16|11@1+ (0.125,-40) [-40|150] "C/s"  gtw
 SG_ VCFRONT_a138_snsShortCircuit m138 : 16|1@1+ (1,0) [0|1] ""  gtw
 SG_ VCFRONT_a212_IBSTemp m212 : 16|16@1- (0.01,0) [-327.68|327.67] "degC"  gtw
 SG_ VCFRONT_a021_Task1msLate m21 : 16|1@1+ (1,0) [0|1] ""  gtw
 SG_ VCFRONT_a126_junctionTempWarning m126 : 16|1@1+ (1,0) [0|1] ""  gtw
 SG_ VCFRONT_a186_noDriveChgCableConX m186 : 16|1@1+ (1,0) [0|1] ""  gtw
 SG_ VCFRONT_a343_maxSlope m343 : 16|12@1+ (0.1,0) [0|409.5] "A/ms"  gtw
 SG_ VCFRONT_a247_evapSolenoidISense m247 : 16|8@1- (0.01,0) [-1.28|1.27] "A"  gtw
 SG_ VCFRONT_a109_PARTY_status m109 : 16|1@1+ (1,0) [0|1] ""  gtw
 SG_ VCFRONT_a113_VEH_ethNm m113 : 16|1@1+ (1,0) [0|1] ""  gtw
 SG_ VCFRONT_a198_outputState m198 : 16|1@1+ (1,0) [0|1] ""  gtw
 SG_ VCFRONT_a346_maxSlope m346 : 16|12@1+ (0.1,0) [0|409.5] "A/ms"  gtw
 SG_ VCFRONT_a339_maxSlope m339 : 16|12@1+ (0.1,0) [0|409.5] "A/ms"  gtw
 SG_ VCFRONT_a117_PARTY_epbmStatus m117 : 16|1@1+ (1,0) [0|1] ""  gtw
 SG_ VCFRONT_a103_VEH_hvsNm m103 : 16|1@1+ (1,0) [0|1] ""  gtw
 SG_ VCFRONT_a328_avgCurrent m328 : 16|16@1+ (0.1,0) [0|6553.5] "A"  gtw
 SG_ VCFRONT_a219_IBSVolts m219 : 16|12@1+ (0.005443676098,0) [0|22.29185] "V"  gtw
 SG_ VCFRONT_a230_RPMActual m230 : 16|10@1+ (10,0) [0|10000] "RPM"  gtw
 SG_ VCFRONT_a134_fusedHighCurrent m134 : 16|16@1+ (0.1,0) [0|6553.5] "A"  gtw
 SG_ VCFRONT_a097_VEH_HVStatus m97 : 16|1@1+ (1,0) [0|1] ""  gtw
 SG_ VCFRONT_a229_RPMActual m229 : 16|10@1+ (10,0) [0|10000] "RPM"  gtw
 SG_ VCFRONT_a331_avgCurrent m331 : 16|16@1+ (0.1,0) [0|6553.5] "A"  gtw
 SG_ VCFRONT_a320_maxSlope m320 : 16|11@1+ (0.125,-40) [-40|150] "C/s"  gtw
 SG_ VCFRONT_a195_IBSVoltage m195 : 16|12@1+ (0.005443676098,0) [0|22.29185] "V"  gtw
 SG_ VCFRONT_a207_vbatFusedSelfTest m207 : 16|4@1+ (1,0) [0|11] ""  gtw
 SG_ VCFRONT_a041_CPULoadTotal m41 : 16|8@1+ (1,0) [0|255] ""  gtw
 SG_ VCFRONT_a349_maxSlope m349 : 16|12@1+ (0.1,0) [0|409.5] "A/ms"  gtw
 SG_ VCFRONT_a336_maxSlope m336 : 16|12@1+ (0.1,0) [0|409.5] "A/ms"  gtw
 SG_ VCFRONT_a106_VEH_dcdcStatus m106 : 16|1@1+ (1,0) [0|1] ""  gtw
 SG_ VCFRONT_a176_vehicleState m176 : 16|5@1+ (1,0) [0|17] ""  gtw
 SG_ VCFRONT_a261_eFuseVoltage m261 : 16|16@1+ (0.1,0) [0|6553.5] "V"  gtw
 SG_ VCFRONT_a120_PARTY_chassisCntl m120 : 16|1@1+ (1,0) [0|1] ""  gtw
 SG_ VCFRONT_a152_RPMActual m152 : 16|10@1+ (10,0) [0|10000] "RPM"  gtw
 SG_ VCFRONT_a145_vsUnderVoltage m145 : 16|1@1+ (1,0) [0|1] ""  gtw
 SG_ VCFRONT_a123_overCurrentError m123 : 16|1@1+ (1,0) [0|1] ""  gtw
 SG_ VCFRONT_a237_spiErrorCount m237 : 16|1@1+ (1,0) [0|1] ""  gtw
 SG_ VCFRONT_a314_maxSlope m314 : 16|11@1+ (0.125,-40) [-40|150] "C/s"  gtw
 SG_ VCFRONT_a327_avgCurrent m327 : 16|16@1+ (0.1,0) [0|6553.5] "A"  gtw
 SG_ VCFRONT_a146_RPMActual m146 : 16|10@1+ (10,0) [0|10000] "RPM"  gtw
 SG_ VCFRONT_a311_maxSlope m311 : 16|11@1+ (0.125,-40) [-40|150] "C/s"  gtw
 SG_ VCFRONT_a202_pcsSelfTest m202 : 16|4@1+ (1,0) [0|11] ""  gtw
 SG_ VCFRONT_a249_tempCoolantBatInlet m249 : 16|10@1+ (0.125,-40) [-40|85] "degC"  gtw
 SG_ VCFRONT_a030_logId m30 : 16|4@1+ (1,0) [0|15] ""  gtw
 SG_ VCFRONT_a213_IBSVolts m213 : 16|12@1+ (0.005443676098,0) [0|22.29185] "V"  gtw
 SG_ VCFRONT_a245_current m245 : 16|16@1+ (0.1,0) [0|6553.5] "A"  gtw
 SG_ VCFRONT_a100_VEH m100 : 16|1@1+ (1,0) [0|1] ""  gtw
 SG_ VCFRONT_a259_minVoltageReached m259 : 16|12@1+ (0.005443676098,0) [0|22.29185] "V"  gtw
 SG_ VCFRONT_a236_batSensorTemp m236 : 16|11@1+ (0.125,-40) [-40|200] "degC"  gtw
 SG_ VCFRONT_a173_ECUMismatch m173 : 16|1@1+ (1,0) [0|1] ""  gtw
 SG_ VCFRONT_a235_ptSensorTemp m235 : 16|11@1+ (0.125,-40) [-40|200] "degC"  gtw
 SG_ VCFRONT_a182_dead12V m182 : 16|1@1+ (1,0) [0|1] ""  gtw
 SG_ VCFRONT_a264_eFuseVoltage m264 : 16|16@1+ (0.1,0) [0|6553.5] "V"  gtw
 SG_ VCFRONT_a140_snsShortCircuit m140 : 16|1@1+ (1,0) [0|1] ""  gtw
 SG_ VCFRONT_a115_VEH_vehNm m115 : 16|1@1+ (1,0) [0|1] ""  gtw
 SG_ VCFRONT_a199_outputState m199 : 16|1@1+ (1,0) [0|1] ""  gtw
 SG_ VCFRONT_a108_VEH_temperature m108 : 16|1@1+ (1,0) [0|1] ""  gtw
 SG_ VCFRONT_a231_12VTemperature m231 : 16|16@1- (0.1,0) [-3276.8|3276.7] "C"  gtw
 SG_ VCFRONT_a228_RPMActual m228 : 16|10@1+ (10,0) [0|10000] "RPM"  gtw
 SG_ VCFRONT_a312_maxSlope m312 : 16|11@1+ (0.125,-40) [-40|150] "C/s"  gtw
 SG_ VCFRONT_a143_vsUnderVoltage m143 : 16|1@1+ (1,0) [0|1] ""  gtw
 SG_ VCFRONT_a125_overCurrentError m125 : 16|1@1+ (1,0) [0|1] ""  gtw
 SG_ VCFRONT_a267_eFuseVoltage m267 : 16|16@1+ (0.1,0) [0|6553.5] "V"  gtw
 SG_ VCFRONT_a234_current m234 : 16|10@1+ (0.1,0) [0|102.3] "A"  gtw
 SG_ VCFRONT_a107_VEH_hvsNm m107 : 16|1@1+ (1,0) [0|1] ""  gtw
 SG_ VCFRONT_a013_LogQueueFull m13 : 16|1@1+ (1,0) [0|1] ""  gtw
 SG_ VCFRONT_a324_maxSlope m324 : 16|11@1+ (0.125,-40) [-40|150] "C/s"  gtw
 SG_ VCFRONT_a022_TaskInitErrorCount m22 : 16|8@1+ (1,0) [0|255] ""  gtw
 SG_ VCFRONT_a201_vcrightSelfTest m201 : 16|4@1+ (1,0) [0|11] ""  gtw
 SG_ VCFRONT_a148_RPMActual m148 : 16|10@1+ (10,0) [0|10000] "RPM"  gtw
 SG_ VCFRONT_a179_highLVAmpsIntoPCSLo m179 : 16|1@1+ (1,0) [0|1] ""  gtw
 SG_ VCFRONT_a043_CallTrace0 m43 : 16|24@1+ (1,0) [0|16777215] ""  gtw
 SG_ VCFRONT_a151_RPMActual m151 : 16|10@1+ (10,0) [0|10000] "RPM"  gtw
 SG_ VCFRONT_a248_IBSVoltage m248 : 16|12@1+ (0.005443676098,0) [0|22.29185] "V"  gtw
 SG_ VCFRONT_a342_maxSlope m342 : 16|12@1+ (0.1,0) [0|409.5] "A/ms"  gtw
 SG_ VCFRONT_a175_snsShortCircuit m175 : 16|1@1+ (1,0) [0|1] ""  gtw
 SG_ VCFRONT_a172_ECUMismatch m172 : 16|1@1+ (1,0) [0|1] ""  gtw
 SG_ VCFRONT_a044_CallTrace0 m44 : 16|24@1+ (1,0) [0|16777215] ""  gtw
 SG_ VCFRONT_a302_LINFrameStatus m302 : 16|3@1+ (1,0) [0|4] ""  gtw
 SG_ VCFRONT_a101_VEH_state m101 : 16|1@1+ (1,0) [0|1] ""  gtw
 SG_ VCFRONT_a244_current m244 : 16|16@1+ (0.1,0) [0|6553.5] "A"  gtw
 SG_ VCFRONT_a345_maxSlope m345 : 16|12@1+ (0.1,0) [0|409.5] "A/ms"  gtw
 SG_ VCFRONT_a001_InternalWatchdog m1 : 16|1@1+ (1,0) [0|1] ""  gtw
 SG_ VCFRONT_a159_stall m159 : 16|1@1+ (1,0) [0|1] ""  gtw
 SG_ VCFRONT_a258_minVoltageReached m258 : 16|12@1+ (0.005443676098,0) [0|22.29185] "V"  gtw
 SG_ VCFRONT_a323_maxSlope m323 : 16|11@1+ (0.125,-40) [-40|150] "C/s"  gtw
 SG_ VCFRONT_a147_RPMActual m147 : 16|10@1+ (10,0) [0|10000] "RPM"  gtw
 SG_ VCFRONT_a210_valveUnderTravel m210 : 16|1@1+ (1,0) [0|1] ""  gtw
 SG_ VCFRONT_a332_avgCurrent m332 : 16|16@1+ (0.1,0) [0|6553.5] "A"  gtw
 SG_ VCFRONT_a318_maxSlope m318 : 16|11@1+ (0.125,-40) [-40|150] "C/s"  gtw
 SG_ VCFRONT_a141_snsShortCircuit m141 : 16|1@1+ (1,0) [0|1] ""  gtw
 SG_ VCFRONT_a169_leftECU m169 : 16|1@1+ (1,0) [0|1] ""  gtw
 SG_ VCFRONT_a205_iBoosterSelfTest m205 : 16|4@1+ (1,0) [0|11] ""  gtw
 SG_ VCFRONT_a111_VEH_internalStatus m111 : 16|1@1+ (1,0) [0|1] ""  gtw
 SG_ VCFRONT_a315_maxSlope m315 : 16|11@1+ (0.125,-40) [-40|150] "C/s"  gtw
 SG_ VCFRONT_a326_avgCurrent m326 : 16|16@1+ (0.1,0) [0|6553.5] "A"  gtw
 SG_ VCFRONT_a102_VEH_faults m102 : 16|1@1+ (1,0) [0|1] ""  gtw
 SG_ VCFRONT_a170_leftECU m170 : 16|1@1+ (1,0) [0|1] ""  gtw
 SG_ VCFRONT_a002_CPUUndervoltage m2 : 16|1@1+ (1,0) [0|1] ""  gtw
 SG_ VCFRONT_a348_maxSlope m348 : 16|12@1+ (0.1,0) [0|409.5] "A/ms"  gtw
 SG_ VCFRONT_a337_maxSlope m337 : 16|12@1+ (0.1,0) [0|409.5] "A/ms"  gtw
 SG_ VCFRONT_a144_vsUnderVoltage m144 : 16|1@1+ (1,0) [0|1] ""  gtw
 SG_ VCFRONT_a177_mcuAudioCurrent m177 : 16|10@1+ (0.1,0) [0|102.3] "A"  gtw
 SG_ VCFRONT_a263_eFuseVoltage m263 : 16|16@1+ (0.1,0) [0|6553.5] "V"  gtw
 SG_ VCFRONT_a150_RPMActual m150 : 16|10@1+ (10,0) [0|10000] "RPM"  gtw
 SG_ VCFRONT_a121_overCurrentError m121 : 16|1@1+ (1,0) [0|1] ""  gtw
 SG_ VCFRONT_a334_maxSlope m334 : 16|12@1+ (0.1,0) [0|409.5] "A/ms"  gtw
 SG_ VCFRONT_a165_lockoutVoltage m165 : 16|16@1+ (0.1,0) [0|6553.5] "V"  gtw
 SG_ VCFRONT_a161_failedStart m161 : 16|1@1+ (1,0) [0|1] ""  gtw
 SG_ VCFRONT_a010_UnderVoltageDetecte m10 : 16|1@1+ (1,0) [0|1] ""  gtw
 SG_ VCFRONT_a316_maxSlope m316 : 16|11@1+ (0.125,-40) [-40|150] "C/s"  gtw
 SG_ VCFRONT_a188_sleepBypassCurrent m188 : 16|10@1+ (0.1,0) [0|102.3] "A"  gtw
 SG_ VCFRONT_a112_VEH_internalStatus m112 : 16|1@1+ (1,0) [0|1] ""  gtw
 SG_ VCFRONT_a253_IBSCurrent m253 : 16|16@1- (0.005,0) [-163.84|163.835] "A"  gtw
 SG_ VCFRONT_a131_epas3sEFuseCurrent m131 : 16|16@1+ (0.1,0) [0|6553.5] "A"  gtw
 SG_ VCFRONT_a238_spiErrorCount m238 : 16|1@1+ (1,0) [0|1] ""  gtw
 SG_ VCFRONT_a160_highDischTemp m160 : 16|1@1+ (1,0) [0|1] ""  gtw
 SG_ VCFRONT_a266_eFuseVoltage m266 : 16|16@1+ (0.1,0) [0|6553.5] "V"  gtw
 SG_ VCFRONT_a171_ECUMismatch m171 : 16|1@1+ (1,0) [0|1] ""  gtw
 SG_ VCFRONT_a157_motorCounts m157 : 16|11@1+ (1,-100) [-100|1900] "ticks"  gtw
 SG_ VCFRONT_a251_UIKeepAwake m251 : 16|4@1+ (1,0) [0|15] ""  gtw
 SG_ VCFRONT_a313_maxSlope m313 : 16|11@1+ (0.125,-40) [-40|150] "C/s"  gtw
 SG_ VCFRONT_a206_espSelfTest m206 : 16|4@1+ (1,0) [0|11] ""  gtw
 SG_ VCFRONT_a128_vcrightEFuseCurrent m128 : 16|16@1+ (0.1,0) [0|6553.5] "A"  gtw
 SG_ VCFRONT_a203_epas3pSelfTest m203 : 16|4@1+ (1,0) [0|11] ""  gtw
 SG_ VCFRONT_a341_maxSlope m341 : 16|12@1+ (0.1,0) [0|409.5] "A/ms"  gtw
 SG_ VCFRONT_a257_lockoutVoltage m257 : 16|16@1+ (0.1,0) [0|6553.5] "V"  gtw
 SG_ VCFRONT_a243_IBSVolts m243 : 16|12@1+ (0.005443676098,0) [0|22.29185] "V"  gtw
 SG_ VCFRONT_a168_leftECU m168 : 16|1@1+ (1,0) [0|1] ""  gtw
 SG_ VCFRONT_a059_voltageDrop m59 : 16|12@1+ (0.005443676098,0) [0|22.29185] "V"  gtw
 SG_ VCFRONT_a124_junctionTempWarning m124 : 16|1@1+ (1,0) [0|1] ""  gtw
 SG_ VCFRONT_a130_epas3pEFuseCurrent m130 : 16|16@1+ (0.1,0) [0|6553.5] "A"  gtw
 SG_ VCFRONT_a252_IBSVoltage m252 : 16|12@1+ (0.005443676098,0) [0|22.29185] "V"  gtw
 SG_ VCFRONT_a254_RPMActual m254 : 16|10@1+ (10,0) [0|10000] "RPM"  gtw
 SG_ VCFRONT_a137_snsShortCircuit m137 : 16|1@1+ (1,0) [0|1] ""  gtw
 SG_ VCFRONT_a333_avgCurrent m333 : 16|16@1+ (0.1,0) [0|6553.5] "A"  gtw
 SG_ VCFRONT_a322_maxSlope m322 : 16|11@1+ (0.125,-40) [-40|150] "C/s"  gtw
 SG_ VCFRONT_a187_vehBusRetryCount m187 : 16|9@1+ (1,0) [0|511] ""  gtw
 SG_ VCFRONT_a174_driveNotAuthedData m174 : 16|1@1+ (1,0) [0|1] ""  gtw
 SG_ VCFRONT_a132_iBoosterCurrent m132 : 16|16@1+ (0.1,0) [0|6553.5] "A"  gtw
 SG_ VCFRONT_a015_NVMMRecordNotFound m15 : 16|1@1+ (1,0) [0|1] ""  gtw
 SG_ VCFRONT_a319_maxSlope m319 : 16|11@1+ (0.125,-40) [-40|150] "C/s"  gtw
 SG_ VCFRONT_a344_maxSlope m344 : 16|12@1+ (0.1,0) [0|409.5] "A/ms"  gtw
 SG_ VCFRONT_a283_thmlFanDemand m283 : 16|7@1+ (1,0) [0|100] "%"  gtw
 SG_ VCFRONT_a045_CallTrace0 m45 : 16|24@1+ (1,0) [0|16777215] ""  gtw
 SG_ VCFRONT_a223_12VTemperature m223 : 16|16@1- (0.1,0) [-3276.8|3276.7] "C"  gtw
 SG_ VCFRONT_a114_PARTY_status m114 : 16|1@1+ (1,0) [0|1] ""  gtw
 SG_ VCFRONT_a046_CallTrace0 m46 : 16|24@1+ (1,0) [0|16777215] ""  gtw
 SG_ VCFRONT_a119_VEH_steerAngle m119 : 16|1@1+ (1,0) [0|1] ""  gtw
 SG_ VCFRONT_a122_junctionTempWarning m122 : 16|1@1+ (1,0) [0|1] ""  gtw
 SG_ VCFRONT_a246_current m246 : 16|16@1+ (0.1,0) [0|6553.5] "A"  gtw
 SG_ VCFRONT_a329_avgCurrent m329 : 16|16@1+ (0.1,0) [0|6553.5] "A"  gtw
 SG_ VCFRONT_a196_factoryMode m196 : 16|1@1+ (1,0) [0|1] ""  gtw
 SG_ VCFRONT_a042_Usage1msTask m42 : 16|8@1+ (1,0) [0|255] ""  gtw
 SG_ VCFRONT_a098_VEH_thermalControl m98 : 16|1@1+ (1,0) [0|1] ""  gtw
 SG_ VCFRONT_a116_PARTY_epbmStatus m116 : 16|1@1+ (1,0) [0|1] ""  gtw
 SG_ VCFRONT_a104_VEH_chNm m104 : 16|1@1+ (1,0) [0|1] ""  gtw
 SG_ VCFRONT_a239_spiErrorCount m239 : 16|1@1+ (1,0) [0|1] ""  gtw
 SG_ VCFRONT_a215_airCompDriverPWM m215 : 16|16@1+ (0.005,0) [0|327.675] "%"  gtw
 SG_ VCFRONT_a180_PCSNotSupport12VBat m180 : 16|1@1+ (1,0) [0|1] ""  gtw
 SG_ VCFRONT_a347_maxSlope m347 : 16|12@1+ (0.1,0) [0|409.5] "A/ms"  gtw
 SG_ VCFRONT_a338_maxSlope m338 : 16|12@1+ (0.1,0) [0|409.5] "A/ms"  gtw
 SG_ VCFRONT_a330_avgCurrent m330 : 16|16@1+ (0.1,0) [0|6553.5] "A"  gtw
 SG_ VCFRONT_a000_alertDataW0 m0 : 16|16@1+ (1,0) [0|65535] ""  X
 SG_ VCFRONT_a321_maxSlope m321 : 16|11@1+ (0.125,-40) [-40|150] "C/s"  gtw
 SG_ VCFRONT_a156_motorCounts m156 : 16|11@1+ (1,-100) [-100|1900] "ticks"  gtw
 SG_ VCFRONT_alertType : 15|1@1+ (1,0) [0|1] ""  gtw
 SG_ VCFRONT_alertID M : 0|9@1+ (1,0) [0|349] ""  gtw

BO_ 2023 CMP_EOLTest: 8 VEH
 SG_ CMP_EOLData : 0|64@1+ (1,0) [0|18446744073709551615] ""  cmp

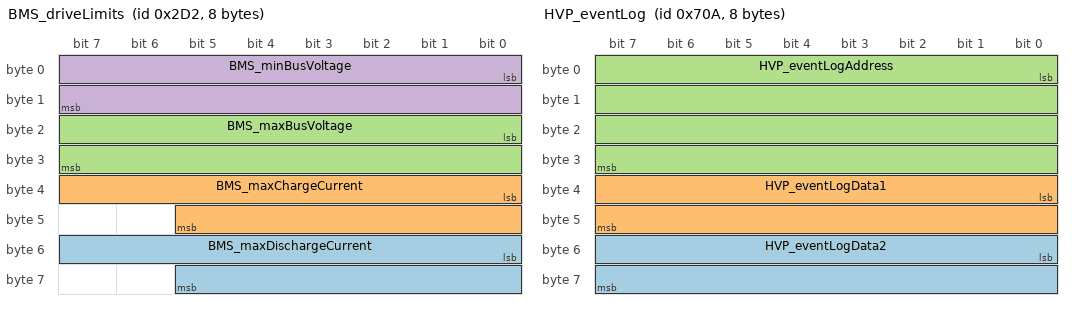
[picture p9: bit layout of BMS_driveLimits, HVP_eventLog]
BO_ 722 BMS_driveLimits: 8 VEH
 SG_ BMS_maxDischargeCurrent : 48|14@1+ (0.128,0) [0|2096.896] "A"  di
 SG_ BMS_maxChargeCurrent : 32|14@1+ (0.1,0) [0|1638.2] "A"  di
 SG_ BMS_maxBusVoltage : 16|16@1+ (0.01,0) [0|430] "V"  di
 SG_ BMS_minBusVoltage : 0|16@1+ (0.01,0) [0|430] "V"  di

BO_ 1802 HVP_eventLog: 8 VEH
 SG_ HVP_eventLogData2 : 48|16@1+ (1,0) [0|65535] ""  gtw
 SG_ HVP_eventLogData1 : 32|16@1+ (1,0) [0|65535] ""  gtw
 SG_ HVP_eventLogAddress : 0|32@1+ (1,0) [0|4294967295] ""  dbg

BO_ 2021 DIS_dlogData: 8 VEH
 SG_ DIS_dlogData : 0|64@1+ (1,0) [0|18446744073709551615] ""  dbg

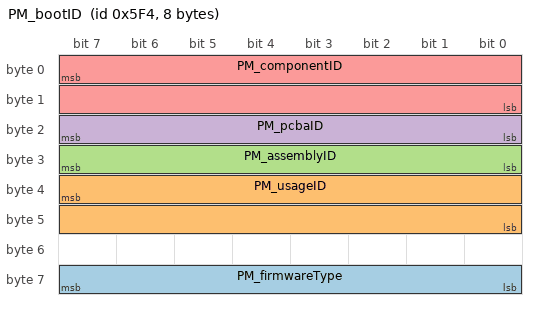
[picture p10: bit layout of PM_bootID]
BO_ 1524 PM_bootID: 8 VEH
 SG_ PM_firmwareType : 63|8@0+ (1,0) [0|255] ""  gtwu
 SG_ PM_usageID : 39|16@0+ (1,0) [0|65535] ""  gtwu
 SG_ PM_assemblyID : 31|8@0+ (1,0) [0|255] ""  gtwu
 SG_ PM_pcbaID : 23|8@0+ (1,0) [0|255] ""  gtwu
 SG_ PM_componentID : 7|16@0+ (1,0) [0|65535] ""  gtwu

BO_ 2047 GTW_carConfig: 8 VEH
 SG_ GTW_eCallEnabled m2 : 63|1@1+ (1,0) [0|1] ""  X
 SG_ GTW_trackModePackage m2 : 62|1@1+ (1,0) [0|1] ""  X
 SG_ GTW_roofGlassType m2 : 61|1@1+ (1,0) [0|1] ""  X
 SG_ GTW_restraintsHardwareType m2 : 56|5@1+ (1,0) [21|23] ""  X
 SG_ GTW_brakeHWType m2 : 55|1@1+ (1,0) [0|1] ""  di
 SG_ GTW_pedestrianWarningSound m2 : 54|1@1+ (1,0) [0|1] ""  X
 SG_ GTW_numberHVILNodes m2 : 51|3@1+ (1,0) [0|5] ""  bms
 SG_ GTW_exteriorColor m2 : 48|3@1+ (1,0) [0|6] ""  X
 SG_ GTW_wheelType m2 : 46|2@1+ (1,0) [0|3] ""  X
 SG_ GTW_superchargingAccess m2 : 44|2@1+ (1,0) [0|2] ""  bms
 SG_ GTW_autopilot m2 : 42|2@1+ (1,0) [0|3] ""  das
 SG_ GTW_dasHw m1 : 40|3@1+ (1,0) [3|4] ""  X
 SG_ GTW_roofType m2 : 40|2@1+ (1,0) [0|2] ""  X
 SG_ GTW_rearFogLamps m2 : 39|1@1+ (1,0) [0|1] ""  vcright
 SG_ GTW_rearGlassType m2 : 38|1@1+ (1,0) [0|1] ""  X
 SG_ GTW_spoilerType m2 : 37|1@1+ (1,0) [0|1] ""  X
 SG_ GTW_intrusionSensorType m2 : 36|1@1+ (1,0) [0|1] ""  vcfront
 SG_ GTW_airbagCutoffSwitch m2 : 35|1@1+ (1,0) [0|1] ""  X
 SG_ GTW_activeHighBeam m2 : 34|1@1+ (1,0) [0|1] ""  vcfront
 SG_ GTW_windshieldType m2 : 33|1@1+ (1,0) [0|1] ""  X
 SG_ GTW_tireType m1 : 32|3@1+ (1,0) [0|5] ""  X
 SG_ GTW_eBuckConfig m2 : 32|1@1+ (1,0) [0|1] ""  X
 SG_ GTW_performancePackage m2 : 31|1@1+ (1,0) [0|1] ""  di
 SG_ GTW_CabinBlowerCtrlType m2 : 30|1@1+ (1,0) [0|1] ""  X
 SG_ GTW_hvacPanelVaneType m2 : 29|1@1+ (1,0) [0|1] ""  vcright
 SG_ GTW_hvacQuietSnorkelType m2 : 28|1@1+ (1,0) [0|1] ""  vcright
 SG_ GTW_auxParkLamps m2 : 26|2@1+ (1,0) [0|2] ""  vcfront
 SG_ GTW_frontSeatType m2 : 25|1@1+ (1,0) [0|1] ""  vcleft
 SG_ GTW_ibstWakeType m2 : 24|1@1+ (1,0) [0|1] ""  vcfront
 SG_ GTW_lumbarECUType m2 : 23|1@1+ (1,0) [0|1] ""  X
 SG_ GTW_audioType m2 : 22|1@1+ (1,0) [0|1] ""  X
 SG_ GTW_headlamps m2 : 21|1@1+ (1,0) [0|1] ""  X
 SG_ GTW_frontFogLamps m2 : 20|1@1+ (1,0) [0|1] ""  vcfront
 SG_ GTW_interiorLighting m2 : 19|1@1+ (1,0) [0|1] ""  X
 SG_ GTW_powerSteeringColumn m2 : 18|1@1+ (1,0) [0|1] ""  X
 SG_ GTW_memoryMirrors m2 : 17|1@1+ (1,0) [0|1] ""  das
 SG_ GTW_country m1 : 16|16@1+ (1,0) [0|65535] ""  das
 SG_ GTW_rearLightType m3 : 16|1@1+ (1,0) [0|1] ""  X
 SG_ GTW_xcpESP m2 : 16|1@1+ (1,0) [0|1] ""  X
 SG_ GTW_xcpIbst m2 : 15|1@1+ (1,0) [0|1] ""  X
 SG_ GTW_vdcType m2 : 14|1@1+ (1,0) [0|1] ""  di
 SG_ GTW_homelinkType m2 : 13|1@1+ (1,0) [0|1] ""  X
 SG_ GTW_rightHandDrive m1 : 11|1@1+ (1,0) [0|1] ""  das
 SG_ GTW_packEnergy m2 : 11|2@1+ (1,0) [0|2] ""  bms
 SG_ GTW_rearSeatHeaters m2 : 10|1@1+ (1,0) [0|1] ""  vcleft
 SG_ GTW_drivetrainType m1 : 10|1@1+ (1,0) [0|1] ""  bms
 SG_ GTW_epasType m1 : 9|1@1+ (1,0) [0|0] ""  das
 SG_ GTW_frontSeatHeaters m2 : 9|1@1+ (1,0) [0|1] ""  vcleft
 SG_ GTW_mapRegion m3 : 8|4@1+ (1,0) [0|8] ""  X
 SG_ GTW_heatedWipers m2 : 8|1@1+ (1,0) [0|1] ""  X
 SG_ GTW_airSuspension m1 : 8|1@1+ (1,0) [0|1] ""  das
 SG_ GTW_carConfigMultiplexer M : 0|8@1+ (1,0) [0|255] ""  X

BA_DEF_ SG_  "SystemSignalLongSymbol" STRING ;
BA_DEF_DEF_  "SystemSignalLongSymbol" "";
BA_ "SystemSignalLongSymbol" SG_ 832 VCFRONT_a236_batTempSnsIrrationa "VCFRONT_a236_batTempSnsIrrational";
BA_ "SystemSignalLongSymbol" SG_ 832 VCFRONT_a234_autopilot2EFuseFaul "VCFRONT_a234_autopilot2EFuseFault";
BA_ "SystemSignalLongSymbol" SG_ 832 VCFRONT_a233_autopilot1EFuseFaul "VCFRONT_a233_autopilot1EFuseFault";
BA_ "SystemSignalLongSymbol" SG_ 832 VCFRONT_a349_vbatFusedFastTripSl "VCFRONT_a349_vbatFusedFastTripSlope";
BA_ "SystemSignalLongSymbol" SG_ 832 VCFRONT_a347_iboosterFastTripSlo "VCFRONT_a347_iboosterFastTripSlope";
BA_ "SystemSignalLongSymbol" SG_ 832 VCFRONT_a226_railAPoweredForFrun "VCFRONT_a226_railAPoweredForFrunk";
BA_ "SystemSignalLongSymbol" SG_ 832 VCFRONT_a225_driveBlckdByShowroo "VCFRONT_a225_driveBlckdByShowroom";
BA_ "SystemSignalLongSymbol" SG_ 832 VCFRONT_a283_thmlFanLimitedByCur "VCFRONT_a283_thmlFanLimitedByCurrent";
BA_ "SystemSignalLongSymbol" SG_ 832 VCFRONT_a343_vcrightFastTripSlop "VCFRONT_a343_vcrightFastTripSlope";
BA_ "SystemSignalLongSymbol" SG_ 832 VCFRONT_a341_vbatFusedFastTripOC "VCFRONT_a341_vbatFusedFastTripOCMax";
BA_ "SystemSignalLongSymbol" SG_ 832 VCFRONT_a339_iboosterFastTripOCM "VCFRONT_a339_iboosterFastTripOCMax";
BA_ "SystemSignalLongSymbol" SG_ 832 VCFRONT_a335_vcrightFastTripOCMa "VCFRONT_a335_vcrightFastTripOCMax";
BA_ "SystemSignalLongSymbol" SG_ 832 VCFRONT_a268_vbatFusedVoltageMis "VCFRONT_a268_vbatFusedVoltageMismatch";
BA_ "SystemSignalLongSymbol" SG_ 832 VCFRONT_a267_EPAS3sVoltageMismat "VCFRONT_a267_EPAS3sVoltageMismatch";
BA_ "SystemSignalLongSymbol" SG_ 832 VCFRONT_a207_vbatFusdSelfTestFai "VCFRONT_a207_vbatFusdSelfTestFail";
BA_ "SystemSignalLongSymbol" SG_ 832 VCFRONT_a266_EPAS3pVoltageMismat "VCFRONT_a266_EPAS3pVoltageMismatch";
BA_ "SystemSignalLongSymbol" SG_ 832 VCFRONT_a205_iBoosterSelfTestFai "VCFRONT_a205_iBoosterSelfTestFail";
BA_ "SystemSignalLongSymbol" SG_ 832 VCFRONT_a325_vbatFusedOvertempMa "VCFRONT_a325_vbatFusedOvertempMax";
BA_ "SystemSignalLongSymbol" SG_ 832 VCFRONT_a264_iBoosterVoltageMism "VCFRONT_a264_iBoosterVoltageMismatch";
BA_ "SystemSignalLongSymbol" SG_ 832 VCFRONT_a262_vcrightVoltageMisma "VCFRONT_a262_vcrightVoltageMismatch";
BA_ "SystemSignalLongSymbol" SG_ 832 VCFRONT_a261_vcleftVoltageMismat "VCFRONT_a261_vcleftVoltageMismatch";
BA_ "SystemSignalLongSymbol" SG_ 832 VCFRONT_a259_12vVoltageDropOnHig "VCFRONT_a259_12vVoltageDropOnHighLoadCurrent";
BA_ "SystemSignalLongSymbol" SG_ 832 VCFRONT_a258_resistanceEstimatio "VCFRONT_a258_resistanceEstimationRun";
BA_ "SystemSignalLongSymbol" SG_ 832 VCFRONT_a317_vbatFusedOvertempSl "VCFRONT_a317_vbatFusedOvertempSlope";
BA_ "SystemSignalLongSymbol" SG_ 832 VCFRONT_a315_iboosterOvertempSlo "VCFRONT_a315_iboosterOvertempSlope";
BA_ "SystemSignalLongSymbol" SG_ 832 VCFRONT_a195_drveBlckdVltgeTooHg "VCFRONT_a195_drveBlckdVltgeTooHgh";
BA_ "SystemSignalLongSymbol" SG_ 832 VCFRONT_a253_maxChrgeSssionTmeou "VCFRONT_a253_maxChrgeSssionTmeout";
BA_ "SystemSignalLongSymbol" SG_ 832 VCFRONT_a252_frontControllerWake "VCFRONT_a252_frontControllerWakeup";
BA_ "SystemSignalLongSymbol" SG_ 832 VCFRONT_a311_vcrightOvertempSlop "VCFRONT_a311_vcrightOvertempSlope";
BA_ "SystemSignalLongSymbol" SG_ 832 VCFRONT_a301_wipersFactoryDisabl "VCFRONT_a301_wipersFactoryDisabled";
BA_ "SystemSignalLongSymbol" SG_ 1294 CP_a072_VCFRONT_tempAmbientFilte "CP_a072_VCFRONT_tempAmbientFiltered";
BA_ "SystemSignalLongSymbol" SG_ 1294 CP_a073_VCFRONT_tempAmbientFilte "CP_a073_VCFRONT_tempAmbientFiltered";
BA_ "SystemSignalLongSymbol" SG_ 1332 VCFRONT_a260_notEnoughPowerForSu "VCFRONT_a260_notEnoughPowerForSupport";
BA_ "SystemSignalLongSymbol" SG_ 1332 VCFRONT_a257_vcrightLockoutStatu "VCFRONT_a257_vcrightLockoutStatus";
BA_ "SystemSignalLongSymbol" SG_ 1332 VCFRONT_a117_VEH_intrusionSensor "VCFRONT_a117_VEH_intrusionSensorStatus";
BA_ "SystemSignalLongSymbol" SG_ 1332 VCFRONT_a113_VEH_powertrainContr "VCFRONT_a113_VEH_powertrainControl";
BA_ "SystemSignalLongSymbol" SG_ 1332 VCFRONT_a179_highLVAmpsIntoPCSLo "VCFRONT_a179_highLVAmpsIntoPCSLog";
BA_ "SystemSignalLongSymbol" SG_ 1332 VCFRONT_a010_UnderVoltageDetecte "VCFRONT_a010_UnderVoltageDetected";
VAL_ 832 VCFRONT_matrixIndex 2 "VCFRONT_AlertMatrix2" 4 "VCFRONT_AlertMatrix4" 3 "VCFRONT_AlertMatrix3" 5 "VCFRONT_AlertMatrix5" 0 "VCFRONT_AlertMatrix0" 1 "VCFRONT_AlertMatrix1" ;
VAL_ 755 UI_hvacReqSecondRowState 2 "LOW" 0 "AUTO" 3 "MED" 1 "OFF" 4 "HIGH" ;
VAL_ 755 UI_hvacReqUserPowerState 2 "PRECONDITION" 4 "OVERHEAT_PROTECT" 3 "OVERHEAT_PROTECT_FANONLY" 0 "OFF" 1 "ON" ;
VAL_ 755 UI_hvacReqManualDefogState 0 "NONE" 2 "DEFROST" 1 "DEFOG" ;
VAL_ 755 UI_hvacReqACDisable 0 "AUTO" 1 "OFF" 2 "ON" ;
VAL_ 755 UI_hvacReqRecirc 0 "AUTO" 1 "RECIRC" 2 "FRESH" ;
VAL_ 755 UI_hvacReqBlowerSegment 11 "AUTO" 7 "7" 1 "1" 4 "4" 0 "OFF" 2 "2" 5 "5" 8 "8" 3 "3" 6 "6" 9 "9" 10 "10" ;
VAL_ 755 UI_hvacReqAirDistributionMode 3 "MANUAL_PANEL_FLOOR" 0 "AUTO" 5 "MANUAL_DEFROST_FLOOR" 1 "MANUAL_FLOOR" 4 "MANUAL_DEFROST" 2 "MANUAL_PANEL" 6 "MANUAL_DEFROST_PANEL" 7 "MANUAL_DEFROST_PANEL_FLOOR" ;
VAL_ 755 UI_hvacReqTempSetpointRight 26 "HI" 0 "LO" ;
VAL_ 755 UI_hvacReqTempSetpointLeft 26 "HI" 0 "LO" ;
VAL_ 554 HVP_dcLinkVoltageFiltered -550 "SNA" ;
VAL_ 554 HVP_pcsControlRequest 1 "SUPPORT" 0 "SHUTDOWN" 3 "DISCHARGE" 2 "PRECHARGE" ;
VAL_ 1354 SCS_alertType 0 "ALERT_CLEARED" 1 "ALERT_SET" ;
VAL_ 1354 SCS_alertID 32 "SCS_a032_VBatRationality" 25 "SCS_a025_internalIsolationFault" 55 "SCS_a055_coolantLevelLow" 73 "SCS_a073_lccMIA" 3 "SCS_a003_hwCordOT" 35 "SCS_a035_unexpectedVbusBehavior" 54 "SCS_a054_pumpRegulation" 37 "SCS_a037_outputContactorWelded" 13 "SCS_a013_cordTempHiFoldBk" 82 "SCS_a082_VbatUV" 42 "SCS_a042_pilotOutOfRange" 28 "SCS_a028_isolationRationality" 76 "SCS_a076_bmsMIA" 27 "SCS_a027_externalIsolationLow" 91 "SCS_a091_voltageRiseDetection" 39 "SCS_a039_ibatRegulation" 30 "SCS_a030_VbusOV" 0 "SCS_ALERT_DO_NOT_USE_ZERO" 49 "SCS_a049_pcbaTempRationality" 63 "SCS_a063_canRationality" 58 "SCS_a058_adcRef" 57 "SCS_a057_watchdogReset" 60 "SCS_a060_swHVIL" 67 "SCS_a067_vBatRationalityStage3" 86 "SCS_a086_lccResetDetected" 65 "SCS_a065_vBatRationalityStage1" 7 "SCS_a007_hwWeld_V2" 66 "SCS_a066_vBatRationalityStage2" 94 "SCS_a094_unused94" 98 "SCS_a098_unused98" 85 "SCS_a085_unused85" 14 "SCS_a014_coolantTempHiFoldBk" 96 "SCS_a096_unused96" 36 "SCS_a036_internalContactorWelded" 72 "SCS_a072_gtwMIA" 51 "SCS_a051_cordTempRationality" 74 "SCS_a074_isoVDiffHi" 1 "SCS_a001_hwDSPfault" 87 "SCS_a087_posCordTempRationality" 18 "SCS_a018_unusedHW18" 71 "SCS_a071_chargerMIA" 16 "SCS_a016_unusedHW16" 40 "SCS_a040_plus12VOutOfRange" 21 "SCS_a021_unusedHW21" 8 "SCS_a008_hwOpen_V1" 44 "SCS_a044_proximityRationality" 10 "SCS_a010_hwIllegalCntrCmdV1" 64 "SCS_a064_vehicleCommandTimeout" 59 "SCS_a059_memoryError" 78 "SCS_a078_voltageMatchTimeout" 61 "SCS_a061_postOutOfService" 52 "SCS_a052_ambientTempRationality" 46 "SCS_a046_coolantOT" 92 "SCS_a092_cabEnableDeasserted" 31 "SCS_a031_IbatOC" 62 "SCS_a062_unused" 77 "SCS_a077_unexpectedVbatBehavior" 4 "SCS_a004_hwVbusOV" 70 "SCS_a070_vStageRationalityV2" 12 "SCS_a012_hwIllegalCntrCmdV2" 24 "SCS_a024_emergencyShutdown" 43 "SCS_a043_pilotRationality" 2 "SCS_a002_hwIbatOC" 34 "SCS_a034_IBatRationality" 81 "SCS_a081_rmsInputVoltageHigh" 80 "SCS_a080_lccFaulted" 48 "SCS_a048_ambientOT" 45 "SCS_a045_pcbaOT" 75 "SCS_a075_leakageTestAbsDecayLow" 47 "SCS_a047_cordOT" 79 "SCS_a079_unexpectedVbat" 68 "SCS_a068_vBatRationalityStage4" 38 "SCS_a038_contactorFailedOpen" 9 "SCS_a009_hwOpen_V2" 53 "SCS_a053_unexpectedThermalBehavi" 5 "SCS_a005_hwHVIL" 105 "SCS_a105_unused105" 109 "SCS_a109_unused109" 115 "SCS_a115_unused115" 111 "SCS_a111_unused111" 120 "SCS_a120_unused120" 122 "SCS_a122_unused122" 99 "SCS_a099_unused99" 33 "SCS_a033_VBusRationality" 56 "SCS_a056_stateTransitionDenied" 104 "SCS_a104_unused104" 128 "SCS_a128_unused128" 100 "SCS_a100_unused100" 89 "SCS_a089_posCordOT" 116 "SCS_a116_unused116" 95 "SCS_a095_unused95" 103 "SCS_a103_unused103" 110 "SCS_a110_unused110" 113 "SCS_a113_unused113" 127 "SCS_a127_unused127" 117 "SCS_a117_unused117" 123 "SCS_a123_unused123" 69 "SCS_a069_vStageRationalityV1" 84 "SCS_a084_unused84" 101 "SCS_a101_unused101" 126 "SCS_a126_unused126" 97 "SCS_a097_unused97" 90 "SCS_a090_negCordOT" 41 "SCS_a041_minus12VOutOfRange" 124 "SCS_a124_unused124" 88 "SCS_a088_negCordTempRationality" 125 "SCS_a125_unused125" 121 "SCS_a121_unused121" 119 "SCS_a119_unused119" 83 "SCS_a083_chargeCurrentLimited" 112 "SCS_a112_unused112" 102 "SCS_a102_unused102" 106 "SCS_a106_unused106" 108 "SCS_a108_unused108" 114 "SCS_a114_unused114" 107 "SCS_a107_unused107" 118 "SCS_a118_unused118" 93 "SCS_a093_unused93" 19 "SCS_a019_unusedHW19" 50 "SCS_a050_coolantTempRationality" 6 "SCS_a006_hwWeld_V1" 11 "SCS_a011_hwIllegalCntrCmdInt" 29 "SCS_a029_VbatOV" 15 "SCS_a015_unusedHW15" 26 "SCS_a026_internalIsolationLow" 20 "SCS_a020_unusedHW20" 17 "SCS_a017_unusedHW17" ;
VAL_ 801 VCFRONT_tempAmbientFiltered 0 "SNA" ;
VAL_ 801 VCFRONT_washerFluidLevel 1 "LOW" 0 "SNA" 2 "NORMAL" ;
VAL_ 801 VCFRONT_tempAmbient 0 "SNA" ;
VAL_ 801 VCFRONT_brakeFluidLevel 1 "LOW" 0 "SNA" 2 "NORMAL" ;
VAL_ 801 VCFRONT_coolantLevel 1 "FILLED" 0 "NOT_OK" ;
VAL_ 801 VCFRONT_tempCoolantPTInlet 2047 "SNA" ;
VAL_ 801 VCFRONT_tempCoolantBatInlet 1023 "SNA" ;
VAL_ 835 VCRIGHT_mirrorHeatState 2 "HEATER_STATE_OFF" 4 "HEATER_STATE_FAULT" 1 "HEATER_STATE_ON" 0 "HEATER_STATE_SNA" 3 "HEATER_STATE_OFF_UNAVAILABLE" ;
VAL_ 835 VCRIGHT_rearDefrostState 2 "HEATER_STATE_OFF" 4 "HEATER_STATE_FAULT" 1 "HEATER_STATE_ON" 0 "HEATER_STATE_SNA" 3 "HEATER_STATE_OFF_UNAVAILABLE" ;
VAL_ 835 VCRIGHT_vehiclePowerStateDBG 3 "VEHICLE_POWER_STATE_DRIVE" 1 "VEHICLE_POWER_STATE_CONDITIONING" 2 "VEHICLE_POWER_STATE_ACCESSORY" 0 "VEHICLE_POWER_STATE_OFF" ;
VAL_ 872 GTW_offboardUpdateState 5 "OFFBOARD_UPDATE_LATCH_RESULT" 4 "OFFBOARD_UPDATE_CONFIRM_UPDATE" 0 "OFFBOARD_UPDATE_WAITING_FOR_CONNECTION" 2 "OFFBOARD_UPDATE_PREPARING" 3 "OFFBOARD_UPDATE_RUNNING" 1 "OFFBOARD_UPDATE_WAIT_UPDATE_TRIGGER" ;
VAL_ 872 GTW_offboardUpdateStatus 4 "OFFBOARD_UPDATE_SUCCESS" 5 "OFFBOARD_UPDATE_LOST_DIGITAL_COMMS" 6 "OFFBOARD_UPDATE_NOT_NEEDED" 0 "OFFBOARD_UPDATE_OK" 7 "OFFBOARD_UPDATE_APPTRIPLE_MISMATCH" 2 "OFFBOARD_UPDATE_UNPLUGGED" 3 "OFFBOARD_UPDATE_UDS_FAILED" 1 "OFFBOARD_UPDATE_FILE_OPEN_ERROR" ;
VAL_ 1294 CP_a065_pilotState 6 "CHG_PILOT_UNUSED_6" 3 "CHG_PILOT_FAST_CHARGE" 7 "CHG_PILOT_SNA" 4 "CHG_PILOT_IDLE" 2 "CHG_PILOT_LINE_CHARGE" 0 "CHG_PILOT_NONE" 5 "CHG_PILOT_INVALID" 1 "CHG_PILOT_FAULTED" ;
VAL_ 1294 CP_a071_inductiveDoorState 1 "CP_INDUCTIVE_DOOR_INIT_FROM_CHARGE" 2 "CP_INDUCTIVE_DOOR_INIT_FROM_DRIVE" 3 "CP_INDUCTIVE_DOOR_PRESENT" 5 "CP_INDUCTIVE_DOOR_OFF_DRIVE" 4 "CP_INDUCTIVE_DOOR_NOT_PRESENT" 7 "CP_INDUCTIVE_DOOR_FAULT" 0 "CP_INDUCTIVE_DOOR_INIT" 6 "CP_INDUCTIVE_DOOR_OFF_CHARGE" ;
VAL_ 1294 CP_a054_inletID 3 "CP_INLET_GBDC" 1 "CP_INLET_IEC" 0 "CP_INLET_SAE" 2 "CP_INLET_GBAC" ;
VAL_ 1294 CP_a037_inletID 3 "CP_INLET_GBDC" 1 "CP_INLET_IEC" 0 "CP_INLET_SAE" 2 "CP_INLET_GBAC" ;
VAL_ 1294 CP_a038_inletID 3 "CP_INLET_GBDC" 1 "CP_INLET_IEC" 0 "CP_INLET_SAE" 2 "CP_INLET_GBAC" ;
VAL_ 1294 CP_a036_inletID 3 "CP_INLET_GBDC" 1 "CP_INLET_IEC" 0 "CP_INLET_SAE" 2 "CP_INLET_GBAC" ;
VAL_ 1294 CP_a054_CP_proximity 3 "CHG_PROXIMITY_LATCHED" 0 "CHG_PROXIMITY_SNA" 2 "CHG_PROXIMITY_UNLATCHED" 1 "CHG_PROXIMITY_DISCONNECTED" ;
VAL_ 1294 CP_a066_proximity 3 "CHG_PROXIMITY_LATCHED" 0 "CHG_PROXIMITY_SNA" 2 "CHG_PROXIMITY_UNLATCHED" 1 "CHG_PROXIMITY_DISCONNECTED" ;
VAL_ 1294 CP_a035_inletID 3 "CP_INLET_GBDC" 1 "CP_INLET_IEC" 0 "CP_INLET_SAE" 2 "CP_INLET_GBAC" ;
VAL_ 1294 CP_a054_latchState 1 "CP_LATCH_DISENGAGED" 2 "CP_LATCH_ENGAGED" 0 "CP_LATCH_SNA" 3 "CP_LATCH_BLOCKING" ;
VAL_ 1294 CP_a036_latchState 1 "CP_LATCH_DISENGAGED" 2 "CP_LATCH_ENGAGED" 0 "CP_LATCH_SNA" 3 "CP_LATCH_BLOCKING" ;
VAL_ 1294 CP_a037_latchState 1 "CP_LATCH_DISENGAGED" 2 "CP_LATCH_ENGAGED" 0 "CP_LATCH_SNA" 3 "CP_LATCH_BLOCKING" ;
VAL_ 1294 CP_a038_latchState 1 "CP_LATCH_DISENGAGED" 2 "CP_LATCH_ENGAGED" 0 "CP_LATCH_SNA" 3 "CP_LATCH_BLOCKING" ;
VAL_ 1294 CP_a057_CP_proximity 3 "CHG_PROXIMITY_LATCHED" 0 "CHG_PROXIMITY_SNA" 2 "CHG_PROXIMITY_UNLATCHED" 1 "CHG_PROXIMITY_DISCONNECTED" ;
VAL_ 1294 CP_a058_CP_proximity 3 "CHG_PROXIMITY_LATCHED" 0 "CHG_PROXIMITY_SNA" 2 "CHG_PROXIMITY_UNLATCHED" 1 "CHG_PROXIMITY_DISCONNECTED" ;
VAL_ 1294 CP_a003_canErrorType 3 "CAN_ERROR_NODEBUG" 8 "CAN_ERROR_TWO_MASTERS" 6 "CAN_ERROR_OVERRUN" 4 "CAN_ERROR_RX" 2 "CAN_ERROR_DATA" 7 "CAN_ERROR_RESET_CMD" 5 "CAN_ERROR_TX" 0 "CAN_ERROR_LENGTH" 1 "CAN_ERROR_CHECKSUM" 9 "CAN_ERROR_TWO_SLAVES" ;
VAL_ 1294 CP_a057_latchState 1 "CP_LATCH_DISENGAGED" 2 "CP_LATCH_ENGAGED" 0 "CP_LATCH_SNA" 3 "CP_LATCH_BLOCKING" ;
VAL_ 1294 CP_a058_latchState 1 "CP_LATCH_DISENGAGED" 2 "CP_LATCH_ENGAGED" 0 "CP_LATCH_SNA" 3 "CP_LATCH_BLOCKING" ;
VAL_ 1294 CP_a058_FC_status 0 "FC_STATUS_NOTREADY_SNA" 2 "FC_STATUS_UPDATE_IN_PROGRESS" 1 "FC_STATUS_READY" 15 "FC_STATUS_NODATA" 14 "FC_STATUS_MALFUNCTION" 6 "FC_STATUS_EXT_ISOACTIVE" 3 "FC_STATUS_UNUSED_3" 5 "FC_STATUS_INT_ISOACTIVE" 7 "FC_STATUS_POST_OUT_OF_SERVICE" 13 "FC_STATUS_NOTCOMPATIBLE" 4 "FC_STATUS_WAIT_POST_READY_TO_CHARGE" ;
VAL_ 1294 CP_a057_FC_status 0 "FC_STATUS_NOTREADY_SNA" 2 "FC_STATUS_UPDATE_IN_PROGRESS" 1 "FC_STATUS_READY" 15 "FC_STATUS_NODATA" 14 "FC_STATUS_MALFUNCTION" 6 "FC_STATUS_EXT_ISOACTIVE" 3 "FC_STATUS_UNUSED_3" 5 "FC_STATUS_INT_ISOACTIVE" 7 "FC_STATUS_POST_OUT_OF_SERVICE" 13 "FC_STATUS_NOTCOMPATIBLE" 4 "FC_STATUS_WAIT_POST_READY_TO_CHARGE" ;
VAL_ 1294 CP_a056_CP_proximity 3 "CHG_PROXIMITY_LATCHED" 0 "CHG_PROXIMITY_SNA" 2 "CHG_PROXIMITY_UNLATCHED" 1 "CHG_PROXIMITY_DISCONNECTED" ;
VAL_ 1294 CP_a057_CC_pilot 1 "CC_PILOT_STATE_IDLE" 3 "CC_PILOT_STATE_SNA" 2 "CC_PILOT_STATE_FAULTED" 0 "CC_PILOT_STATE_READY" ;
VAL_ 1294 CP_a058_CC_pilot 1 "CC_PILOT_STATE_IDLE" 3 "CC_PILOT_STATE_SNA" 2 "CC_PILOT_STATE_FAULTED" 0 "CC_PILOT_STATE_READY" ;
VAL_ 1294 CP_a029_CP_proximity 3 "CHG_PROXIMITY_LATCHED" 0 "CHG_PROXIMITY_SNA" 2 "CHG_PROXIMITY_UNLATCHED" 1 "CHG_PROXIMITY_DISCONNECTED" ;
VAL_ 1294 CP_a063_FC_status 0 "FC_STATUS_NOTREADY_SNA" 2 "FC_STATUS_UPDATE_IN_PROGRESS" 1 "FC_STATUS_READY" 15 "FC_STATUS_NODATA" 14 "FC_STATUS_MALFUNCTION" 6 "FC_STATUS_EXT_ISOACTIVE" 3 "FC_STATUS_UNUSED_3" 5 "FC_STATUS_INT_ISOACTIVE" 7 "FC_STATUS_POST_OUT_OF_SERVICE" 13 "FC_STATUS_NOTCOMPATIBLE" 4 "FC_STATUS_WAIT_POST_READY_TO_CHARGE" ;
VAL_ 1294 CP_a035_latchState 1 "CP_LATCH_DISENGAGED" 2 "CP_LATCH_ENGAGED" 0 "CP_LATCH_SNA" 3 "CP_LATCH_BLOCKING" ;
VAL_ 1294 CP_a064_GTW_superchargingAccess 2 "PAY_AS_YOU_GO" 0 "NOT_ALLOWED" 1 "ALLOWED" ;
VAL_ 1294 CP_a072_VCFRONT_tempAmbientFilte 0 "SNA" ;
VAL_ 1294 CP_a029_CP_pilot 6 "CHG_PILOT_UNUSED_6" 3 "CHG_PILOT_FAST_CHARGE" 7 "CHG_PILOT_SNA" 4 "CHG_PILOT_IDLE" 2 "CHG_PILOT_LINE_CHARGE" 0 "CHG_PILOT_NONE" 5 "CHG_PILOT_INVALID" 1 "CHG_PILOT_FAULTED" ;
VAL_ 1294 CP_a052_fcType 1 "FC_TYPE_CHADEMO" 0 "FC_TYPE_SUPERCHARGER" 7 "FC_TYPE_SNA" 6 "FC_TYPE_OTHER" 5 "FC_TYPE_MC_EVSE" 3 "FC_TYPE_CC_EVSE" 2 "FC_TYPE_GB" 4 "FC_TYPE_COMBO" ;
VAL_ 1294 CP_a073_VCFRONT_tempAmbientFilte 0 "SNA" ;
VAL_ 1294 CP_a062_FC_status 0 "FC_STATUS_NOTREADY_SNA" 2 "FC_STATUS_UPDATE_IN_PROGRESS" 1 "FC_STATUS_READY" 15 "FC_STATUS_NODATA" 14 "FC_STATUS_MALFUNCTION" 6 "FC_STATUS_EXT_ISOACTIVE" 3 "FC_STATUS_UNUSED_3" 5 "FC_STATUS_INT_ISOACTIVE" 7 "FC_STATUS_POST_OUT_OF_SERVICE" 13 "FC_STATUS_NOTCOMPATIBLE" 4 "FC_STATUS_WAIT_POST_READY_TO_CHARGE" ;
VAL_ 1294 CP_a050_inletID 3 "CP_INLET_GBDC" 1 "CP_INLET_IEC" 0 "CP_INLET_SAE" 2 "CP_INLET_GBAC" ;
VAL_ 1294 CP_a056_latchState 1 "CP_LATCH_DISENGAGED" 2 "CP_LATCH_ENGAGED" 0 "CP_LATCH_SNA" 3 "CP_LATCH_BLOCKING" ;
VAL_ 1294 CP_a058_CP_pilot 6 "CHG_PILOT_UNUSED_6" 3 "CHG_PILOT_FAST_CHARGE" 7 "CHG_PILOT_SNA" 4 "CHG_PILOT_IDLE" 2 "CHG_PILOT_LINE_CHARGE" 0 "CHG_PILOT_NONE" 5 "CHG_PILOT_INVALID" 1 "CHG_PILOT_FAULTED" ;
VAL_ 1294 CP_a057_CP_pilot 6 "CHG_PILOT_UNUSED_6" 3 "CHG_PILOT_FAST_CHARGE" 7 "CHG_PILOT_SNA" 4 "CHG_PILOT_IDLE" 2 "CHG_PILOT_LINE_CHARGE" 0 "CHG_PILOT_NONE" 5 "CHG_PILOT_INVALID" 1 "CHG_PILOT_FAULTED" ;
VAL_ 1294 CP_alertType 0 "ALERT_CLEARED" 1 "ALERT_SET" ;
VAL_ 1294 CP_alertID 63 "CP_a063_scUpdateInProgress" 62 "CP_a062_scOutOfService" 41 "CP_a041_doorSensorUnplugged" 23 "CP_a023_gbdcSessionFailed" 44 "CP_a044_lostCommsHVP" 60 "CP_a060_lostCommsPCS" 256 "CP_a256_unused" 25 "CP_a025_ledsOC" 17 "CP_a017_fiveVov" 13 "CP_a013_lostCommsGTW" 11 "CP_a011_eeprom" 58 "CP_a058_acChargingBlocked" 61 "CP_a061_uhfReceiverMIA" 16 "CP_a016_apsVuv" 28 "CP_a028_insertEnableMismatch" 73 "CP_a073_cableNotSecuredCold" 22 "CP_a022_zeroVuv" 56 "CP_a056_proxDisconnected" 0 "CP_ALERT_DO_NOT_USE_ZERO" 27 "CP_a027_doorSensorOutOfSpec" 3 "CP_a003_canError" 1 "CP_a001_canRx" 51 "CP_a051_doorInductiveSensorMIA" 65 "CP_a065_selfTestFailed" 45 "CP_a045_lostCommsVCSEC" 68 "CP_a068_doorSensorMismatch" 14 "CP_a014_lostCommsCHG" 52 "CP_a052_evseNotSupported" 10 "CP_a010_pilotRationality" 15 "CP_a015_apsVov" 49 "CP_a049_multipleCablesDetected" 5 "CP_a005_gbdcLiveDisconnect" 20 "CP_a020_threeVuv" 6 "CP_a006_lostCommsBMS" 35 "CP_a035_latchMovement_1" 59 "CP_a059_swcanError" 47 "CP_a047_lostCommsVCFRONT" 64 "CP_a064_superchargingBlocked" 66 "CP_a066_proxLatchedIdlePilot" 57 "CP_a057_evseFaulted" 71 "CP_a071_LDC1612errorWatchdog" 24 "CP_a024_ledsUC" 21 "CP_a021_zeroVov" 39 "CP_a039_latchMovement_2" 54 "CP_a054_cableNotSecured" 33 "CP_a033_spiOpen" 67 "CP_a067_gbdcConnFault" 38 "CP_a038_latchNotBlocking" 50 "CP_a050_latchNotConnected" 37 "CP_a037_latchNotEngaged" 12 "CP_a012_ledDriver" 30 "CP_a030_busOff" 9 "CP_a009_coverOpen" 18 "CP_a018_fiveVuv" 53 "CP_a053_proxLatchedNoPilot" 36 "CP_a036_latchNotDisengaged" 32 "CP_a032_doorOpenExpectedClosed" 4 "CP_a004_proximityRationality" 2 "CP_a002_canTx" 7 "CP_a007_watchdog" 42 "CP_a042_doorAssemblyBroken" 8 "CP_a008_memoryError" 19 "CP_a019_threeVov" 40 "CP_a040_doNotUse" 70 "CP_a070_doorInductiveSensorReset" 26 "CP_a026_networkManagement" 29 "CP_a029_doorClosedProxPilot" 31 "CP_a031_doorClosedCommandedOpen" 55 "CP_a055_chargeStoppedNoPilot" 69 "CP_a069_doorInductiveSensorError" 46 "CP_a046_lostCommsEVSE" 72 "CP_a072_latchNotDisengagedCold" 48 "CP_a048_lostCommsUI" 34 "CP_a034_calibrationIncomplete" 43 "CP_a043_doorPotIrrational" ;
VAL_ 1250 VCLEFT_frontSeatTiltState 1 "SEAT_STATE_MOVING_UP" 2 "SEAT_STATE_MOVING_DOWN" 3 "SEAT_STATE_RECALLING" 0 "SEAT_STATE_STOPPED" 5 "SEAT_STATE_UNDEFINED" 4 "SEAT_STATE_CALIBRATING" ;
VAL_ 1250 VCLEFT_frontSeatTrackState 1 "SEAT_STATE_MOVING_UP" 2 "SEAT_STATE_MOVING_DOWN" 3 "SEAT_STATE_RECALLING" 0 "SEAT_STATE_STOPPED" 5 "SEAT_STATE_UNDEFINED" 4 "SEAT_STATE_CALIBRATING" ;
VAL_ 1250 VCLEFT_frontSeatBackState 1 "SEAT_STATE_MOVING_UP" 2 "SEAT_STATE_MOVING_DOWN" 3 "SEAT_STATE_RECALLING" 0 "SEAT_STATE_STOPPED" 5 "SEAT_STATE_UNDEFINED" 4 "SEAT_STATE_CALIBRATING" ;
VAL_ 1250 VCLEFT_frontSeatLiftState 1 "SEAT_STATE_MOVING_UP" 2 "SEAT_STATE_MOVING_DOWN" 3 "SEAT_STATE_RECALLING" 0 "SEAT_STATE_STOPPED" 5 "SEAT_STATE_UNDEFINED" 4 "SEAT_STATE_CALIBRATING" ;
VAL_ 1250 VCLEFT_lumbarBState 1 "SEAT_STATE_MOVING_UP" 2 "SEAT_STATE_MOVING_DOWN" 3 "SEAT_STATE_RECALLING" 0 "SEAT_STATE_STOPPED" 5 "SEAT_STATE_UNDEFINED" 4 "SEAT_STATE_CALIBRATING" ;
VAL_ 1250 VCLEFT_lumbarAState 1 "SEAT_STATE_MOVING_UP" 2 "SEAT_STATE_MOVING_DOWN" 3 "SEAT_STATE_RECALLING" 0 "SEAT_STATE_STOPPED" 5 "SEAT_STATE_UNDEFINED" 4 "SEAT_STATE_CALIBRATING" ;
VAL_ 1250 VCLEFT_seatStatusIndex 5 "SEAT_STATUS_INDEX_POSITION" 1 "SEAT_STATUS_INDEX_BACK" 3 "SEAT_STATUS_INDEX_TILT" 4 "SEAT_STATUS_INDEX_LUMBAR" 0 "SEAT_STATUS_INDEX_TRACK" 2 "SEAT_STATUS_INDEX_LIFT" ;
VAL_ 741 DIS_drivePowerMax 511 "SNA" ;
VAL_ 741 DIS_elecPower -1024 "SNA" ;
VAL_ 1037 TAS_nmWakeUpReason 0 "CH_WAKEUP_REASON_NONE" 3 "CH_WAKEUP_REASON_RESET" 2 "CH_WAKEUP_REASON_SWITCH_INPUT" 1 "CH_WAKEUP_REASON_ECU_SPECIFIC" ;
VAL_ 1037 TAS_nmKeepAwakeReason 1 "TAS_KEEPAWAKE_REASON_LEVELING_IN_PROGRESS" 0 "TAS_KEEPAWAKE_REASON_NONE_SNA" 15 "TAS_KEEPAWAKE_REASON_MULTIPLE" ;
VAL_ 968 EPBL_matrixIndex 3 "EPBL_AlertMatrix3" 4 "EPBL_AlertMatrix4" 2 "EPBL_AlertMatrix2" 1 "EPBL_AlertMatrix1" 0 "EPBL_AlertMatrix0" ;
VAL_ 964 PCS_buildType 1 "INFO_PLATFORM_BUILD" 3 "INFO_TRACEABLE_CI_BUILD" 4 "INFO_MFG_BUILD" 2 "INFO_LOCAL_BUILD" 0 "INFO_UNKNOWN_BUILD" ;
VAL_ 964 PCS_infoIndex 25 "INFO_PACKAGE_PN_1_7" 30 "INFO_PACKAGE_SN_8_14" 27 "INFO_PACKAGE_PN_15_20" 0 "INFO_DEPRECATED_0" 29 "INFO_PACKAGE_SN_1_7" 10 "INFO_BUILD_HWID_COMPONENTID" 14 "INFO_BOOTLOADER_SVN" 31 "INFO_SUBCOMPONENT_GITHASH" 19 "INFO_VERSION_DEPRECATED" 7 "INFO_DEPRECATED_7" 255 "INFO_END" 9 "INFO_DEPRECATED_9" 6 "INFO_DEPRECATED_6" 20 "INFO_UDS_PROTOCOL_BOOTCRC" 3 "INFO_DEPRECATED_3" 22 "INFO_VARIANTCRC" 17 "INFO_APP_GITHASH" 8 "INFO_DEPRECATED_8" 26 "INFO_PACKAGE_PN_8_14" 5 "INFO_DEPRECATED_5" 16 "INFO_SUBCOMPONENT" 13 "INFO_APP_CRC" 2 "INFO_DEPRECATED_2" 4 "INFO_DEPRECATED_4" 15 "INFO_BOOTLOADER_CRC" 1 "INFO_DEPRECATED_1" 11 "INFO_PCBAID_ASSYID_USAGEID" 18 "INFO_BOOTLOADER_GITHASH" ;
VAL_ 889 VCSEC_BLEAdvStatusRi 3 "BLE_ADVERTISING_FAULTED" 6 "BLE_CONNECTABLE_ADVERTISING" 5 "BLE_NON_CONNECTABLE_ADVERTISING" 1 "BLE_TIMED_OUT_WHILE_WAITING" 4 "BLE_STOPPED_ADVERTISING" 2 "BLE_ADVERTISING_CHANGING_STATES" 0 "BLE_WAITING_FOR_PREREQUISITES" ;
VAL_ 889 VCSEC_BLEAdvStatusC 3 "BLE_ADVERTISING_FAULTED" 6 "BLE_CONNECTABLE_ADVERTISING" 5 "BLE_NON_CONNECTABLE_ADVERTISING" 1 "BLE_TIMED_OUT_WHILE_WAITING" 4 "BLE_STOPPED_ADVERTISING" 2 "BLE_ADVERTISING_CHANGING_STATES" 0 "BLE_WAITING_FOR_PREREQUISITES" ;
VAL_ 889 VCSEC_BLEAdvStatusRe 3 "BLE_ADVERTISING_FAULTED" 6 "BLE_CONNECTABLE_ADVERTISING" 5 "BLE_NON_CONNECTABLE_ADVERTISING" 1 "BLE_TIMED_OUT_WHILE_WAITING" 4 "BLE_STOPPED_ADVERTISING" 2 "BLE_ADVERTISING_CHANGING_STATES" 0 "BLE_WAITING_FOR_PREREQUISITES" ;
VAL_ 889 VCSEC_BLEAdvStatusL 3 "BLE_ADVERTISING_FAULTED" 6 "BLE_CONNECTABLE_ADVERTISING" 5 "BLE_NON_CONNECTABLE_ADVERTISING" 1 "BLE_TIMED_OUT_WHILE_WAITING" 4 "BLE_STOPPED_ADVERTISING" 2 "BLE_ADVERTISING_CHANGING_STATES" 0 "BLE_WAITING_FOR_PREREQUISITES" ;
VAL_ 889 VCSEC_BLEDeviceIndex 0 "BLEENDPOINT_LEFT_B_PILLAR" 3 "BLEENDPOINT_CENTER_CONSOLE" 2 "BLEENDPOINT_REAR_BUMPER" 1 "BLEENDPOINT_RIGHT_B_PILLAR" ;
VAL_ 281 VCSEC_windowRequestPercent 127 "SNA" ;
VAL_ 281 VCSEC_windowRequestType 1 "WINDOW_REQUEST_GOTO_PERCENT" 0 "WINDOW_REQUEST_IDLE" 2 "WINDOW_REQUEST_GOTO_CRACKED" 3 "WINDOW_REQUEST_GOTO_CLOSED" ;
VAL_ 899 VCRIGHT_estimatedThsSolarLoad 1023 "SNA" ;
VAL_ 899 VCRIGHT_thsSolarLoadVisible 1023 "SNA" ;
VAL_ 899 VCRIGHT_thsSolarLoadInfrared 1023 "SNA" ;
VAL_ 899 VCRIGHT_thsHumidity 255 "SNA" ;
VAL_ 899 VCRIGHT_thsTemperature -128 "SNA" ;
VAL_ 552 EPBR_internalCDPRequest 0 "EPB_CDP_NOT_REQUESTED" 1 "EPB_CDP_REQUESTED" ;
VAL_ 552 EPBR_epbmCDPQualified 0 "EPB_EXTERNAL_APPLY_IDLE" 1 "EPB_EXTERNAL_APPLY_VALID" 2 "EPB_EXTERNAL_APPLY_INVALID" ;
VAL_ 552 EPBR_telltaleLocal 0 "EPB_TELLTALE_LAMP_OFF" 2 "EPB_TELLTALE_LAMP_AMBER_ON" 3 "EPB_TELLTALE_LAMP_RED_FLASH" 1 "EPB_TELLTALE_LAMP_RED_ON" 7 "EPB_TELLTALE_SNA" ;
VAL_ 552 EPBR_summonFaultReason 9 "EPB_SUMMONFAULT_VEH_CAN_FAULT" 21 "EPB_SUMMONFAULT_PASSIVE_REQUEST" 26 "EPB_SUMMONFAULT_START_IN_UNAVAILABLE" 5 "EPB_SUMMONFAULT_DI_FAULT" 4 "EPB_SUMMONFAULT_EPBM_MIA" 12 "EPB_SUMMONFAULT_SPEED" 14 "EPB_SUMMONFAULT_PARK_MIA" 19 "EPB_SUMMONFAULT_EPB_FAULT" 25 "EPB_SUMMONFAULT_REMOTE_UNIT_FAULTED" 11 "EPB_SUMMONFAULT_EPBM_REQUEST" 16 "EPB_SUMMONFAULT_PM_REQUEST" 6 "EPB_SUMMONFAULT_DI_APC_FAULT" 13 "EPB_SUMMONFAULT_EXTERNAL" 23 "EPB_SUMMONFAULT_REMOTE_SUMMON_FAULTED" 24 "EPB_SUMMONFAULT_LOCAL_UNIT_FAULTED" 28 "EPB_SUMMONFAULT_REMOTE_DID_NOT_START" 1 "EPB_SUMMONFAULT_DI_MIA" 15 "EPB_SUMMONFAULT_PM_MIA" 27 "EPB_SUMMONFAULT_INVALID_REMOTE_STATE" 0 "EPB_SUMMONFAULT_NONE" 10 "EPB_SUMMONFAULT_EAC_NOT_ALLOWED" 22 "EPB_SUMMONFAULT_EPBREMOTE_MIA" 18 "EPB_SUMMONFAULT_MISMATCH" 3 "EPB_SUMMONFAULT_ESP_MIA" 2 "EPB_SUMMONFAULT_DAS_MIA" 20 "EPB_SUMMONFAULT_DI_STATE_INVALID" 8 "EPB_SUMMONFAULT_ESP_FAULT" 17 "EPB_SUMMONFAULT_OOC" 7 "EPB_SUMMONFAULT_DAS_FAULT" ;
VAL_ 552 EPBR_esmOperationTrigger 20 "EPB_TRIGGER_TIMEOUT" 2 "EPB_TRIGGER_PBUTTON_PRESSED_FAST" 19 "EPB_TRIGGER_SPEED_FAST" 3 "EPB_TRIGGER_PBUTTON_PRESSED_UNKNOWN" 27 "EPB_TRIGGER_EPBM_DISQUALIFIED" 10 "EPB_TRIGGER_WINCHMODE_UNAVAILABLE" 28 "EPB_TRIGGER_ACCELERATION" 12 "EPB_TRIGGER_DIAG_CLOSE" 24 "EPB_TRIGGER_FAULT" 25 "EPB_TRIGGER_SUMMON_FAULT" 30 "EPB_TRIGGER_DRIVER_IS_LEAVING" 18 "EPB_TRIGGER_SPEED_OKAYTOPARK" 1 "EPB_TRIGGER_PBUTTON_PRESSED_OKTOPARK" 4 "EPB_TRIGGER_PBUTTON_RELEASED" 14 "EPB_TRIGGER_DIAG_EXIT" 21 "EPB_TRIGGER_SAVESTATE_ON_BOOT" 6 "EPB_TRIGGER_DI_UNPARK" 23 "EPB_TRIGGER_SUMMON_COMPLETE" 22 "EPB_TRIGGER_REAPPLY" 26 "EPB_TRIGGER_DISQUALIFIED" 16 "EPB_TRIGGER_USER_CANCEL" 13 "EPB_TRIGGER_DIAG_OPEN" 11 "EPB_TRIGGER_SERVICE" 5 "EPB_TRIGGER_ACTIVE_PARK_REQUEST" 15 "EPB_TRIGGER_USER_CONFIRMED" 8 "EPB_TRIGGER_WINCHMODE_EXIT" 9 "EPB_TRIGGER_WINCHMODE_ENTER" 17 "EPB_TRIGGER_SPEED_STOPPED" 0 "EPB_TRIGGER_PBUTTON_PRESSED_STOPPED" 7 "EPB_TRIGGER_TOUCHSCREEN" 29 "EPB_TRIGGER_SYSTEM_APPLY" ;
VAL_ 552 EPBR_csmFaultReason 5 "CSM_FAULT_APPLY_BLOCKED" 19 "CSM_FAULT_EPBM_MIA" 1 "CSM_FAULT_EPBM_DISABLED" 16 "CSM_FAULT_MOTOR_IDLE_FAULT" 8 "CSM_FAULT_TIMEOUT_APPLY_INRUSH" 3 "CSM_FAULT_STATE_MISMATCH" 13 "CSM_FAULT_TIMEOUT_EPBM_CUTOFF" 15 "CSM_FAULT_TIMEOUT_EPBM_START" 2 "CSM_FAULT_EPBM_FAULTED" 4 "CSM_FAULT_TIMEOUT_CALIBRATE" 12 "CSM_FAULT_TIMEOUT_RELEASE_COMPLETE" 17 "CSM_FAULT_MOTOR_ACTIVE_FAULT" 18 "CSM_FAULT_MOTOR_NOT_READY" 11 "CSM_FAULT_TIMEOUT_RELEASE_WAIT_FOR_ENDSTOP" 0 "CSM_FAULT_NONE" 9 "CSM_FAULT_TIMEOUT_WAIT_FOR_CLAMP" 14 "CSM_FAULT_TIMEOUT_NO_RAMP" 10 "CSM_FAULT_TIMEOUT_RELEASE_INRUSH" 21 "CSM_FAULT_REMOTE_MIA" 20 "CSM_FAULT_NVM_MISMATCH" 6 "CSM_FAULT_RELEASE_BLOCKED" 7 "CSM_FAULT_TIMEOUT_APPLY_COMPLETE" ;
VAL_ 552 EPBR_esmCaliperRequest 2 "CSM_RQST_APPLY" 1 "CSM_RQST_NONE" 4 "CSM_RQST_ENDSTOP" 0 "CSM_RQST_INVALID" 3 "CSM_RQST_RELEASE" ;
VAL_ 552 EPBR_summonState 3 "EPB_SUMMON_ACTIVE" 6 "EPB_SUMMON_UNAVAILABLE" 5 "EPB_SUMMON_FAULT" 4 "EPB_SUMMON_COMPLETE" 1 "EPB_SUMMON_IDLE" 2 "EPB_SUMMON_ARMED" 0 "EPB_SUMMON_INIT" ;
VAL_ 552 EPBR_unitFaultStatus 1 "EPB_STATUS_RETRY" 3 "EPB_STATUS_FAULT_IDLE" 0 "EPB_STATUS_NOMINAL" 2 "EPB_STATUS_FAULT" ;
VAL_ 552 EPBR_unitStatus 14 "EPB_STATUS_SUMMON" 1 "EPB_STATUS_OPEN" 9 "EPB_STATUS_DYNAMIC_APPLYING" 21 "EPB_STATUS_COUNT" 12 "EPB_STATUS_PARK_PENDING" 13 "EPB_STATUS_WINCHMODE_PENDING" 6 "EPB_STATUS_WINCHMODE" 3 "EPB_STATUS_PARK" 0 "EPB_STATUS_UNKNOWN" 4 "EPB_STATUS_START" 18 "EPB_STATUS_RELEASING_FOR_EXTERNAL_PARK" 19 "EPB_STATUS_EXTERNAL_PARKING" 17 "EPB_STATUS_EXTERNAL_DYNAMIC" 10 "EPB_STATUS_RELEASING" 15 "EPB_STATUS_SUMMON_RELEASING" 11 "EPB_STATUS_SERVICE_RELEASING" 7 "EPB_STATUS_WINCHMODE_RELEASING" 16 "EPB_STATUS_SUMMON_PARKING" 8 "EPB_STATUS_PARKING" 2 "EPB_STATUS_DYNAMIC" 5 "EPB_STATUS_SERVICE" 20 "EPB_STATUS_DYNAMIC_PARKING" ;
VAL_ 915 VCRIGHT_epbFaultStatus 1 "EPB_STATUS_RETRY" 3 "EPB_STATUS_FAULT_IDLE" 0 "EPB_STATUS_NOMINAL" 2 "EPB_STATUS_FAULT" ;
VAL_ 915 VCRIGHT_epbmFaultStatus 1 "EPB_STATUS_RETRY" 3 "EPB_STATUS_FAULT_IDLE" 0 "EPB_STATUS_NOMINAL" 2 "EPB_STATUS_FAULT" ;
VAL_ 915 VCRIGHT_epbUnitStatus 14 "EPB_STATUS_SUMMON" 1 "EPB_STATUS_OPEN" 9 "EPB_STATUS_DYNAMIC_APPLYING" 21 "EPB_STATUS_COUNT" 12 "EPB_STATUS_PARK_PENDING" 13 "EPB_STATUS_WINCHMODE_PENDING" 6 "EPB_STATUS_WINCHMODE" 3 "EPB_STATUS_PARK" 0 "EPB_STATUS_UNKNOWN" 4 "EPB_STATUS_START" 18 "EPB_STATUS_RELEASING_FOR_EXTERNAL_PARK" 19 "EPB_STATUS_EXTERNAL_PARKING" 17 "EPB_STATUS_EXTERNAL_DYNAMIC" 10 "EPB_STATUS_RELEASING" 15 "EPB_STATUS_SUMMON_RELEASING" 11 "EPB_STATUS_SERVICE_RELEASING" 7 "EPB_STATUS_WINCHMODE_RELEASING" 16 "EPB_STATUS_SUMMON_PARKING" 8 "EPB_STATUS_PARKING" 2 "EPB_STATUS_DYNAMIC" 5 "EPB_STATUS_SERVICE" 20 "EPB_STATUS_DYNAMIC_PARKING" ;
VAL_ 915 VCRIGHT_epbmUnitStatus 14 "EPB_STATUS_SUMMON" 1 "EPB_STATUS_OPEN" 9 "EPB_STATUS_DYNAMIC_APPLYING" 21 "EPB_STATUS_COUNT" 12 "EPB_STATUS_PARK_PENDING" 13 "EPB_STATUS_WINCHMODE_PENDING" 6 "EPB_STATUS_WINCHMODE" 3 "EPB_STATUS_PARK" 0 "EPB_STATUS_UNKNOWN" 4 "EPB_STATUS_START" 18 "EPB_STATUS_RELEASING_FOR_EXTERNAL_PARK" 19 "EPB_STATUS_EXTERNAL_PARKING" 17 "EPB_STATUS_EXTERNAL_DYNAMIC" 10 "EPB_STATUS_RELEASING" 15 "EPB_STATUS_SUMMON_RELEASING" 11 "EPB_STATUS_SERVICE_RELEASING" 7 "EPB_STATUS_WINCHMODE_RELEASING" 16 "EPB_STATUS_SUMMON_PARKING" 8 "EPB_STATUS_PARKING" 2 "EPB_STATUS_DYNAMIC" 5 "EPB_STATUS_SERVICE" 20 "EPB_STATUS_DYNAMIC_PARKING" ;
VAL_ 915 VCRIGHT_epbmSummonState 3 "EPB_SUMMON_ACTIVE" 6 "EPB_SUMMON_UNAVAILABLE" 5 "EPB_SUMMON_FAULT" 4 "EPB_SUMMON_COMPLETE" 1 "EPB_SUMMON_IDLE" 2 "EPB_SUMMON_ARMED" 0 "EPB_SUMMON_INIT" ;
VAL_ 915 VCRIGHT_epbSummonState 3 "EPB_SUMMON_ACTIVE" 6 "EPB_SUMMON_UNAVAILABLE" 5 "EPB_SUMMON_FAULT" 4 "EPB_SUMMON_COMPLETE" 1 "EPB_SUMMON_IDLE" 2 "EPB_SUMMON_ARMED" 0 "EPB_SUMMON_INIT" ;
VAL_ 915 VCRIGHT_summonFaultReason 9 "EPB_SUMMONFAULT_VEH_CAN_FAULT" 21 "EPB_SUMMONFAULT_PASSIVE_REQUEST" 26 "EPB_SUMMONFAULT_START_IN_UNAVAILABLE" 5 "EPB_SUMMONFAULT_DI_FAULT" 4 "EPB_SUMMONFAULT_EPBM_MIA" 12 "EPB_SUMMONFAULT_SPEED" 14 "EPB_SUMMONFAULT_PARK_MIA" 19 "EPB_SUMMONFAULT_EPB_FAULT" 25 "EPB_SUMMONFAULT_REMOTE_UNIT_FAULTED" 11 "EPB_SUMMONFAULT_EPBM_REQUEST" 16 "EPB_SUMMONFAULT_PM_REQUEST" 6 "EPB_SUMMONFAULT_DI_APC_FAULT" 13 "EPB_SUMMONFAULT_EXTERNAL" 23 "EPB_SUMMONFAULT_REMOTE_SUMMON_FAULTED" 24 "EPB_SUMMONFAULT_LOCAL_UNIT_FAULTED" 28 "EPB_SUMMONFAULT_REMOTE_DID_NOT_START" 1 "EPB_SUMMONFAULT_DI_MIA" 15 "EPB_SUMMONFAULT_PM_MIA" 27 "EPB_SUMMONFAULT_INVALID_REMOTE_STATE" 0 "EPB_SUMMONFAULT_NONE" 10 "EPB_SUMMONFAULT_EAC_NOT_ALLOWED" 22 "EPB_SUMMONFAULT_EPBREMOTE_MIA" 18 "EPB_SUMMONFAULT_MISMATCH" 3 "EPB_SUMMONFAULT_ESP_MIA" 2 "EPB_SUMMONFAULT_DAS_MIA" 20 "EPB_SUMMONFAULT_DI_STATE_INVALID" 8 "EPB_SUMMONFAULT_ESP_FAULT" 17 "EPB_SUMMONFAULT_OOC" 7 "EPB_SUMMONFAULT_DAS_FAULT" ;
VAL_ 915 VCRIGHT_cdpEnumDummy 0 "EPB_EXTERNAL_APPLY_IDLE" 1 "EPB_EXTERNAL_APPLY_VALID" 2 "EPB_EXTERNAL_APPLY_INVALID" ;
VAL_ 915 VCRIGHT_epbmCaliperState 5 "EPB_SAVED_CALIPERSTATE_SERVICE" 1 "EPB_SAVED_CALIPERSTATE_UNKNOWN" 4 "EPB_SAVED_CALIPERSTATE_OPEN" 2 "EPB_SAVED_CALIPERSTATE_REAPPLY" 0 "EPB_SAVED_CALIPERSTATE_UNSAVED" 3 "EPB_SAVED_CALIPERSTATE_PARK" ;
VAL_ 915 VCRIGHT_epbmDebugIndex 0 "EPBM_STATES" 1 "EPBM_TRANSITIONS" ;
VAL_ 898 VCLEFT_CPULoad1000msTask 255 "SNA" ;
VAL_ 898 VCLEFT_CPULoad100msTask 255 "SNA" ;
VAL_ 898 VCLEFT_CPULoad10msTask 255 "SNA" ;
VAL_ 898 VCLEFT_CPULoad1msTask 255 "SNA" ;
VAL_ 898 VCLEFT_CPULoadTotal 255 "SNA" ;
VAL_ 694 DI_btcStateUI 0 "OFF" 1 "ON" ;
VAL_ 694 DI_ptcStateUI 3 "SNA" 0 "FAULTED" 1 "BACKUP" 2 "ON" ;
VAL_ 694 DI_tractionControlModeUI 0 "TC_NORMAL" 1 "TC_SLIP_START" 4 "TC_ROLLS_MODE" 2 "TC_DEV_MODE_1" 5 "TC_DYNO_MODE" 3 "TC_DEV_MODE_2" ;
VAL_ 694 DI_tcTelltaleOn 0 "TELLTALE_OFF" 1 "TELLTALE_ON" ;
VAL_ 694 DI_tcTelltaleFlash 0 "TELLTALE_OFF" 1 "TELLTALE_ON" ;
VAL_ 694 DI_vdcTelltaleOn 0 "TELLTALE_OFF" 1 "TELLTALE_ON" ;
VAL_ 694 DI_vdcTelltaleFlash 0 "TELLTALE_OFF" 1 "TELLTALE_ON" ;
VAL_ 1033 DAS_nmKeepAwakeReason 2 "DAS_KEEPAWAKE_REASON_TELEMETRY" 1 "DAS_KEEPAWAKE_REASON_PRECONDITIONING" 0 "DAS_KEEPAWAKE_REASON_NONE_SNA" ;
VAL_ 706 VCLEFT_windowStopReqReasonLR 5 "WINDOW_STOP_REQUEST_REASON_STALL" 7 "WINDOW_STOP_REQUEST_REASON_FULL_OPEN_SOFT_STOP" 8 "WINDOW_STOP_REQUEST_REASON_EXTERNAL_REQUEST" 3 "WINDOW_STOP_REQUEST_REASON_REAR_LOCKOUT" 6 "WINDOW_STOP_REQUEST_REASON_STATE_TIMEOUT" 4 "WINDOW_STOP_REQUEST_REASON_THERMAL" 0 "WINDOW_STOP_REQUEST_REASON_NONE" 1 "WINDOW_STOP_REQUEST_REASON_SWITCH_CANCEL_AUTO_MOVEMENT" 2 "WINDOW_STOP_REQUEST_REASON_SWITCH_RELEASED" ;
VAL_ 706 VCLEFT_windowStopReasonLR 6 "WINDOW_STOP_REASON_STATE_TIMEOUT" 0 "WINDOW_STOP_REASON_NONE" 3 "WINDOW_STOP_REASON_TARGET_REACHED" 1 "WINDOW_STOP_REASON_DOOR_OPEN_TRIM_PROTECT" 4 "WINDOW_STOP_REASON_STOP_REQUEST" 2 "WINDOW_STOP_REASON_NEW_REQUEST" 5 "WINDOW_STOP_REASON_FULL_OPEN_SOFT_STOP" ;
VAL_ 706 VCLEFT_windowThermalModeLR 0 "WINDOW_THERMAL_MODE_SNA" 2 "WINDOW_THERMAL_MODE_ALERT" 1 "WINDOW_THERMAL_MODE_NORMAL" 3 "WINDOW_THERMAL_MODE_CRITICAL" ;
VAL_ 706 VCLEFT_windowStateLR 8 "WINDOW_STATE_BACKDRIVE" 0 "WINDOW_STATE_STOPPED" 5 "WINDOW_STATE_SHORT_DROP_REVERSE" 4 "WINDOW_STATE_SHORT_DROP" 3 "WINDOW_STATE_BACKOFF" 7 "WINDOW_STATE_MOVING_AUTO_DOWN" 2 "WINDOW_STATE_MOVING_DOWN" 1 "WINDOW_STATE_MOVING_UP" 6 "WINDOW_STATE_MOVING_AUTO_UP" ;
VAL_ 706 VCLEFT_windowStopReqReasonLF 5 "WINDOW_STOP_REQUEST_REASON_STALL" 7 "WINDOW_STOP_REQUEST_REASON_FULL_OPEN_SOFT_STOP" 8 "WINDOW_STOP_REQUEST_REASON_EXTERNAL_REQUEST" 3 "WINDOW_STOP_REQUEST_REASON_REAR_LOCKOUT" 6 "WINDOW_STOP_REQUEST_REASON_STATE_TIMEOUT" 4 "WINDOW_STOP_REQUEST_REASON_THERMAL" 0 "WINDOW_STOP_REQUEST_REASON_NONE" 1 "WINDOW_STOP_REQUEST_REASON_SWITCH_CANCEL_AUTO_MOVEMENT" 2 "WINDOW_STOP_REQUEST_REASON_SWITCH_RELEASED" ;
VAL_ 706 VCLEFT_windowStopReasonLF 6 "WINDOW_STOP_REASON_STATE_TIMEOUT" 0 "WINDOW_STOP_REASON_NONE" 3 "WINDOW_STOP_REASON_TARGET_REACHED" 1 "WINDOW_STOP_REASON_DOOR_OPEN_TRIM_PROTECT" 4 "WINDOW_STOP_REASON_STOP_REQUEST" 2 "WINDOW_STOP_REASON_NEW_REQUEST" 5 "WINDOW_STOP_REASON_FULL_OPEN_SOFT_STOP" ;
VAL_ 706 VCLEFT_windowThermalModeLF 0 "WINDOW_THERMAL_MODE_SNA" 2 "WINDOW_THERMAL_MODE_ALERT" 1 "WINDOW_THERMAL_MODE_NORMAL" 3 "WINDOW_THERMAL_MODE_CRITICAL" ;
VAL_ 706 VCLEFT_windowStateLF 8 "WINDOW_STATE_BACKDRIVE" 0 "WINDOW_STATE_STOPPED" 5 "WINDOW_STATE_SHORT_DROP_REVERSE" 4 "WINDOW_STATE_SHORT_DROP" 3 "WINDOW_STATE_BACKOFF" 7 "WINDOW_STATE_MOVING_AUTO_DOWN" 2 "WINDOW_STATE_MOVING_DOWN" 1 "WINDOW_STATE_MOVING_UP" 6 "WINDOW_STATE_MOVING_AUTO_UP" ;
VAL_ 706 VCLEFT_windowStatusIndex 0 "Mux0" 1 "Mux1" ;
VAL_ 1332 VCFRONT_a334_vehicleState 3 "VEHICLE_POWER_STATE_DRIVE" 1 "VEHICLE_POWER_STATE_CONDITIONING" 2 "VEHICLE_POWER_STATE_ACCESSORY" 0 "VEHICLE_POWER_STATE_OFF" ;
VAL_ 1332 VCFRONT_a346_vehicleState 3 "VEHICLE_POWER_STATE_DRIVE" 1 "VEHICLE_POWER_STATE_CONDITIONING" 2 "VEHICLE_POWER_STATE_ACCESSORY" 0 "VEHICLE_POWER_STATE_OFF" ;
VAL_ 1332 VCFRONT_a339_vehicleState 3 "VEHICLE_POWER_STATE_DRIVE" 1 "VEHICLE_POWER_STATE_CONDITIONING" 2 "VEHICLE_POWER_STATE_ACCESSORY" 0 "VEHICLE_POWER_STATE_OFF" ;
VAL_ 1332 VCFRONT_a345_vehicleState 3 "VEHICLE_POWER_STATE_DRIVE" 1 "VEHICLE_POWER_STATE_CONDITIONING" 2 "VEHICLE_POWER_STATE_ACCESSORY" 0 "VEHICLE_POWER_STATE_OFF" ;
VAL_ 1332 VCFRONT_a340_vehicleState 3 "VEHICLE_POWER_STATE_DRIVE" 1 "VEHICLE_POWER_STATE_CONDITIONING" 2 "VEHICLE_POWER_STATE_ACCESSORY" 0 "VEHICLE_POWER_STATE_OFF" ;
VAL_ 1332 VCFRONT_a335_vehicleState 3 "VEHICLE_POWER_STATE_DRIVE" 1 "VEHICLE_POWER_STATE_CONDITIONING" 2 "VEHICLE_POWER_STATE_ACCESSORY" 0 "VEHICLE_POWER_STATE_OFF" ;
VAL_ 1332 VCFRONT_a336_vehicleState 3 "VEHICLE_POWER_STATE_DRIVE" 1 "VEHICLE_POWER_STATE_CONDITIONING" 2 "VEHICLE_POWER_STATE_ACCESSORY" 0 "VEHICLE_POWER_STATE_OFF" ;
VAL_ 1332 VCFRONT_a349_vehicleState 3 "VEHICLE_POWER_STATE_DRIVE" 1 "VEHICLE_POWER_STATE_CONDITIONING" 2 "VEHICLE_POWER_STATE_ACCESSORY" 0 "VEHICLE_POWER_STATE_OFF" ;
VAL_ 1332 VCFRONT_a344_vehicleState 3 "VEHICLE_POWER_STATE_DRIVE" 1 "VEHICLE_POWER_STATE_CONDITIONING" 2 "VEHICLE_POWER_STATE_ACCESSORY" 0 "VEHICLE_POWER_STATE_OFF" ;
VAL_ 1332 VCFRONT_a343_vehicleState 3 "VEHICLE_POWER_STATE_DRIVE" 1 "VEHICLE_POWER_STATE_CONDITIONING" 2 "VEHICLE_POWER_STATE_ACCESSORY" 0 "VEHICLE_POWER_STATE_OFF" ;
VAL_ 1332 VCFRONT_a348_vehicleState 3 "VEHICLE_POWER_STATE_DRIVE" 1 "VEHICLE_POWER_STATE_CONDITIONING" 2 "VEHICLE_POWER_STATE_ACCESSORY" 0 "VEHICLE_POWER_STATE_OFF" ;
VAL_ 1332 VCFRONT_a337_vehicleState 3 "VEHICLE_POWER_STATE_DRIVE" 1 "VEHICLE_POWER_STATE_CONDITIONING" 2 "VEHICLE_POWER_STATE_ACCESSORY" 0 "VEHICLE_POWER_STATE_OFF" ;
VAL_ 1332 VCFRONT_a338_vehicleState 3 "VEHICLE_POWER_STATE_DRIVE" 1 "VEHICLE_POWER_STATE_CONDITIONING" 2 "VEHICLE_POWER_STATE_ACCESSORY" 0 "VEHICLE_POWER_STATE_OFF" ;
VAL_ 1332 VCFRONT_a347_vehicleState 3 "VEHICLE_POWER_STATE_DRIVE" 1 "VEHICLE_POWER_STATE_CONDITIONING" 2 "VEHICLE_POWER_STATE_ACCESSORY" 0 "VEHICLE_POWER_STATE_OFF" ;
VAL_ 1332 VCFRONT_a342_vehicleState 3 "VEHICLE_POWER_STATE_DRIVE" 1 "VEHICLE_POWER_STATE_CONDITIONING" 2 "VEHICLE_POWER_STATE_ACCESSORY" 0 "VEHICLE_POWER_STATE_OFF" ;
VAL_ 1332 VCFRONT_a341_vehicleState 3 "VEHICLE_POWER_STATE_DRIVE" 1 "VEHICLE_POWER_STATE_CONDITIONING" 2 "VEHICLE_POWER_STATE_ACCESSORY" 0 "VEHICLE_POWER_STATE_OFF" ;
VAL_ 1332 VCFRONT_a311_vehicleState 3 "VEHICLE_POWER_STATE_DRIVE" 1 "VEHICLE_POWER_STATE_CONDITIONING" 2 "VEHICLE_POWER_STATE_ACCESSORY" 0 "VEHICLE_POWER_STATE_OFF" ;
VAL_ 1332 VCFRONT_a316_vehicleState 3 "VEHICLE_POWER_STATE_DRIVE" 1 "VEHICLE_POWER_STATE_CONDITIONING" 2 "VEHICLE_POWER_STATE_ACCESSORY" 0 "VEHICLE_POWER_STATE_OFF" ;
VAL_ 1332 VCFRONT_a320_vehicleState 3 "VEHICLE_POWER_STATE_DRIVE" 1 "VEHICLE_POWER_STATE_CONDITIONING" 2 "VEHICLE_POWER_STATE_ACCESSORY" 0 "VEHICLE_POWER_STATE_OFF" ;
VAL_ 1332 VCFRONT_a323_vehicleState 3 "VEHICLE_POWER_STATE_DRIVE" 1 "VEHICLE_POWER_STATE_CONDITIONING" 2 "VEHICLE_POWER_STATE_ACCESSORY" 0 "VEHICLE_POWER_STATE_OFF" ;
VAL_ 1332 VCFRONT_a318_vehicleState 3 "VEHICLE_POWER_STATE_DRIVE" 1 "VEHICLE_POWER_STATE_CONDITIONING" 2 "VEHICLE_POWER_STATE_ACCESSORY" 0 "VEHICLE_POWER_STATE_OFF" ;
VAL_ 1332 VCFRONT_a312_vehicleState 3 "VEHICLE_POWER_STATE_DRIVE" 1 "VEHICLE_POWER_STATE_CONDITIONING" 2 "VEHICLE_POWER_STATE_ACCESSORY" 0 "VEHICLE_POWER_STATE_OFF" ;
VAL_ 1332 VCFRONT_a317_vehicleState 3 "VEHICLE_POWER_STATE_DRIVE" 1 "VEHICLE_POWER_STATE_CONDITIONING" 2 "VEHICLE_POWER_STATE_ACCESSORY" 0 "VEHICLE_POWER_STATE_OFF" ;
VAL_ 1332 VCFRONT_a314_vehicleState 3 "VEHICLE_POWER_STATE_DRIVE" 1 "VEHICLE_POWER_STATE_CONDITIONING" 2 "VEHICLE_POWER_STATE_ACCESSORY" 0 "VEHICLE_POWER_STATE_OFF" ;
VAL_ 1332 VCFRONT_a322_vehicleState 3 "VEHICLE_POWER_STATE_DRIVE" 1 "VEHICLE_POWER_STATE_CONDITIONING" 2 "VEHICLE_POWER_STATE_ACCESSORY" 0 "VEHICLE_POWER_STATE_OFF" ;
VAL_ 1332 VCFRONT_a319_vehicleState 3 "VEHICLE_POWER_STATE_DRIVE" 1 "VEHICLE_POWER_STATE_CONDITIONING" 2 "VEHICLE_POWER_STATE_ACCESSORY" 0 "VEHICLE_POWER_STATE_OFF" ;
VAL_ 1332 VCFRONT_a325_vehicleState 3 "VEHICLE_POWER_STATE_DRIVE" 1 "VEHICLE_POWER_STATE_CONDITIONING" 2 "VEHICLE_POWER_STATE_ACCESSORY" 0 "VEHICLE_POWER_STATE_OFF" ;
VAL_ 1332 VCFRONT_a313_vehicleState 3 "VEHICLE_POWER_STATE_DRIVE" 1 "VEHICLE_POWER_STATE_CONDITIONING" 2 "VEHICLE_POWER_STATE_ACCESSORY" 0 "VEHICLE_POWER_STATE_OFF" ;
VAL_ 1332 VCFRONT_a310_vehicleState 3 "VEHICLE_POWER_STATE_DRIVE" 1 "VEHICLE_POWER_STATE_CONDITIONING" 2 "VEHICLE_POWER_STATE_ACCESSORY" 0 "VEHICLE_POWER_STATE_OFF" ;
VAL_ 1332 VCFRONT_a260_hvState 6 "HV_UP" 5 "HV_UP_FOR_DC_CHARGE" 0 "HV_DOWN" 2 "HV_GOING_DOWN" 1 "HV_COMING_UP" 4 "HV_UP_FOR_CHARGE" 3 "HV_UP_FOR_DRIVE" ;
VAL_ 1332 VCFRONT_a315_vehicleState 3 "VEHICLE_POWER_STATE_DRIVE" 1 "VEHICLE_POWER_STATE_CONDITIONING" 2 "VEHICLE_POWER_STATE_ACCESSORY" 0 "VEHICLE_POWER_STATE_OFF" ;
VAL_ 1332 VCFRONT_a321_vehicleState 3 "VEHICLE_POWER_STATE_DRIVE" 1 "VEHICLE_POWER_STATE_CONDITIONING" 2 "VEHICLE_POWER_STATE_ACCESSORY" 0 "VEHICLE_POWER_STATE_OFF" ;
VAL_ 1332 VCFRONT_a324_vehicleState 3 "VEHICLE_POWER_STATE_DRIVE" 1 "VEHICLE_POWER_STATE_CONDITIONING" 2 "VEHICLE_POWER_STATE_ACCESSORY" 0 "VEHICLE_POWER_STATE_OFF" ;
VAL_ 1332 VCFRONT_a333_vehicleState 3 "VEHICLE_POWER_STATE_DRIVE" 1 "VEHICLE_POWER_STATE_CONDITIONING" 2 "VEHICLE_POWER_STATE_ACCESSORY" 0 "VEHICLE_POWER_STATE_OFF" ;
VAL_ 1332 VCFRONT_a326_vehicleState 3 "VEHICLE_POWER_STATE_DRIVE" 1 "VEHICLE_POWER_STATE_CONDITIONING" 2 "VEHICLE_POWER_STATE_ACCESSORY" 0 "VEHICLE_POWER_STATE_OFF" ;
VAL_ 1332 VCFRONT_a329_vehicleState 3 "VEHICLE_POWER_STATE_DRIVE" 1 "VEHICLE_POWER_STATE_CONDITIONING" 2 "VEHICLE_POWER_STATE_ACCESSORY" 0 "VEHICLE_POWER_STATE_OFF" ;
VAL_ 1332 VCFRONT_a330_vehicleState 3 "VEHICLE_POWER_STATE_DRIVE" 1 "VEHICLE_POWER_STATE_CONDITIONING" 2 "VEHICLE_POWER_STATE_ACCESSORY" 0 "VEHICLE_POWER_STATE_OFF" ;
VAL_ 1332 VCFRONT_a328_vehicleState 3 "VEHICLE_POWER_STATE_DRIVE" 1 "VEHICLE_POWER_STATE_CONDITIONING" 2 "VEHICLE_POWER_STATE_ACCESSORY" 0 "VEHICLE_POWER_STATE_OFF" ;
VAL_ 1332 VCFRONT_a331_vehicleState 3 "VEHICLE_POWER_STATE_DRIVE" 1 "VEHICLE_POWER_STATE_CONDITIONING" 2 "VEHICLE_POWER_STATE_ACCESSORY" 0 "VEHICLE_POWER_STATE_OFF" ;
VAL_ 1332 VCFRONT_a332_vehicleState 3 "VEHICLE_POWER_STATE_DRIVE" 1 "VEHICLE_POWER_STATE_CONDITIONING" 2 "VEHICLE_POWER_STATE_ACCESSORY" 0 "VEHICLE_POWER_STATE_OFF" ;
VAL_ 1332 VCFRONT_a260_batterySMState 2 "BATTERY_SM_STATE_DISCHARGE" 7 "BATTERY_SM_STATE_FAULT" 0 "BATTERY_SM_STATE_INIT" 3 "BATTERY_SM_STATE_STANDBY" 4 "BATTERY_SM_STATE_RESISTANCE_ESTIMATION" 5 "BATTERY_SM_STATE_OTA_STANDBY" 6 "BATTERY_SM_STATE_DISCONNECTED_BATTERY_TEST" 1 "BATTERY_SM_STATE_CHARGE" ;
VAL_ 1332 VCFRONT_a327_vehicleState 3 "VEHICLE_POWER_STATE_DRIVE" 1 "VEHICLE_POWER_STATE_CONDITIONING" 2 "VEHICLE_POWER_STATE_ACCESSORY" 0 "VEHICLE_POWER_STATE_OFF" ;
VAL_ 1332 VCFRONT_a260_vehiclePowerState 3 "VEHICLE_POWER_STATE_DRIVE" 1 "VEHICLE_POWER_STATE_CONDITIONING" 2 "VEHICLE_POWER_STATE_ACCESSORY" 0 "VEHICLE_POWER_STATE_OFF" ;
VAL_ 1332 VCFRONT_a257_vehicleState 5 "VEHICLE_STATUS_SLEEP_SHUTDOWN" 12 "VEHICLE_STATUS_CONDITIONING" 9 "VEHICLE_STATUS_HV_UP_STANDBY" 13 "VEHICLE_STATUS_DRIVE" 6 "VEHICLE_STATUS_SLEEP_STANDBY" 4 "VEHICLE_STATUS_SYSTEM_CHECKS" 10 "VEHICLE_STATUS_ACCESSORY" 14 "VEHICLE_STATUS_CRASH" 2 "VEHICLE_STATUS_SILENT_WAKE" 16 "VEHICLE_STATUS_TURN_ON_RAILS" 1 "VEHICLE_STATUS_LOW_POWER_STANDBY" 8 "VEHICLE_STATUS_LV_AWAKE" 0 "VEHICLE_STATUS_INIT" 15 "VEHICLE_STATUS_OTA" 3 "VEHICLE_STATUS_BATTERY_POST_WAKE" 7 "VEHICLE_STATUS_LV_SHUTDOWN" 17 "VEHICLE_STATUS_RESET" 11 "VEHICLE_STATUS_ACCESSORY_PLUS" ;
VAL_ 1332 VCFRONT_a188_vehicleState 5 "VEHICLE_STATUS_SLEEP_SHUTDOWN" 12 "VEHICLE_STATUS_CONDITIONING" 9 "VEHICLE_STATUS_HV_UP_STANDBY" 13 "VEHICLE_STATUS_DRIVE" 6 "VEHICLE_STATUS_SLEEP_STANDBY" 4 "VEHICLE_STATUS_SYSTEM_CHECKS" 10 "VEHICLE_STATUS_ACCESSORY" 14 "VEHICLE_STATUS_CRASH" 2 "VEHICLE_STATUS_SILENT_WAKE" 16 "VEHICLE_STATUS_TURN_ON_RAILS" 1 "VEHICLE_STATUS_LOW_POWER_STANDBY" 8 "VEHICLE_STATUS_LV_AWAKE" 0 "VEHICLE_STATUS_INIT" 15 "VEHICLE_STATUS_OTA" 3 "VEHICLE_STATUS_BATTERY_POST_WAKE" 7 "VEHICLE_STATUS_LV_SHUTDOWN" 17 "VEHICLE_STATUS_RESET" 11 "VEHICLE_STATUS_ACCESSORY_PLUS" ;
VAL_ 1332 VCFRONT_a257_vcrightLockoutStatu 0 "EFUSE_LOCKOUT_STATUS_IDLE" 1 "EFUSE_LOCKOUT_STATUS_PENDING" 2 "EFUSE_LOCKOUT_STATUS_ACTIVE" ;
VAL_ 1332 VCFRONT_a196_batterySMState 2 "BATTERY_SM_STATE_DISCHARGE" 7 "BATTERY_SM_STATE_FAULT" 0 "BATTERY_SM_STATE_INIT" 3 "BATTERY_SM_STATE_STANDBY" 4 "BATTERY_SM_STATE_RESISTANCE_ESTIMATION" 5 "BATTERY_SM_STATE_OTA_STANDBY" 6 "BATTERY_SM_STATE_DISCONNECTED_BATTERY_TEST" 1 "BATTERY_SM_STATE_CHARGE" ;
VAL_ 1332 VCFRONT_a196_vehiclePowerState 3 "VEHICLE_POWER_STATE_DRIVE" 1 "VEHICLE_POWER_STATE_CONDITIONING" 2 "VEHICLE_POWER_STATE_ACCESSORY" 0 "VEHICLE_POWER_STATE_OFF" ;
VAL_ 1332 VCFRONT_a182_ambientTemp 0 "SNA" ;
VAL_ 1332 VCFRONT_a196_frunkLatchStatus 8 "LATCH_FAULT" 2 "LATCH_CLOSED" 1 "LATCH_OPENED" 3 "LATCH_CLOSING" 7 "LATCH_DEFAULT" 4 "LATCH_OPENING" 5 "LATCH_AJAR" 6 "LATCH_TIMEOUT" 0 "LATCH_SNA" ;
VAL_ 1332 VCFRONT_a204_epas3sSelfTest 9 "EFUSE_SELF_TEST_EFUSE_RESULT_FAILED_TURN_OFF_PATH_TOO_SLOW" 4 "EFUSE_SELF_TEST_EFUSE_RESULT_FAILED_EFUSE_OUTPUT_SHORT" 1 "EFUSE_SELF_TEST_EFUSE_RESULT_RUNNING" 10 "EFUSE_SELF_TEST_EFUSE_RESULT_FAILED_NOT_LATCHED" 2 "EFUSE_SELF_TEST_EFUSE_RESULT_PASSED" 5 "EFUSE_SELF_TEST_EFUSE_RESULT_FAILED_POWER_FET_STUCK_ON" 11 "EFUSE_SELF_TEST_EFUSE_RESULT_SKIPPED" 3 "EFUSE_SELF_TEST_EFUSE_RESULT_FAILED_RAILS_UNSTABLE" 6 "EFUSE_SELF_TEST_EFUSE_RESULT_FAILED_ENABLE_LOW_MALFUNCTION" 0 "EFUSE_SELF_TEST_EFUSE_RESULT_NOT_RUN" 8 "EFUSE_SELF_TEST_EFUSE_RESULT_FAILED_ENABLE_HIGH_MALFUNCTION" 7 "EFUSE_SELF_TEST_EFUSE_RESULT_FAILED_POWER_FET_CHANNEL_OPEN" ;
VAL_ 1332 VCFRONT_a142_driverState 11 "SPI_COMMS_DOWN" 3 "INIT_SPI" 9 "FAULT_OPEN_COIL" 2 "HARD_RESET" 1 "HARD_RESET_SETUP" 5 "ENABLE_MOTOR" 0 "UNPOWERED" 4 "SPI_ERROR" 10 "DRIVER_FAULT" 6 "READY" 7 "STALL" 8 "FAULT_SHORT_COIL" ;
VAL_ 1332 VCFRONT_a200_vcleftSelfTest 9 "EFUSE_SELF_TEST_EFUSE_RESULT_FAILED_TURN_OFF_PATH_TOO_SLOW" 4 "EFUSE_SELF_TEST_EFUSE_RESULT_FAILED_EFUSE_OUTPUT_SHORT" 1 "EFUSE_SELF_TEST_EFUSE_RESULT_RUNNING" 10 "EFUSE_SELF_TEST_EFUSE_RESULT_FAILED_NOT_LATCHED" 2 "EFUSE_SELF_TEST_EFUSE_RESULT_PASSED" 5 "EFUSE_SELF_TEST_EFUSE_RESULT_FAILED_POWER_FET_STUCK_ON" 11 "EFUSE_SELF_TEST_EFUSE_RESULT_SKIPPED" 3 "EFUSE_SELF_TEST_EFUSE_RESULT_FAILED_RAILS_UNSTABLE" 6 "EFUSE_SELF_TEST_EFUSE_RESULT_FAILED_ENABLE_LOW_MALFUNCTION" 0 "EFUSE_SELF_TEST_EFUSE_RESULT_NOT_RUN" 8 "EFUSE_SELF_TEST_EFUSE_RESULT_FAILED_ENABLE_HIGH_MALFUNCTION" 7 "EFUSE_SELF_TEST_EFUSE_RESULT_FAILED_POWER_FET_CHANNEL_OPEN" ;
VAL_ 1332 VCFRONT_a207_vbatFusedSelfTest 9 "EFUSE_SELF_TEST_EFUSE_RESULT_FAILED_TURN_OFF_PATH_TOO_SLOW" 4 "EFUSE_SELF_TEST_EFUSE_RESULT_FAILED_EFUSE_OUTPUT_SHORT" 1 "EFUSE_SELF_TEST_EFUSE_RESULT_RUNNING" 10 "EFUSE_SELF_TEST_EFUSE_RESULT_FAILED_NOT_LATCHED" 2 "EFUSE_SELF_TEST_EFUSE_RESULT_PASSED" 5 "EFUSE_SELF_TEST_EFUSE_RESULT_FAILED_POWER_FET_STUCK_ON" 11 "EFUSE_SELF_TEST_EFUSE_RESULT_SKIPPED" 3 "EFUSE_SELF_TEST_EFUSE_RESULT_FAILED_RAILS_UNSTABLE" 6 "EFUSE_SELF_TEST_EFUSE_RESULT_FAILED_ENABLE_LOW_MALFUNCTION" 0 "EFUSE_SELF_TEST_EFUSE_RESULT_NOT_RUN" 8 "EFUSE_SELF_TEST_EFUSE_RESULT_FAILED_ENABLE_HIGH_MALFUNCTION" 7 "EFUSE_SELF_TEST_EFUSE_RESULT_FAILED_POWER_FET_CHANNEL_OPEN" ;
VAL_ 1332 VCFRONT_a176_vehicleState 5 "VEHICLE_STATUS_SLEEP_SHUTDOWN" 12 "VEHICLE_STATUS_CONDITIONING" 9 "VEHICLE_STATUS_HV_UP_STANDBY" 13 "VEHICLE_STATUS_DRIVE" 6 "VEHICLE_STATUS_SLEEP_STANDBY" 4 "VEHICLE_STATUS_SYSTEM_CHECKS" 10 "VEHICLE_STATUS_ACCESSORY" 14 "VEHICLE_STATUS_CRASH" 2 "VEHICLE_STATUS_SILENT_WAKE" 16 "VEHICLE_STATUS_TURN_ON_RAILS" 1 "VEHICLE_STATUS_LOW_POWER_STANDBY" 8 "VEHICLE_STATUS_LV_AWAKE" 0 "VEHICLE_STATUS_INIT" 15 "VEHICLE_STATUS_OTA" 3 "VEHICLE_STATUS_BATTERY_POST_WAKE" 7 "VEHICLE_STATUS_LV_SHUTDOWN" 17 "VEHICLE_STATUS_RESET" 11 "VEHICLE_STATUS_ACCESSORY_PLUS" ;
VAL_ 1332 VCFRONT_a202_pcsSelfTest 9 "EFUSE_SELF_TEST_EFUSE_RESULT_FAILED_TURN_OFF_PATH_TOO_SLOW" 4 "EFUSE_SELF_TEST_EFUSE_RESULT_FAILED_EFUSE_OUTPUT_SHORT" 1 "EFUSE_SELF_TEST_EFUSE_RESULT_RUNNING" 10 "EFUSE_SELF_TEST_EFUSE_RESULT_FAILED_NOT_LATCHED" 2 "EFUSE_SELF_TEST_EFUSE_RESULT_PASSED" 5 "EFUSE_SELF_TEST_EFUSE_RESULT_FAILED_POWER_FET_STUCK_ON" 11 "EFUSE_SELF_TEST_EFUSE_RESULT_SKIPPED" 3 "EFUSE_SELF_TEST_EFUSE_RESULT_FAILED_RAILS_UNSTABLE" 6 "EFUSE_SELF_TEST_EFUSE_RESULT_FAILED_ENABLE_LOW_MALFUNCTION" 0 "EFUSE_SELF_TEST_EFUSE_RESULT_NOT_RUN" 8 "EFUSE_SELF_TEST_EFUSE_RESULT_FAILED_ENABLE_HIGH_MALFUNCTION" 7 "EFUSE_SELF_TEST_EFUSE_RESULT_FAILED_POWER_FET_CHANNEL_OPEN" ;
VAL_ 1332 VCFRONT_a201_vcrightSelfTest 9 "EFUSE_SELF_TEST_EFUSE_RESULT_FAILED_TURN_OFF_PATH_TOO_SLOW" 4 "EFUSE_SELF_TEST_EFUSE_RESULT_FAILED_EFUSE_OUTPUT_SHORT" 1 "EFUSE_SELF_TEST_EFUSE_RESULT_RUNNING" 10 "EFUSE_SELF_TEST_EFUSE_RESULT_FAILED_NOT_LATCHED" 2 "EFUSE_SELF_TEST_EFUSE_RESULT_PASSED" 5 "EFUSE_SELF_TEST_EFUSE_RESULT_FAILED_POWER_FET_STUCK_ON" 11 "EFUSE_SELF_TEST_EFUSE_RESULT_SKIPPED" 3 "EFUSE_SELF_TEST_EFUSE_RESULT_FAILED_RAILS_UNSTABLE" 6 "EFUSE_SELF_TEST_EFUSE_RESULT_FAILED_ENABLE_LOW_MALFUNCTION" 0 "EFUSE_SELF_TEST_EFUSE_RESULT_NOT_RUN" 8 "EFUSE_SELF_TEST_EFUSE_RESULT_FAILED_ENABLE_HIGH_MALFUNCTION" 7 "EFUSE_SELF_TEST_EFUSE_RESULT_FAILED_POWER_FET_CHANNEL_OPEN" ;
VAL_ 1332 VCFRONT_a302_LINFrameStatus 4 "LIN_FRAME_STATUS_NA" 0 "LIN_FRAME_STATUS_UNKNOWN" 3 "LIN_FRAME_STATUS_ERROR" 2 "LIN_FRAME_STATUS_TIMEOUT" 1 "LIN_FRAME_STATUS_OK" ;
VAL_ 1332 VCFRONT_a205_iBoosterSelfTest 9 "EFUSE_SELF_TEST_EFUSE_RESULT_FAILED_TURN_OFF_PATH_TOO_SLOW" 4 "EFUSE_SELF_TEST_EFUSE_RESULT_FAILED_EFUSE_OUTPUT_SHORT" 1 "EFUSE_SELF_TEST_EFUSE_RESULT_RUNNING" 10 "EFUSE_SELF_TEST_EFUSE_RESULT_FAILED_NOT_LATCHED" 2 "EFUSE_SELF_TEST_EFUSE_RESULT_PASSED" 5 "EFUSE_SELF_TEST_EFUSE_RESULT_FAILED_POWER_FET_STUCK_ON" 11 "EFUSE_SELF_TEST_EFUSE_RESULT_SKIPPED" 3 "EFUSE_SELF_TEST_EFUSE_RESULT_FAILED_RAILS_UNSTABLE" 6 "EFUSE_SELF_TEST_EFUSE_RESULT_FAILED_ENABLE_LOW_MALFUNCTION" 0 "EFUSE_SELF_TEST_EFUSE_RESULT_NOT_RUN" 8 "EFUSE_SELF_TEST_EFUSE_RESULT_FAILED_ENABLE_HIGH_MALFUNCTION" 7 "EFUSE_SELF_TEST_EFUSE_RESULT_FAILED_POWER_FET_CHANNEL_OPEN" ;
VAL_ 1332 VCFRONT_a251_UIKeepAwake 9 "UI_KEEPAWAKE_REASON_UPDATE_COUNTDOWN" 1 "UI_KEEPAWAKE_REASON_KEEPALIVEACTIVE" 2 "UI_KEEPAWAKE_REASON_GUI_NEVER_SLEEP_SET" 6 "UI_KEEPAWAKE_REASON_UPDATER" 5 "UI_KEEPAWAKE_REASON_MODEM_RESET" 0 "UI_KEEPAWAKE_REASON_NONE_SNA" 15 "UI_KEEPAWAKE_REASON_MULTIPLE" 8 "UI_KEEPAWAKE_REASON_AUTOFUSER" 4 "UI_KEEPAWAKE_REASON_UNKNOWN_REMOTE_REQUEST" 3 "UI_KEEPAWAKE_REASON_PM_CHECKING" 7 "UI_KEEPAWAKE_REASON_HERMES" 10 "UI_KEEPAWAKE_REASON_ECALL_ACTIVE" ;
VAL_ 1332 VCFRONT_a206_espSelfTest 9 "EFUSE_SELF_TEST_EFUSE_RESULT_FAILED_TURN_OFF_PATH_TOO_SLOW" 4 "EFUSE_SELF_TEST_EFUSE_RESULT_FAILED_EFUSE_OUTPUT_SHORT" 1 "EFUSE_SELF_TEST_EFUSE_RESULT_RUNNING" 10 "EFUSE_SELF_TEST_EFUSE_RESULT_FAILED_NOT_LATCHED" 2 "EFUSE_SELF_TEST_EFUSE_RESULT_PASSED" 5 "EFUSE_SELF_TEST_EFUSE_RESULT_FAILED_POWER_FET_STUCK_ON" 11 "EFUSE_SELF_TEST_EFUSE_RESULT_SKIPPED" 3 "EFUSE_SELF_TEST_EFUSE_RESULT_FAILED_RAILS_UNSTABLE" 6 "EFUSE_SELF_TEST_EFUSE_RESULT_FAILED_ENABLE_LOW_MALFUNCTION" 0 "EFUSE_SELF_TEST_EFUSE_RESULT_NOT_RUN" 8 "EFUSE_SELF_TEST_EFUSE_RESULT_FAILED_ENABLE_HIGH_MALFUNCTION" 7 "EFUSE_SELF_TEST_EFUSE_RESULT_FAILED_POWER_FET_CHANNEL_OPEN" ;
VAL_ 1332 VCFRONT_a203_epas3pSelfTest 9 "EFUSE_SELF_TEST_EFUSE_RESULT_FAILED_TURN_OFF_PATH_TOO_SLOW" 4 "EFUSE_SELF_TEST_EFUSE_RESULT_FAILED_EFUSE_OUTPUT_SHORT" 1 "EFUSE_SELF_TEST_EFUSE_RESULT_RUNNING" 10 "EFUSE_SELF_TEST_EFUSE_RESULT_FAILED_NOT_LATCHED" 2 "EFUSE_SELF_TEST_EFUSE_RESULT_PASSED" 5 "EFUSE_SELF_TEST_EFUSE_RESULT_FAILED_POWER_FET_STUCK_ON" 11 "EFUSE_SELF_TEST_EFUSE_RESULT_SKIPPED" 3 "EFUSE_SELF_TEST_EFUSE_RESULT_FAILED_RAILS_UNSTABLE" 6 "EFUSE_SELF_TEST_EFUSE_RESULT_FAILED_ENABLE_LOW_MALFUNCTION" 0 "EFUSE_SELF_TEST_EFUSE_RESULT_NOT_RUN" 8 "EFUSE_SELF_TEST_EFUSE_RESULT_FAILED_ENABLE_HIGH_MALFUNCTION" 7 "EFUSE_SELF_TEST_EFUSE_RESULT_FAILED_POWER_FET_CHANNEL_OPEN" ;
VAL_ 1332 VCFRONT_alertType 0 "ALERT_CLEARED" 1 "ALERT_SET" ;
VAL_ 1332 VCFRONT_alertID 347 "VCFRONT_a347_iboosterFastTripSlope" 116 "VCFRONT_a116_VCRIGHT_MIA" 60 "VCFRONT_a060_engineeringBuild" 104 "VCFRONT_a104_DAS_MIA" 336 "VCFRONT_a336_pcsFastTripOCMax" 150 "VCFRONT_a150_pumpBatLowRPMCBang" 168 "VCFRONT_a168_hcmShortToVBAT" 213 "VCFRONT_a213_12VOvercharge" 204 "VCFRONT_a204_epas3sSelfTestFail" 341 "VCFRONT_a341_vbatFusedFastTripOCMax" 148 "VCFRONT_a148_thmlFanSoftStall" 215 "VCFRONT_a215_airCompDriverFault" 174 "VCFRONT_a174_driveNotAuthed" 98 "VCFRONT_a098_DI_THERMAL_MIA" 230 "VCFRONT_a230_thmlFanFbkSanity" 313 "VCFRONT_a313_epas3pOvertempSlope" 325 "VCFRONT_a325_vbatFusedOvertempMax" 158 "VCFRONT_a158_louverDisconnected" 97 "VCFRONT_a097_CMP_MIA" 206 "VCFRONT_a206_espSelfTestFail" 209 "VCFRONT_a209_brakeFluidSNA" 318 "VCFRONT_a318_vcleftOvertempMax" 166 "VCFRONT_a166_rightHCMMIA" 269 "VCFRONT_a269_partialLoadShed" 44 "VCFRONT_a044_Task10msError" 321 "VCFRONT_a321_epas3pOvertempMax" 253 "VCFRONT_a253_maxChrgeSssionTmeout" 194 "VCFRONT_a194_iBoosterRetry" 115 "VCFRONT_a115_VCSEC_MIA" 22 "VCFRONT_a022_TaskInitError" 156 "VCFRONT_a156_louverBlockage" 243 "VCFRONT_a243_12VOverchargeInstc" 220 "VCFRONT_a220_reverseBatteryFault" 0 "VCFRONT_ALERT_DO_NOT_USE_ZERO" 323 "VCFRONT_a323_iboosterOvertempMax" 180 "VCFRONT_a180_12VNotSupported" 140 "VCFRONT_a140_coolantTempPtSns" 327 "VCFRONT_a327_vcrightSlowTripOC" 137 "VCFRONT_a137_refrigDischPresSns" 312 "VCFRONT_a312_pcsOvertempSlope" 207 "VCFRONT_a207_vbatFusdSelfTestFail" 231 "VCFRONT_a231_12VTempSensShort" 226 "VCFRONT_a226_railAPoweredForFrunk" 259 "VCFRONT_a259_12vVoltageDropOnHighLoadCurrent" 185 "VCFRONT_a185_washerFluidLow" 105 "VCFRONT_a105_TAS_MIA" 223 "VCFRONT_a223_12VTempSensDiscnect" 249 "VCFRONT_a249_fiveWayValveBadMode" 247 "VCFRONT_a247_evapSolenoidFault" 332 "VCFRONT_a332_espSlowTripOC" 172 "VCFRONT_a172_wsteHtBlckdByMsmtch" 167 "VCFRONT_a167_leftHCMMIA" 233 "VCFRONT_a233_autopilot1EFuseFault" 186 "VCFRONT_a186_noDriveChgCableCon" 149 "VCFRONT_a149_BLEFrontPowerCycled" 324 "VCFRONT_a324_espOvertempMax" 3 "VCFRONT_a003_SWAssertion" 261 "VCFRONT_a261_vcleftVoltageMismatch" 63 "VCFRONT_a063_SwitchFault" 43 "VCFRONT_a043_Task1msError" 339 "VCFRONT_a339_iboosterFastTripOCMax" 199 "VCFRONT_a199_PRVCANUndertrminate" 203 "VCFRONT_a203_epas3pSelfTestFail" 334 "VCFRONT_a334_vcleftFastTripOCMax" 189 "VCFRONT_a189_IBSMIA" 214 "VCFRONT_a214_airCompUnderCurrent" 195 "VCFRONT_a195_drveBlckdVltgeTooHgh" 254 "VCFRONT_a254_pumpBatStopped" 142 "VCFRONT_a142_exvMotorFault" 326 "VCFRONT_a326_vcleftSlowTripOC" 136 "VCFRONT_a136_refrigDischTempSns" 110 "VCFRONT_a110_GTW_MIA" 258 "VCFRONT_a258_resistanceEstimationRun" 118 "VCFRONT_a118_VCFRONT_MIA" 109 "VCFRONT_a109_RCM_MIA" 134 "VCFRONT_a134_fusedHighEFuseTrip" 145 "VCFRONT_a145_thmlFanICTransFault" 331 "VCFRONT_a331_iboosterSlowTripOC" 314 "VCFRONT_a314_epas3sOvertempSlope" 122 "VCFRONT_a122_pumpBatICWarning" 201 "VCFRONT_a201_vcrightSelfTestFail" 173 "VCFRONT_a173_HVBlckdByMsmtch" 340 "VCFRONT_a340_espFastTripOCMax" 147 "VCFRONT_a147_pumpPtSoftStall" 193 "VCFRONT_a193_mcuAudioRetry" 187 "VCFRONT_a187_busesNotSleeping" 171 "VCFRONT_a171_driveBlckdByMsmtch" 248 "VCFRONT_a248_voltageOutOfSpec" 143 "VCFRONT_a143_pumpBatICTransFault" 222 "VCFRONT_a222_rightTurnLightFault" 124 "VCFRONT_a124_pumpPtICWarning" 100 "VCFRONT_a100_CANbus_MIA" 236 "VCFRONT_a236_batTempSnsIrrational" 221 "VCFRONT_a221_leftTurnLightFault" 235 "VCFRONT_a235_ptTempSnsIrrational" 348 "VCFRONT_a348_espFastTripSlope" 131 "VCFRONT_a131_epas3sEFuseTrip" 161 "VCFRONT_a161_compressorSelfFault" 257 "VCFRONT_a257_portExpanderVOR" 219 "VCFRONT_a219_12VVoltFloorRchd" 343 "VCFRONT_a343_vcrightFastTripSlope" 315 "VCFRONT_a315_iboosterOvertempSlope" 31 "VCFRONT_a031_UDSActive" 159 "VCFRONT_a159_fiveWayValveFault" 337 "VCFRONT_a337_epas3pFastTripOCMax" 345 "VCFRONT_a345_epas3pFastTripSlope" 64 "VCFRONT_a064_busSleepReqTimeout" 302 "VCFRONT_a302_wiperCommError" 237 "VCFRONT_a237_pumpBatChipComms" 225 "VCFRONT_a225_driveBlckdByShowroom" 234 "VCFRONT_a234_autopilot2EFuseFault" 205 "VCFRONT_a205_iBoosterSelfTestFail" 138 "VCFRONT_a138_refrigSuctTempSns" 256 "VCFRONT_a256_compTornShaftSeal" 301 "VCFRONT_a301_wipersFactoryDisabled" 344 "VCFRONT_a344_pcsFastTripSlope" 135 "VCFRONT_a135_coolantLevelLow" 263 "VCFRONT_a263_pcsVoltageMismatch" 1 "VCFRONT_a001_WatchdogReset" 342 "VCFRONT_a342_vcleftFastTripSlope" 311 "VCFRONT_a311_vcrightOvertempSlope" 239 "VCFRONT_a239_thmlFanChipComms" 265 "VCFRONT_a265_ESPVoltageMismatch" 130 "VCFRONT_a130_epas3pEFuseTrip" 126 "VCFRONT_a126_thmlFanICWarning" 175 "VCFRONT_a175_ambientTempSns" 21 "VCFRONT_a021_TaskSchedulerError" 128 "VCFRONT_a128_vcrightEFuseTrip" 267 "VCFRONT_a267_EPAS3sVoltageMismatch" 10 "VCFRONT_a010_ExtSupplyVoltError" 99 "VCFRONT_a099_PARK_MIA" 322 "VCFRONT_a322_epas3sOvertempMax" 170 "VCFRONT_a170_hcmUnderVoltage" 15 "VCFRONT_a015_NVMMAlert" 229 "VCFRONT_a229_pumpPtFbkSanity" 268 "VCFRONT_a268_vbatFusedVoltageMismatch" 317 "VCFRONT_a317_vbatFusedOvertempSlope" 182 "VCFRONT_a182_replace12VBattery" 335 "VCFRONT_a335_vcrightFastTripOCMax" 198 "VCFRONT_a198_PRVCANOverterminate" 121 "VCFRONT_a121_pumpBatICLatchFault" 144 "VCFRONT_a144_pumpPtICTransFault" 320 "VCFRONT_a320_pcsOvertempMax" 251 "VCFRONT_a251_UIWakeupTrigger" 120 "VCFRONT_a120_DI_DRIVE_MIA" 101 "VCFRONT_a101_PM_MIA" 333 "VCFRONT_a333_vbatFusedSlowTripOC" 183 "VCFRONT_a183_low12VCapacity" 59 "VCFRONT_a059_inputResistanceHigh" 255 "VCFRONT_a255_pumpPtStopped" 245 "VCFRONT_a245_pump1EFuseFault" 329 "VCFRONT_a329_epas3pSlowTripOC" 228 "VCFRONT_a228_pumpBatFbkSanity" 211 "VCFRONT_a211_I2CFault" 157 "VCFRONT_a157_louverBreakage" 202 "VCFRONT_a202_pcsSelfTestFail" 114 "VCFRONT_a114_ESP_MIA" 165 "VCFRONT_a165_unxpctdEFuseLckout" 319 "VCFRONT_a319_vcrightOvertempMax" 246 "VCFRONT_a246_pump2EFuseFault" 133 "VCFRONT_a133_espEFuseTrip" 12 "VCFRONT_a012_CPUReset" 152 "VCFRONT_a152_thmlFanLowRPMCBang" 238 "VCFRONT_a238_pumpPtChipComms" 46 "VCFRONT_a046_Task1000msError" 266 "VCFRONT_a266_EPAS3pVoltageMismatch" 107 "VCFRONT_a107_BMS_MIA" 125 "VCFRONT_a125_thmlFanICLatchFault" 260 "VCFRONT_a260_dead12VBattery" 179 "VCFRONT_a179_highLVAmpsIntoPCS" 338 "VCFRONT_a338_epas3sFastTripOCMax" 262 "VCFRONT_a262_vcrightVoltageMismatch" 164 "VCFRONT_a164_eFuseLckoutMissing" 188 "VCFRONT_a188_sleepFailed" 264 "VCFRONT_a264_iBoosterVoltageMismatch" 192 "VCFRONT_a192_criticalLoadShed" 106 "VCFRONT_a106_PCS_MIA" 108 "VCFRONT_a108_DIS_MIA" 210 "VCFRONT_a210_fiveWayValveCalib" 62 "VCFRONT_a062_XCPWasConnected" 328 "VCFRONT_a328_pcsSlowTripOC" 113 "VCFRONT_a113_UI_MIA" 176 "VCFRONT_a176_vehicleInSelfTest" 316 "VCFRONT_a316_espOvertempSlope" 139 "VCFRONT_a139_refrigSuctPresSns" 250 "VCFRONT_a250_headlampsNotAimed" 127 "VCFRONT_a127_vcleftEFuseTrip" 13 "VCFRONT_a013_AlertManagerFault" 244 "VCFRONT_a244_sleepBypassFault" 119 "VCFRONT_a119_SCCM_MIA" 252 "VCFRONT_a252_frontControllerWakeup" 141 "VCFRONT_a141_coolantTempBatSns" 129 "VCFRONT_a129_pcsEFuseTrip" 123 "VCFRONT_a123_pumpPtICLatchFault" 102 "VCFRONT_a102_PTC_MIA" 196 "VCFRONT_a196_discnctd12VBattery" 111 "VCFRONT_a111_EPBR_MIA" 30 "VCFRONT_a030_ECULogUploadRequest" 177 "VCFRONT_a177_mcuAudioEFuseFault" 151 "VCFRONT_a151_pumpPtLowRPMCBang" 61 "VCFRONT_a061_XCPConnected" 112 "VCFRONT_a112_EPBL_MIA" 45 "VCFRONT_a045_Task100msError" 42 "VCFRONT_a042_HighStackUsage" 208 "VCFRONT_a208_brakeFluidLow" 117 "VCFRONT_a117_VCLEFT_MIA" 330 "VCFRONT_a330_epas3sSlowTripOC" 2 "VCFRONT_a002_PowerLossReset" 41 "VCFRONT_a041_HighCPULoad" 103 "VCFRONT_a103_CP_MIA" 310 "VCFRONT_a310_vcleftOvertempSlope" 212 "VCFRONT_a212_IBSOverTemp" 224 "VCFRONT_a224_revBatChrgPmpFault" 283 "VCFRONT_a283_thmlFanLimitedByCurrent" 200 "VCFRONT_a200_vcleftSelfTestFail" 346 "VCFRONT_a346_epas3sFastTripSlope" 191 "VCFRONT_a191_exitDriveLow12V" 160 "VCFRONT_a160_compressorInhibited" 349 "VCFRONT_a349_vbatFusedFastTripSlope" 169 "VCFRONT_a169_hcmPhaseEnableFail" 146 "VCFRONT_a146_pumpBatSoftStall" 132 "VCFRONT_a132_iBoosterEFuseTrip" ;
VAL_ 2047 GTW_eCallEnabled 1 "ENABLED" 0 "DISABLED" ;
VAL_ 2047 GTW_trackModePackage 0 "NONE" 1 "PERFORMANCE" ;
VAL_ 2047 GTW_roofGlassType 1 "TSA5_NOPET" 0 "TSA3_PET" ;
VAL_ 2047 GTW_restraintsHardwareType 23 "M3_EUROW_NO_ECALL" 22 "M3_EUROW_ECALL" 21 "M3_NA" ;
VAL_ 2047 GTW_brakeHWType 1 "BREMBO_P42_BREMBO_44MOC" 0 "BREMBO_P42_MANDO_43MOC" ;
VAL_ 2047 GTW_pedestrianWarningSound 0 "NONE" 1 "SPEAKER" ;
VAL_ 2047 GTW_numberHVILNodes 0 "HVIL_NODES_0" 1 "HVIL_NODES_1" 4 "HVIL_NODES_4" 2 "HVIL_NODES_2" 5 "HVIL_NODES_5" 3 "HVIL_NODES_3" ;
VAL_ 2047 GTW_exteriorColor 2 "SILVER_METALLIC" 3 "MIDNIGHT_SILVER" 0 "RED_MULTICOAT" 6 "PEARL_WHITE" 1 "SOLID_BLACK" 5 "DEEP_BLUE" ;
VAL_ 2047 GTW_wheelType 2 "STILETTO_20" 1 "STILETTO_19" 0 "PINWHEEL_18" 3 "STILETTO_20_STAGGERED" ;
VAL_ 2047 GTW_superchargingAccess 2 "PAY_AS_YOU_GO" 0 "NOT_ALLOWED" 1 "ALLOWED" ;
VAL_ 2047 GTW_autopilot 0 "NONE" 3 "SELF_DRIVING" 2 "ENHANCED" 1 "HIGHWAY" ;
VAL_ 2047 GTW_dasHw 3 "PARKER_PASCAL_2_5" 4 "TESLA_AP3" ;
VAL_ 2047 GTW_roofType 0 "METAL" 2 "PANORAMIC" 1 "FIXED_GLASS" ;
VAL_ 2047 GTW_rearFogLamps 0 "NOT_INSTALLED" 1 "INSTALLED" ;
VAL_ 2047 GTW_rearGlassType 1 "TSA5_NOPET" 0 "NX" ;
VAL_ 2047 GTW_spoilerType 1 "PASSIVE" 0 "NOT_INSTALLED" ;
VAL_ 2047 GTW_intrusionSensorType 1 "VODAFONE" 0 "NOT_INSTALLED" ;
VAL_ 2047 GTW_airbagCutoffSwitch 0 "CUTOFF_SWITCH_DISABLED" 1 "CUTOFF_SWITCH_ENABLED" ;
VAL_ 2047 GTW_activeHighBeam 0 "NOT_ACTIVE" 1 "ACTIVE" ;
VAL_ 2047 GTW_windshieldType 0 "SEKISUI_ACOUSTIC" 1 "EASTMAN_ACOUSTIC" ;
VAL_ 2047 GTW_tireType 4 "CONTI_ALL_SEASON_19" 5 "MICHELIN_SUMMER_20" 0 "UNKNOWN" 1 "MICHELIN_ALL_SEASON_18" 3 "HANKOOK_SUMMER_19" 2 "MICHELIN_SUMMER_18" ;
VAL_ 2047 GTW_eBuckConfig 0 "NONE" 1 "DEV_BUCK" ;
VAL_ 2047 GTW_performancePackage 0 "BASE" 1 "PERFORMANCE" ;
VAL_ 2047 GTW_CabinBlowerCtrlType 1 "TMS320F28027F" 0 "LV8907" ;
VAL_ 2047 GTW_hvacPanelVaneType 0 "PARALLEL_V1" 1 "CONVERGENT_V1" ;
VAL_ 2047 GTW_hvacQuietSnorkelType 0 "DEFAULT" 1 "QUIET_V1" ;
VAL_ 2047 GTW_auxParkLamps 0 "NA_BASE" 2 "EU" 1 "NA_PREMIUM" ;
VAL_ 2047 GTW_frontSeatType 0 "TESLA_BASE" 1 "TESLA_PREMIUM" ;
VAL_ 2047 GTW_ibstWakeType 0 "NONE" 1 "WAKE_PIN_20" ;
VAL_ 2047 GTW_lumbarECUType 0 "NONE" 1 "ALFMEIER" ;
VAL_ 2047 GTW_audioType 0 "BASE" 1 "PREMIUM" ;
VAL_ 2047 GTW_headlamps 0 "BASE" 1 "PREMIUM" ;
VAL_ 2047 GTW_frontFogLamps 0 "NOT_INSTALLED" 1 "INSTALLED" ;
VAL_ 2047 GTW_interiorLighting 0 "BASE" 1 "PREMIUM" ;
VAL_ 2047 GTW_powerSteeringColumn 1 "TK" 0 "NOT_INSTALLED" ;
VAL_ 2047 GTW_memoryMirrors 1 "SMR" 0 "NOT_INSTALLED" ;
VAL_ 2047 GTW_rearLightType 0 "NA" 1 "EU_CN" ;
VAL_ 2047 GTW_xcpESP 0 "FALSE" 1 "TRUE" ;
VAL_ 2047 GTW_xcpIbst 0 "FALSE" 1 "TRUE" ;
VAL_ 2047 GTW_vdcType 1 "TESLA_VDC" 0 "BOSCH_VDC" ;
VAL_ 2047 GTW_homelinkType 0 "NONE" 1 "HOMELINK_V_OPT_2" ;
VAL_ 2047 GTW_rightHandDrive 0 "LEFT" 1 "RIGHT" ;
VAL_ 2047 GTW_packEnergy 0 "PACK_50_KWH" 1 "PACK_74_KWH" 2 "PACK_62_KWH" ;
VAL_ 2047 GTW_rearSeatHeaters 0 "NONE" 1 "KONGSBERG_LOW_POWER" ;
VAL_ 2047 GTW_drivetrainType 1 "AWD" 0 "RWD" ;
VAL_ 2047 GTW_epasType 0 "MANDO_VGR69_GEN3" ;
VAL_ 2047 GTW_frontSeatHeaters 0 "NONE" 1 "KONGSBERG_LOW_POWER" ;
VAL_ 2047 GTW_mapRegion 4 "AU" 2 "NONE" 5 "JP" 8 "ME" 0 "US" 7 "KR" 3 "CN" 1 "EU" 6 "TW" ;
VAL_ 2047 GTW_heatedWipers 0 "FALSE" 1 "TRUE" ;
VAL_ 2047 GTW_airSuspension 0 "NONE" 1 "TESLA_STANDARD" ;
